VERSION "ZCUD_CANFD3"

NS_ :

BS_:

BU_: ASDM ETC HVFM SRS3 SUM XCM ZCUD ZCUT

BO_ 1418 EtcToSumXcpFr01: 8 ETC

BO_ 1604 HvfmToZcudZCUDCANFD3DiagResFr: 64 HVFM
 SG_ HvfmToZcudZCUCanFD3DiagResNpdu : 7|512@0+ (1,0) [0|0] "" ZCUD

BO_ 769 HvfmZCUDCANFD3Fr01: 64 HVFM
 SG_ HvFanACLockFlt : 7|1@0+ (1,0) [0|1] "Unitless" XCM
 SG_ HvFanACLockFlt_UB : 6|1@0+ (1,0) [0|1] "" XCM
 SG_ HvFanActPwr : 71|10@0+ (20,0) [0|20460] "W" XCM
 SG_ HvFanActPwr_UB : 77|1@0+ (1,0) [0|1] "" XCM
 SG_ HvFanBlockFlt : 41|1@0+ (1,0) [0|1] "Unitless" XCM
 SG_ HvFanBlockFlt_UB : 40|1@0+ (1,0) [0|1] "" XCM
 SG_ HvFanBusOffFlt : 57|1@0+ (1,0) [0|1] "Unitless" XCM
 SG_ HvFanBusOffFlt_UB : 56|1@0+ (1,0) [0|1] "" XCM
 SG_ HvFanCalFlt : 81|1@0+ (1,0) [0|1] "Unitless" XCM
 SG_ HvFanCalFlt_UB : 80|1@0+ (1,0) [0|1] "" XCM
 SG_ HvFanChks : 135|8@0+ (1,0) [0|255] "Unitless" XCM
 SG_ HvFanChks_UB : 0|1@0+ (1,0) [0|1] "" XCM
 SG_ HvFanCntr : 5|4@0+ (1,0) [0|15] "Unitless" XCM
 SG_ HvFanCntr_UB : 1|1@0+ (1,0) [0|1] "" XCM
 SG_ HvFanControllerT : 143|8@0+ (1,-40) [-40|215] "degC" XCM
 SG_ HvFanControllerT_UB : 168|1@0+ (1,0) [0|1] "" XCM
 SG_ HvFanCurrentIctrlFlt : 105|1@0+ (1,0) [0|1] "Unitless" XCM
 SG_ HvFanCurrentIctrlFlt_UB : 104|1@0+ (1,0) [0|1] "" XCM
 SG_ HvFanCurrentIsOCFlt : 121|1@0+ (1,0) [0|1] "Unitless" XCM
 SG_ HvFanCurrentIsOCFlt_UB : 120|1@0+ (1,0) [0|1] "" XCM
 SG_ HvFanCurrentSumFlt : 172|1@0+ (1,0) [0|1] "Unitless" XCM
 SG_ HvFanCurrentSumFlt_UB : 171|1@0+ (1,0) [0|1] "" XCM
 SG_ HvFanDCBusOVFlt : 170|1@0+ (1,0) [0|1] "Unitless" XCM
 SG_ HvFanDCBusOVFlt_UB : 169|1@0+ (1,0) [0|1] "" XCM
 SG_ HvFanDCBusOVWarn : 183|1@0+ (1,0) [0|1] "Unitless" XCM
 SG_ HvFanDCBusOVWarn_UB : 182|1@0+ (1,0) [0|1] "" XCM
 SG_ HvFanDCBusUVFlt : 181|1@0+ (1,0) [0|1] "Unitless" XCM
 SG_ HvFanDCBusUVFlt_UB : 180|1@0+ (1,0) [0|1] "" XCM
 SG_ HvFanDCBusUVWarn : 179|1@0+ (1,0) [0|1] "Unitless" XCM
 SG_ HvFanDCBusUVWarn_UB : 178|1@0+ (1,0) [0|1] "" XCM
 SG_ HvFanDCCrt : 76|10@0+ (0.1,0) [0|102.3] "A" XCM
 SG_ HvFanDCCrt_UB : 82|1@0+ (1,0) [0|1] "" XCM
 SG_ HvFanDCLockFlt : 177|1@0+ (1,0) [0|1] "Unitless" XCM
 SG_ HvFanDCLockFlt_UB : 176|1@0+ (1,0) [0|1] "" XCM
 SG_ HvFanDCVolt : 39|13@0+ (0.2,0) [0|1200] "Volt" XCM
 SG_ HvFanDCVolt_UB : 42|1@0+ (1,0) [0|1] "" XCM
 SG_ HvFanDriveFlt : 191|1@0+ (1,0) [0|1] "Unitless" XCM
 SG_ HvFanDriveFlt_UB : 190|1@0+ (1,0) [0|1] "" XCM
 SG_ HvFanFaultClass : 124|2@0+ (1,0) [0|3] "Unitless" XCM
 SG_ HvFanFaultClass_UB : 122|1@0+ (1,0) [0|1] "" XCM
 SG_ HvFanFltNum : 15|24@0+ (1,0) [0|16777215] "Unitless" XCM
 SG_ HvFanFltNum_UB : 221|1@0+ (1,0) [0|1] "" XCM
 SG_ HvFanHeartBeatFlt : 189|1@0+ (1,0) [0|1] "Unitless" XCM
 SG_ HvFanHeartBeatFlt_UB : 188|1@0+ (1,0) [0|1] "" XCM
 SG_ HvFanHVLKFlt : 187|1@0+ (1,0) [0|1] "" XCM
 SG_ HvFanHVLKFlt_UB : 186|1@0+ (1,0) [0|1] "" XCM
 SG_ HvFanHWProtectFlt : 185|1@0+ (1,0) [0|1] "Unitless" XCM
 SG_ HvFanHWProtectFlt_UB : 184|1@0+ (1,0) [0|1] "" XCM
 SG_ HvFanInverterOTFlt : 199|1@0+ (1,0) [0|1] "Unitless" XCM
 SG_ HvFanInverterOTFlt_UB : 198|1@0+ (1,0) [0|1] "" XCM
 SG_ HvFanInverterOTWarn : 197|1@0+ (1,0) [0|1] "Unitless" XCM
 SG_ HvFanInverterOTWarn_UB : 196|1@0+ (1,0) [0|1] "" XCM
 SG_ HvFanLifebeat : 195|1@0+ (1,0) [0|1] "" XCM
 SG_ HvFanLifebeat_UB : 194|1@0+ (1,0) [0|1] "" XCM
 SG_ HvFanLVSupOVFlt : 193|1@0+ (1,0) [0|1] "Unitless" XCM
 SG_ HvFanLVSupOVFlt_UB : 192|1@0+ (1,0) [0|1] "" XCM
 SG_ HvFanLVSupUVFlt : 207|1@0+ (1,0) [0|1] "Unitless" XCM
 SG_ HvFanLVSupUVFlt_UB : 206|1@0+ (1,0) [0|1] "" XCM
 SG_ HvFanMotCrt : 95|10@0+ (0.1,0) [0|102.3] "A" XCM
 SG_ HvFanMotCrt_UB : 101|1@0+ (1,0) [0|1] "" XCM
 SG_ HvFanMotPwr : 100|10@0+ (20,0) [0|20460] "W" XCM
 SG_ HvFanMotPwr_UB : 106|1@0+ (1,0) [0|1] "" XCM
 SG_ HvFanMotT : 151|8@0+ (1,-40) [-40|215] "degC" XCM
 SG_ HvFanMotT_UB : 220|1@0+ (1,0) [0|1] "" XCM
 SG_ HvFanMotVolt : 55|13@0+ (0.2,0) [0|1200] "Volt" XCM
 SG_ HvFanMotVolt_UB : 58|1@0+ (1,0) [0|1] "" XCM
 SG_ HvFanNoCal : 205|1@0+ (1,0) [0|1] "Unitless" XCM
 SG_ HvFanNoCal_UB : 204|1@0+ (1,0) [0|1] "" XCM
 SG_ HvFanOSFlt : 203|1@0+ (1,0) [0|1] "Unitless" XCM
 SG_ HvFanOSFlt_UB : 202|1@0+ (1,0) [0|1] "" XCM
 SG_ HvFanOSWarn : 201|1@0+ (1,0) [0|1] "Unitless" XCM
 SG_ HvFanOSWarn_UB : 200|1@0+ (1,0) [0|1] "" XCM
 SG_ HvFanOTFlt : 215|1@0+ (1,0) [0|1] "Unitless" XCM
 SG_ HvFanOTFlt_UB : 214|1@0+ (1,0) [0|1] "" XCM
 SG_ HvFanOTWarm : 213|1@0+ (1,0) [0|1] "Unitless" XCM
 SG_ HvFanOTWarm_UB : 212|1@0+ (1,0) [0|1] "" XCM
 SG_ HvFanPhaseOCFlt : 211|1@0+ (1,0) [0|1] "Unitless" XCM
 SG_ HvFanPhaseOCFlt_UB : 210|1@0+ (1,0) [0|1] "" XCM
 SG_ HvFanPwrReq : 119|10@0+ (20,0) [0|20460] "W" XCM
 SG_ HvFanPwrReq_UB : 125|1@0+ (1,0) [0|1] "" XCM
 SG_ HvFanSpdFb : 159|7@0+ (1,0) [0|100] "%" XCM
 SG_ HvFanSpdFb_UB : 152|1@0+ (1,0) [0|1] "" XCM
 SG_ HvFanStartFlt : 209|1@0+ (1,0) [0|1] "Unitless" XCM
 SG_ HvFanStartFlt_UB : 208|1@0+ (1,0) [0|1] "" XCM
 SG_ HvFanSts : 175|2@0+ (1,0) [0|3] "Unitless" XCM
 SG_ HvFanSts_UB : 173|1@0+ (1,0) [0|1] "" XCM
 SG_ HvFanTotFltNum : 167|8@0+ (1,0) [0|255] "Unitless" XCM
 SG_ HvFanTotFltNum_UB : 219|1@0+ (1,0) [0|1] "" XCM
 SG_ HvFanWindOSWarn : 223|1@0+ (1,0) [0|1] "Unitless" XCM
 SG_ HvFanWindOSWarn_UB : 222|1@0+ (1,0) [0|1] "" XCM
 SG_ HVFMMissingSlaveSignal : 218|1@0+ (1,0) [0|1] "" ZCUD
 SG_ HVFMMissingSlaveSignal_UB : 217|1@0+ (1,0) [0|1] "" ZCUD

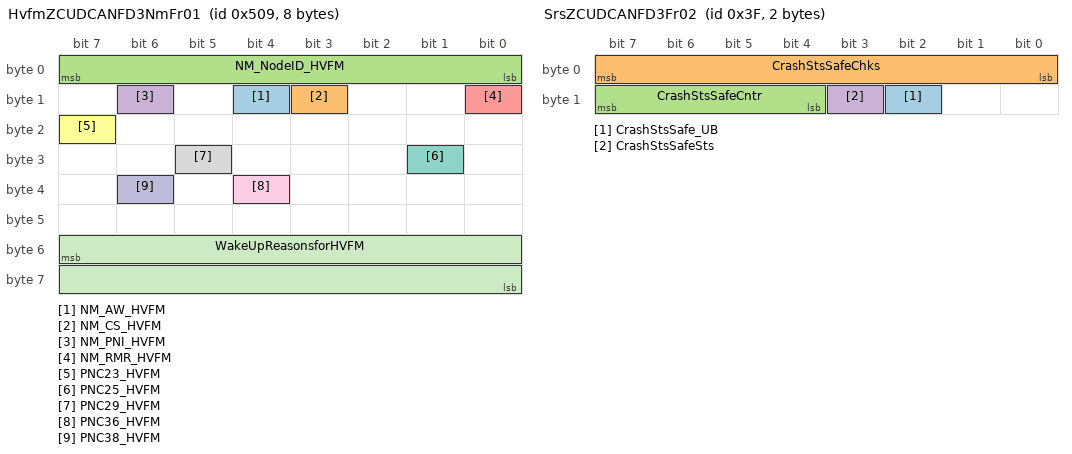
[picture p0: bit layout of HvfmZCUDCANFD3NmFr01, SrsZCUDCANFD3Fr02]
BO_ 1289 HvfmZCUDCANFD3NmFr01: 8 HVFM
 SG_ NM_AW_HVFM : 12|1@0+ (1,0) [0|0] "" ZCUT
 SG_ NM_CS_HVFM : 11|1@0+ (1,0) [0|0] "" ZCUT
 SG_ NM_NodeID_HVFM : 7|8@0+ (1,0) [0|0] "" ZCUT
 SG_ NM_PNI_HVFM : 14|1@0+ (1,0) [0|0] "" ZCUT
 SG_ NM_RMR_HVFM : 8|1@0+ (1,0) [0|0] "" ZCUT
 SG_ PNC23_HVFM : 23|1@0+ (1,0) [0|0] "" ZCUT
 SG_ PNC25_HVFM : 25|1@0+ (1,0) [0|0] "" ZCUT
 SG_ PNC29_HVFM : 29|1@0+ (1,0) [0|0] "" ZCUT
 SG_ PNC36_HVFM : 36|1@0+ (1,0) [0|0] "" ZCUT
 SG_ PNC38_HVFM : 38|1@0+ (1,0) [0|0] "" ZCUT
 SG_ WakeUpReasonsforHVFM : 55|16@0+ (1,0) [0|65535] "" Vector__XXX

BO_ 1353 HvfmZCUDCANFD3VFCVectorFr: 8 HVFM
 SG_ VFCVectorHVFMBlockID : 7|2@0+ (1,0) [0|3] "Unitless" ZCUD
 SG_ VFCVectorHVFMVFCid0 : 5|1@0+ (1,0) [0|1] "" ZCUD
 SG_ VFCVectorHVFMVFCid1 : 4|1@0+ (1,0) [0|1] "" ZCUD
 SG_ VFCVectorHVFMVFCid10 : 11|1@0+ (1,0) [0|1] "" ZCUD
 SG_ VFCVectorHVFMVFCid11 : 10|1@0+ (1,0) [0|1] "" ZCUD
 SG_ VFCVectorHVFMVFCid12 : 9|1@0+ (1,0) [0|1] "" ZCUD
 SG_ VFCVectorHVFMVFCid13 : 8|1@0+ (1,0) [0|1] "" ZCUD
 SG_ VFCVectorHVFMVFCid14 : 23|1@0+ (1,0) [0|1] "" ZCUD
 SG_ VFCVectorHVFMVFCid15 : 22|1@0+ (1,0) [0|1] "" ZCUD
 SG_ VFCVectorHVFMVFCid16 : 21|1@0+ (1,0) [0|1] "" ZCUD
 SG_ VFCVectorHVFMVFCid17 : 20|1@0+ (1,0) [0|1] "" ZCUD
 SG_ VFCVectorHVFMVFCid18 : 19|1@0+ (1,0) [0|1] "" ZCUD
 SG_ VFCVectorHVFMVFCid19 : 18|1@0+ (1,0) [0|1] "" ZCUD
 SG_ VFCVectorHVFMVFCid2 : 3|1@0+ (1,0) [0|1] "" ZCUD
 SG_ VFCVectorHVFMVFCid20 : 17|1@0+ (1,0) [0|1] "" ZCUD
 SG_ VFCVectorHVFMVFCid21 : 16|1@0+ (1,0) [0|1] "" ZCUD
 SG_ VFCVectorHVFMVFCid22 : 31|1@0+ (1,0) [0|1] "" ZCUD
 SG_ VFCVectorHVFMVFCid23 : 30|1@0+ (1,0) [0|1] "" ZCUD
 SG_ VFCVectorHVFMVFCid24 : 29|1@0+ (1,0) [0|1] "" ZCUD
 SG_ VFCVectorHVFMVFCid25 : 28|1@0+ (1,0) [0|1] "" ZCUD
 SG_ VFCVectorHVFMVFCid26 : 27|1@0+ (1,0) [0|1] "" ZCUD
 SG_ VFCVectorHVFMVFCid27 : 26|1@0+ (1,0) [0|1] "" ZCUD
 SG_ VFCVectorHVFMVFCid28 : 25|1@0+ (1,0) [0|1] "" ZCUD
 SG_ VFCVectorHVFMVFCid29 : 24|1@0+ (1,0) [0|1] "" ZCUD
 SG_ VFCVectorHVFMVFCid3 : 2|1@0+ (1,0) [0|1] "" ZCUD
 SG_ VFCVectorHVFMVFCid30 : 39|1@0+ (1,0) [0|1] "" ZCUD
 SG_ VFCVectorHVFMVFCid31 : 38|1@0+ (1,0) [0|1] "" ZCUD
 SG_ VFCVectorHVFMVFCid32 : 37|1@0+ (1,0) [0|1] "" ZCUD
 SG_ VFCVectorHVFMVFCid33 : 36|1@0+ (1,0) [0|1] "" ZCUD
 SG_ VFCVectorHVFMVFCid34 : 35|1@0+ (1,0) [0|1] "" ZCUD
 SG_ VFCVectorHVFMVFCid35 : 34|1@0+ (1,0) [0|1] "" ZCUD
 SG_ VFCVectorHVFMVFCid36 : 33|1@0+ (1,0) [0|1] "" ZCUD
 SG_ VFCVectorHVFMVFCid37 : 32|1@0+ (1,0) [0|1] "" ZCUD
 SG_ VFCVectorHVFMVFCid38 : 47|1@0+ (1,0) [0|1] "" ZCUD
 SG_ VFCVectorHVFMVFCid39 : 46|1@0+ (1,0) [0|1] "" ZCUD
 SG_ VFCVectorHVFMVFCid4 : 1|1@0+ (1,0) [0|1] "" ZCUD
 SG_ VFCVectorHVFMVFCid40 : 45|1@0+ (1,0) [0|1] "" ZCUD
 SG_ VFCVectorHVFMVFCid41 : 44|1@0+ (1,0) [0|1] "" ZCUD
 SG_ VFCVectorHVFMVFCid42 : 43|1@0+ (1,0) [0|1] "" ZCUD
 SG_ VFCVectorHVFMVFCid43 : 42|1@0+ (1,0) [0|1] "" ZCUD
 SG_ VFCVectorHVFMVFCid44 : 41|1@0+ (1,0) [0|1] "" ZCUD
 SG_ VFCVectorHVFMVFCid45 : 40|1@0+ (1,0) [0|1] "" ZCUD
 SG_ VFCVectorHVFMVFCid46 : 55|1@0+ (1,0) [0|1] "" ZCUD
 SG_ VFCVectorHVFMVFCid47 : 54|1@0+ (1,0) [0|1] "" ZCUD
 SG_ VFCVectorHVFMVFCid48 : 53|1@0+ (1,0) [0|1] "" ZCUD
 SG_ VFCVectorHVFMVFCid49 : 52|1@0+ (1,0) [0|1] "" ZCUD
 SG_ VFCVectorHVFMVFCid5 : 0|1@0+ (1,0) [0|1] "" ZCUD
 SG_ VFCVectorHVFMVFCid50 : 51|1@0+ (1,0) [0|1] "" ZCUD
 SG_ VFCVectorHVFMVFCid51 : 50|1@0+ (1,0) [0|1] "" ZCUD
 SG_ VFCVectorHVFMVFCid52 : 49|1@0+ (1,0) [0|1] "" ZCUD
 SG_ VFCVectorHVFMVFCid53 : 48|1@0+ (1,0) [0|1] "" ZCUD
 SG_ VFCVectorHVFMVFCid54 : 63|1@0+ (1,0) [0|1] "" ZCUD
 SG_ VFCVectorHVFMVFCid55 : 62|1@0+ (1,0) [0|1] "" ZCUD
 SG_ VFCVectorHVFMVFCid56 : 61|1@0+ (1,0) [0|1] "" ZCUD
 SG_ VFCVectorHVFMVFCid57 : 60|1@0+ (1,0) [0|1] "" ZCUD
 SG_ VFCVectorHVFMVFCid58 : 59|1@0+ (1,0) [0|1] "" ZCUD
 SG_ VFCVectorHVFMVFCid59 : 58|1@0+ (1,0) [0|1] "" ZCUD
 SG_ VFCVectorHVFMVFCid6 : 15|1@0+ (1,0) [0|1] "" ZCUD
 SG_ VFCVectorHVFMVFCid60 : 57|1@0+ (1,0) [0|1] "" ZCUD
 SG_ VFCVectorHVFMVFCid61 : 56|1@0+ (1,0) [0|1] "" ZCUD
 SG_ VFCVectorHVFMVFCid7 : 14|1@0+ (1,0) [0|1] "" ZCUD
 SG_ VFCVectorHVFMVFCid8 : 13|1@0+ (1,0) [0|1] "" ZCUD
 SG_ VFCVectorHVFMVFCid9 : 12|1@0+ (1,0) [0|1] "" ZCUD

BO_ 81 IemZCUDCANFD3Fr02: 64 XCM
 SG_ TVCBrkTqReq_UB : 203|1@0+ (1,0) [0|1] "" ZCUD
 SG_ TVCBrkTqReqChks : 191|8@0+ (1,0) [0|255] "Unitless" ZCUD
 SG_ TVCBrkTqReqCntr : 199|4@0+ (1,0) [0|15] "Unitless" ZCUD
 SG_ TVCBrkTqReqFrntLe : 143|12@0+ (4,0) [0|16380] "Nm" ZCUD
 SG_ TVCBrkTqReqFrntLeCtrlMod : 195|2@0+ (1,0) [0|3] "" ZCUD
 SG_ TVCBrkTqReqFrntRi : 147|12@0+ (4,0) [0|16380] "Nm" ZCUD
 SG_ TVCBrkTqReqFrntRiCtrlMod : 193|2@0+ (1,0) [0|3] "" ZCUD
 SG_ TVCBrkTqReqReLe : 167|12@0+ (4,0) [0|16380] "Nm" ZCUD
 SG_ TVCBrkTqReqReLeCtrlMod : 207|2@0+ (1,0) [0|3] "" ZCUD
 SG_ TVCBrkTqReqReRi : 171|12@0+ (4,0) [0|16380] "Nm" ZCUD
 SG_ TVCBrkTqReqReRiCtrlMod : 205|2@0+ (1,0) [0|3] "" ZCUD
 SG_ TVCBrkTqReqWhlVAgrMinReqFrntLe : 79|16@0- (0.0078125,0) [-255|255] "rad/s" ZCUD
 SG_ TVCBrkTqReqWhlVAgrMinReqFrntRi : 95|16@0- (0.0078125,0) [-255|255] "rad/s" ZCUD
 SG_ TVCBrkTqReqWhlVAgrMinReqReLe : 111|16@0- (0.0078125,0) [-255|255] "rad/s" ZCUD
 SG_ TVCBrkTqReqWhlVAgrMinReqReRi : 127|16@0- (0.0078125,0) [-255|255] "rad/s" ZCUD
 SG_ TVCPrpsnTqDistActv : 25|1@0+ (1,0) [0|1] "" ZCUD
 SG_ TVCPrpsnTqDistActv_UB : 24|1@0+ (1,0) [0|1] "" ZCUD
 SG_ TVCPrpsnTqDistRatio : 55|8@0+ (1,0) [0|100] "%" ZCUD
 SG_ TVCPrpsnTqDistRatio_UB : 63|1@0+ (1,0) [0|1] "" ZCUD
 SG_ TVCReWhlSteerCtrlStsForTvc_UB : 40|1@0+ (1,0) [0|1] "" ZCUD
 SG_ TVCReWhlSteerCtrlStsForTvcChks : 39|8@0+ (1,0) [0|255] "Unitless" ZCUD
 SG_ TVCReWhlSteerCtrlStsForTvcCntr : 47|4@0+ (1,0) [0|15] "Unitless" ZCUD
 SG_ TVCReWhlSteerCtrlStsForTvcTVCReWhlSteerCtrlStsForTvc : 43|3@0+ (1,0) [0|7] "" ZCUD
 SG_ TVCRwsAngReqForTvc_UB : 28|1@0+ (1,0) [0|1] "" ZCUD
 SG_ TVCRwsAngReqForTvcChks : 8|8@0+ (1,0) [0|255] "Unitless" ZCUD
 SG_ TVCRwsAngReqForTvcCntr : 16|4@0+ (1,0) [0|15] "Unitless" ZCUD
 SG_ TVCRwsAngReqForTvcTVCRwsAngReqForTvc : 7|15@0- (0.001,0) [-16.384|16.383] "Deg" ZCUD
 SG_ TVCTqDistbnFaultForGVMC_UB : 62|1@0+ (1,0) [0|1] "" ZCUD
 SG_ TVCTqDistbnFaultForGVMCChks : 71|8@0+ (1,0) [0|255] "Unitless" ZCUD
 SG_ TVCTqDistbnFaultForGVMCCntr : 61|4@0+ (1,0) [0|15] "Unitless" ZCUD
 SG_ TVCTqDistbnFaultForGVMCTVCTqDistbnFaultForGVMC : 57|2@0+ (1,0) [0|3] "" ZCUD

BO_ 257 IemZCUDCANFD3Fr03: 64 XCM
 SG_ FasPwrAllwd : 207|9@0+ (100,0) [0|51100] "W" ZCUT
 SG_ FasPwrAllwd_UB : 214|1@0+ (1,0) [0|1] "" ZCUT
 SG_ MotDynCtrlStsReLe_UB : 87|1@0+ (1,0) [0|1] "" ZCUD,ZCUT
 SG_ MotDynCtrlStsReLeChks : 143|8@0+ (1,0) [0|255] "Unitless" ZCUD,ZCUT
 SG_ MotDynCtrlStsReLeCntr : 151|4@0+ (1,0) [0|15] "Unitless" ZCUD,ZCUT
 SG_ MotDynCtrlStsReLeDmcActAppTarTq : 111|16@0- (1,0) [-30000|30000] "NewtonMeter" ZCUD,ZCUT
 SG_ MotDynCtrlStsReLeDmcSts : 147|4@0+ (1,0) [0|15] "" ZCUD,ZCUT
 SG_ MotDynCtrlStsReLeDmcSWInfo : 127|16@0+ (1,0) [0|65535] "Unitless" ZCUD,ZCUT
 SG_ MotDynCtrlStsReRi_UB : 86|1@0+ (1,0) [0|1] "" ZCUD,ZCUT
 SG_ MotDynCtrlStsReRiChks : 191|8@0+ (1,0) [0|255] "Unitless" ZCUD,ZCUT
 SG_ MotDynCtrlStsReRiCntr : 199|4@0+ (1,0) [0|15] "Unitless" ZCUD,ZCUT
 SG_ MotDynCtrlStsReRiDmcActAppTarTq : 159|16@0- (1,0) [-30000|30000] "NewtonMeter" ZCUD,ZCUT
 SG_ MotDynCtrlStsReRiDmcSts : 195|4@0+ (1,0) [0|15] "" ZCUD,ZCUT
 SG_ MotDynCtrlStsReRiDmcSWInfo : 175|16@0+ (1,0) [0|65535] "Unitless" ZCUD,ZCUT
 SG_ TVCEradLeMaxAvailWhl : 7|12@0+ (4,-8188) [-8188|8192] "NewtonMeter" ZCUD
 SG_ TVCEradLeMaxAvailWhl_UB : 88|1@0+ (1,0) [0|1] "" ZCUD
 SG_ TVCEradLeMinAvailWhl : 11|12@0+ (4,-8188) [-8188|8192] "NewtonMeter" ZCUD
 SG_ TVCEradLeMinAvailWhl_UB : 89|1@0+ (1,0) [0|1] "" ZCUD
 SG_ TVCEradLeReqWhl : 31|15@0- (0.6103515625,0) [-10000|9999.3896484375] "NewtonMeter" ZCUD
 SG_ TVCEradLeReqWhl_UB : 32|1@0+ (1,0) [0|1] "" ZCUD
 SG_ TVCEradRiMaxAvailWhl : 63|12@0+ (4,-8188) [-8188|8192] "NewtonMeter" ZCUD
 SG_ TVCEradRiMaxAvailWhl_UB : 90|1@0+ (1,0) [0|1] "" ZCUD
 SG_ TVCEradRiMinAvailWhl : 67|12@0+ (4,-8188) [-8188|8192] "NewtonMeter" ZCUD
 SG_ TVCEradRiMinAvailWhl_UB : 91|1@0+ (1,0) [0|1] "" ZCUD
 SG_ TVCEradRiReqWhl : 47|15@0- (0.6103515625,0) [-10000|9999.3896484375] "NewtonMeter" ZCUD
 SG_ TVCEradRiReqWhl_UB : 48|1@0+ (1,0) [0|1] "" ZCUD

BO_ 50 SrsZCUDCANFD3Fr01: 64 SRS3
 SG_ ADataRawSafe_UB : 7|1@0+ (1,0) [0|1] "" ZCUT
 SG_ ADataRawSafeALat : 6|15@0- (0.0085,0) [-138.992|139.0005] "m/s^2" ZCUT
 SG_ ADataRawSafeALat1Qf : 43|2@0+ (1,0) [0|3] "" ZCUT
 SG_ ADataRawSafeALgt : 23|15@0- (0.0085,0) [-138.992|139.0005] "m/s^2" ZCUT
 SG_ ADataRawSafeALgt1Qf : 41|2@0+ (1,0) [0|3] "" ZCUT
 SG_ ADataRawSafeAVert : 55|15@0- (0.0085,0) [-138.992|139.0005] "m/s^2" ZCUT
 SG_ ADataRawSafeAVertQf : 71|2@0+ (1,0) [0|3] "" ZCUT
 SG_ ADataRawSafeChks : 39|8@0+ (1,0) [0|255] "Unitless" ZCUT
 SG_ ADataRawSafeCntr : 47|4@0+ (1,0) [0|15] "Unitless" ZCUT
 SG_ AgDataRawSafe_UB : 69|1@0+ (1,0) [0|1] "" ZCUT
 SG_ AgDataRawSafeChks : 111|8@0+ (1,0) [0|255] "Unitless" ZCUT
 SG_ AgDataRawSafeCntr : 119|4@0+ (1,0) [0|15] "Unitless" ZCUT
 SG_ AgDataRawSafeRollRate : 79|16@0- (2.44140625E-4,0) [-6|6] "rad/s" ZCUT
 SG_ AgDataRawSafeRollRateQf : 115|2@0+ (1,0) [0|3] "" ZCUT
 SG_ AgDataRawSafeYawRate : 95|16@0- (2.44140625E-4,0) [-6|6] "rad/s" ZCUT
 SG_ AgDataRawSafeYawRateQf : 113|2@0+ (1,0) [0|3] "" ZCUT
 SG_ AsyDataWithCmpSafe_UB : 176|1@0+ (1,0) [0|1] "" Vector__XXX
 SG_ AsyDataWithCmpSafeALat1Qf : 182|2@0+ (1,0) [0|3] "" Vector__XXX
 SG_ AsyDataWithCmpSafeALatWithCmp : 143|15@0- (0.0085,0) [-138.992|139.0005] "m/s^2" Vector__XXX
 SG_ AsyDataWithCmpSafeALgt1Qf : 180|2@0+ (1,0) [0|3] "" Vector__XXX
 SG_ AsyDataWithCmpSafeChks : 162|8@0+ (1,0) [0|255] "Unitless" Vector__XXX
 SG_ AsyDataWithCmpSafeCntr : 170|4@0+ (1,0) [0|15] "Unitless" Vector__XXX
 SG_ AsyDataWithCmpSafeGrdtOfALgt : 144|14@0- (0.00390625,0) [-30|30] "m/s^3" Vector__XXX
 SG_ AsyDataWithCmpSafeYawRateQf : 178|2@0+ (1,0) [0|3] "" Vector__XXX
 SG_ AsyDataWithCmpSafeYawRateWithCmp : 127|16@0- (2.44140625E-4,0) [-6|6] "rad/s" Vector__XXX
 SG_ IntgtIMUDataRawSafe_UB : 298|1@0+ (1,0) [0|1] "" XCM,ZCUD,ZCUT
 SG_ IntgtIMUDataRawSafeALat : 239|15@0- (0.0085,0) [-138.992|139.0005] "m/s^2" XCM,ZCUD,ZCUT
 SG_ IntgtIMUDataRawSafeALat1Qf : 294|2@0+ (1,0) [0|3] "" XCM,ZCUD,ZCUT
 SG_ IntgtIMUDataRawSafeALgt : 240|15@0- (0.0085,0) [-138.992|139.0005] "m/s^2" XCM,ZCUD,ZCUT
 SG_ IntgtIMUDataRawSafeALgt1Qf : 292|2@0+ (1,0) [0|3] "" XCM,ZCUD,ZCUT
 SG_ IntgtIMUDataRawSafeAvert : 257|15@0- (0.0085,0) [-138.992|139.0005] "m/s^2" XCM,ZCUD,ZCUT
 SG_ IntgtIMUDataRawSafeAVertQf : 290|2@0+ (1,0) [0|3] "" XCM,ZCUD,ZCUT
 SG_ IntgtIMUDataRawSafeChks : 274|8@0+ (1,0) [0|255] "Unitless" XCM,ZCUD,ZCUT
 SG_ IntgtIMUDataRawSafeCntr : 282|4@0+ (1,0) [0|15] "Unitless" XCM,ZCUD,ZCUT
 SG_ IntgtIMUDataRawSafePitchRate : 191|16@0- (2.44140625E-4,0) [-6|6] "rad/s" XCM,ZCUD,ZCUT
 SG_ IntgtIMUDataRawSafePitchRateQf : 288|2@0+ (1,0) [0|3] "" XCM,ZCUD,ZCUT
 SG_ IntgtIMUDataRawSafeRollRate : 207|16@0- (2.44140625E-4,0) [-6|6] "rad/s" XCM,ZCUD,ZCUT
 SG_ IntgtIMUDataRawSafeRollRateQf : 302|2@0+ (1,0) [0|3] "" XCM,ZCUD,ZCUT
 SG_ IntgtIMUDataRawSafeYawRate : 223|16@0- (2.44140625E-4,0) [-6|6] "rad/s" XCM,ZCUD,ZCUT
 SG_ IntgtIMUDataRawSafeYawRateQf : 300|2@0+ (1,0) [0|3] "" XCM,ZCUD,ZCUT

BO_ 63 SrsZCUDCANFD3Fr02: 2 SRS3
 SG_ CrashStsSafe_UB : 10|1@0+ (1,0) [0|1] "" Vector__XXX
 SG_ CrashStsSafeChks : 7|8@0+ (1,0) [0|255] "Unitless" Vector__XXX
 SG_ CrashStsSafeCntr : 15|4@0+ (1,0) [0|15] "Unitless" Vector__XXX
 SG_ CrashStsSafeSts : 11|1@0+ (1,0) [0|1] "" Vector__XXX

BO_ 553 SrsZCUDCANFD3Fr03: 64 SRS3
 SG_ AgDataCmpQuality_UB : 31|1@0+ (1,0) [0|1] "" Vector__XXX
 SG_ AgDataCmpQualityPitchRateCmpQuality : 7|8@0+ (1,0) [0|255] "Unitless" Vector__XXX
 SG_ AgDataCmpQualityRollRateCmpQuality : 15|8@0+ (1,0) [0|255] "Unitless" Vector__XXX
 SG_ AgDataCmpQualityYawRateCmpQuality : 23|8@0+ (1,0) [0|255] "Unitless" Vector__XXX

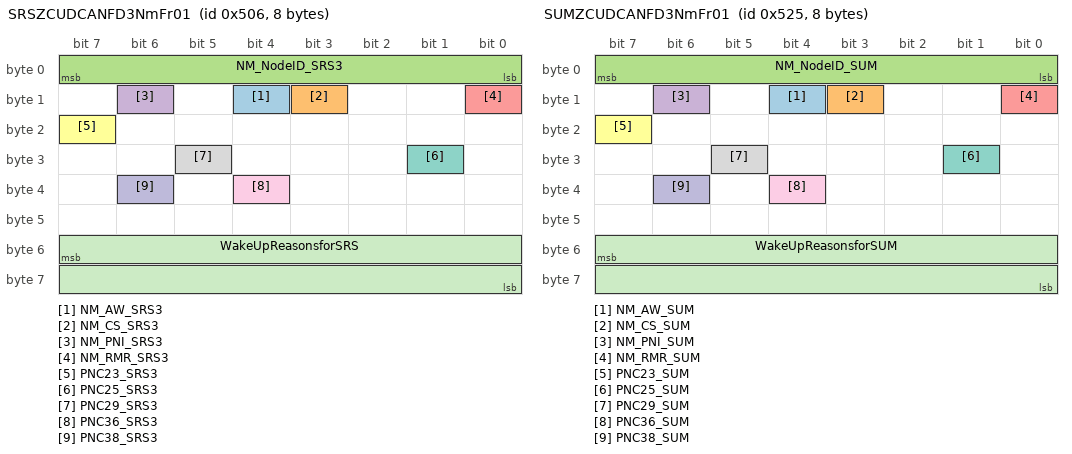
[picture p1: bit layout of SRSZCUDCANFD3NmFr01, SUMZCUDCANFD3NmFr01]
BO_ 1286 SRSZCUDCANFD3NmFr01: 8 SRS3
 SG_ NM_AW_SRS3 : 12|1@0+ (1,0) [0|0] "" Vector__XXX
 SG_ NM_CS_SRS3 : 11|1@0+ (1,0) [0|0] "" Vector__XXX
 SG_ NM_NodeID_SRS3 : 7|8@0+ (1,0) [0|0] "" Vector__XXX
 SG_ NM_PNI_SRS3 : 14|1@0+ (1,0) [0|0] "" Vector__XXX
 SG_ NM_RMR_SRS3 : 8|1@0+ (1,0) [0|0] "" Vector__XXX
 SG_ PNC23_SRS3 : 23|1@0+ (1,0) [0|0] "" Vector__XXX
 SG_ PNC25_SRS3 : 25|1@0+ (1,0) [0|0] "" Vector__XXX
 SG_ PNC29_SRS3 : 29|1@0+ (1,0) [0|0] "" Vector__XXX
 SG_ PNC36_SRS3 : 36|1@0+ (1,0) [0|0] "" Vector__XXX
 SG_ PNC38_SRS3 : 38|1@0+ (1,0) [0|0] "" Vector__XXX
 SG_ WakeUpReasonsforSRS : 55|16@0+ (1,0) [0|65535] "" Vector__XXX

BO_ 1350 SrsZCUDCANFD3VFCVectorFr: 8 SRS3
 SG_ VFCVectorSRSBlockID : 7|2@0+ (1,0) [0|3] "Unitless" Vector__XXX
 SG_ VFCVectorSRSVFCid0 : 5|1@0+ (1,0) [0|1] "" Vector__XXX
 SG_ VFCVectorSRSVFCid1 : 4|1@0+ (1,0) [0|1] "" Vector__XXX
 SG_ VFCVectorSRSVFCid10 : 11|1@0+ (1,0) [0|1] "" Vector__XXX
 SG_ VFCVectorSRSVFCid11 : 10|1@0+ (1,0) [0|1] "" Vector__XXX
 SG_ VFCVectorSRSVFCid12 : 9|1@0+ (1,0) [0|1] "" Vector__XXX
 SG_ VFCVectorSRSVFCid13 : 8|1@0+ (1,0) [0|1] "" Vector__XXX
 SG_ VFCVectorSRSVFCid14 : 23|1@0+ (1,0) [0|1] "" Vector__XXX
 SG_ VFCVectorSRSVFCid15 : 22|1@0+ (1,0) [0|1] "" Vector__XXX
 SG_ VFCVectorSRSVFCid16 : 21|1@0+ (1,0) [0|1] "" Vector__XXX
 SG_ VFCVectorSRSVFCid17 : 20|1@0+ (1,0) [0|1] "" Vector__XXX
 SG_ VFCVectorSRSVFCid18 : 19|1@0+ (1,0) [0|1] "" Vector__XXX
 SG_ VFCVectorSRSVFCid19 : 18|1@0+ (1,0) [0|1] "" Vector__XXX
 SG_ VFCVectorSRSVFCid2 : 3|1@0+ (1,0) [0|1] "" Vector__XXX
 SG_ VFCVectorSRSVFCid20 : 17|1@0+ (1,0) [0|1] "" Vector__XXX
 SG_ VFCVectorSRSVFCid21 : 16|1@0+ (1,0) [0|1] "" Vector__XXX
 SG_ VFCVectorSRSVFCid22 : 31|1@0+ (1,0) [0|1] "" Vector__XXX
 SG_ VFCVectorSRSVFCid23 : 30|1@0+ (1,0) [0|1] "" Vector__XXX
 SG_ VFCVectorSRSVFCid24 : 29|1@0+ (1,0) [0|1] "" Vector__XXX
 SG_ VFCVectorSRSVFCid25 : 28|1@0+ (1,0) [0|1] "" Vector__XXX
 SG_ VFCVectorSRSVFCid26 : 27|1@0+ (1,0) [0|1] "" Vector__XXX
 SG_ VFCVectorSRSVFCid27 : 26|1@0+ (1,0) [0|1] "" Vector__XXX
 SG_ VFCVectorSRSVFCid28 : 25|1@0+ (1,0) [0|1] "" Vector__XXX
 SG_ VFCVectorSRSVFCid29 : 24|1@0+ (1,0) [0|1] "" Vector__XXX
 SG_ VFCVectorSRSVFCid3 : 2|1@0+ (1,0) [0|1] "" Vector__XXX
 SG_ VFCVectorSRSVFCid30 : 39|1@0+ (1,0) [0|1] "" Vector__XXX
 SG_ VFCVectorSRSVFCid31 : 38|1@0+ (1,0) [0|1] "" Vector__XXX
 SG_ VFCVectorSRSVFCid32 : 37|1@0+ (1,0) [0|1] "" Vector__XXX
 SG_ VFCVectorSRSVFCid33 : 36|1@0+ (1,0) [0|1] "" Vector__XXX
 SG_ VFCVectorSRSVFCid34 : 35|1@0+ (1,0) [0|1] "" Vector__XXX
 SG_ VFCVectorSRSVFCid35 : 34|1@0+ (1,0) [0|1] "" Vector__XXX
 SG_ VFCVectorSRSVFCid36 : 33|1@0+ (1,0) [0|1] "" Vector__XXX
 SG_ VFCVectorSRSVFCid37 : 32|1@0+ (1,0) [0|1] "" Vector__XXX
 SG_ VFCVectorSRSVFCid38 : 47|1@0+ (1,0) [0|1] "" Vector__XXX
 SG_ VFCVectorSRSVFCid39 : 46|1@0+ (1,0) [0|1] "" Vector__XXX
 SG_ VFCVectorSRSVFCid4 : 1|1@0+ (1,0) [0|1] "" Vector__XXX
 SG_ VFCVectorSRSVFCid40 : 45|1@0+ (1,0) [0|1] "" Vector__XXX
 SG_ VFCVectorSRSVFCid41 : 44|1@0+ (1,0) [0|1] "" Vector__XXX
 SG_ VFCVectorSRSVFCid42 : 43|1@0+ (1,0) [0|1] "" Vector__XXX
 SG_ VFCVectorSRSVFCid43 : 42|1@0+ (1,0) [0|1] "" Vector__XXX
 SG_ VFCVectorSRSVFCid44 : 41|1@0+ (1,0) [0|1] "" Vector__XXX
 SG_ VFCVectorSRSVFCid45 : 40|1@0+ (1,0) [0|1] "" Vector__XXX
 SG_ VFCVectorSRSVFCid46 : 55|1@0+ (1,0) [0|1] "" Vector__XXX
 SG_ VFCVectorSRSVFCid47 : 54|1@0+ (1,0) [0|1] "" Vector__XXX
 SG_ VFCVectorSRSVFCid48 : 53|1@0+ (1,0) [0|1] "" Vector__XXX
 SG_ VFCVectorSRSVFCid49 : 52|1@0+ (1,0) [0|1] "" Vector__XXX
 SG_ VFCVectorSRSVFCid5 : 0|1@0+ (1,0) [0|1] "" Vector__XXX
 SG_ VFCVectorSRSVFCid50 : 51|1@0+ (1,0) [0|1] "" Vector__XXX
 SG_ VFCVectorSRSVFCid51 : 50|1@0+ (1,0) [0|1] "" Vector__XXX
 SG_ VFCVectorSRSVFCid52 : 49|1@0+ (1,0) [0|1] "" Vector__XXX
 SG_ VFCVectorSRSVFCid53 : 48|1@0+ (1,0) [0|1] "" Vector__XXX
 SG_ VFCVectorSRSVFCid54 : 63|1@0+ (1,0) [0|1] "" Vector__XXX
 SG_ VFCVectorSRSVFCid55 : 62|1@0+ (1,0) [0|1] "" Vector__XXX
 SG_ VFCVectorSRSVFCid56 : 61|1@0+ (1,0) [0|1] "" Vector__XXX
 SG_ VFCVectorSRSVFCid57 : 60|1@0+ (1,0) [0|1] "" Vector__XXX
 SG_ VFCVectorSRSVFCid58 : 59|1@0+ (1,0) [0|1] "" Vector__XXX
 SG_ VFCVectorSRSVFCid59 : 58|1@0+ (1,0) [0|1] "" Vector__XXX
 SG_ VFCVectorSRSVFCid6 : 15|1@0+ (1,0) [0|1] "" Vector__XXX
 SG_ VFCVectorSRSVFCid60 : 57|1@0+ (1,0) [0|1] "" Vector__XXX
 SG_ VFCVectorSRSVFCid61 : 56|1@0+ (1,0) [0|1] "" Vector__XXX
 SG_ VFCVectorSRSVFCid7 : 14|1@0+ (1,0) [0|1] "" Vector__XXX
 SG_ VFCVectorSRSVFCid8 : 13|1@0+ (1,0) [0|1] "" Vector__XXX
 SG_ VFCVectorSRSVFCid9 : 12|1@0+ (1,0) [0|1] "" Vector__XXX

BO_ 1417 SumToEtcXcpFr01: 8 SUM

BO_ 1601 SumToZcudZCUDCANFD3DiagResFr: 64 SUM
 SG_ SumToZcudZCUCanFD3DiagResNpdu : 7|512@0+ (1,0) [0|0] "" ZCUD

BO_ 448 SumZCUDCANFD3Fr04: 64 SUM
 SG_ AirSuspFltSts : 36|3@0+ (1,0) [0|7] "" ZCUD
 SG_ AirSuspFltSts_UB : 33|1@0+ (1,0) [0|1] "" ZCUD
 SG_ ReLvlSwt : 69|9@0+ (1,-100) [-100|411] "degC" ZCUD
 SG_ ReLvlSwt_UB : 76|1@0+ (1,0) [0|1] "" ZCUD
 SG_ SuspCmprSpdFb : 10|9@0+ (1,0) [0|511] "rpm" ZCUD
 SG_ SuspCmprSpdFb_UB : 17|1@0+ (1,0) [0|1] "" ZCUD
 SG_ SuspDistbnVlvCtrlStsFb : 7|12@0+ (1,0) [0|4095] "Unitless" ZCUD
 SG_ SuspDistbnVlvCtrlStsFb_UB : 11|1@0+ (1,0) [0|1] "" ZCUD
 SG_ SuspHumVal : 47|8@0+ (1,0) [0|255] "%" ZCUD
 SG_ SuspHumVal_UB : 16|1@0+ (1,0) [0|1] "" ZCUD
 SG_ SuspPVal : 31|9@0+ (0.1,0) [0|51.1] "bar" ZCUD
 SG_ SuspPVal_UB : 38|1@0+ (1,0) [0|1] "" ZCUD
 SG_ SuspStfnVlvCtrlStsFb_UB : 37|1@0+ (1,0) [0|1] "" ZCUD
 SG_ SuspStfnVlvCtrlStsFbFL : 55|2@0+ (1,0) [0|3] "" ZCUD
 SG_ SuspStfnVlvCtrlStsFbFR : 53|2@0+ (1,0) [0|3] "" ZCUD
 SG_ SuspStfnVlvCtrlStsFbRL : 51|2@0+ (1,0) [0|3] "" ZCUD
 SG_ SuspStfnVlvCtrlStsFbRR : 49|2@0+ (1,0) [0|3] "" ZCUD
 SG_ SuspTVal : 63|9@0+ (1,-100) [-100|411] "degC" ZCUD
 SG_ SuspTVal_UB : 70|1@0+ (1,0) [0|1] "" ZCUD

BO_ 528 SumZCUDCANFD3Fr05: 64 SUM
 SG_ SUMMissingSlaveSignal : 15|1@0+ (1,0) [0|1] "" ZCUD
 SG_ SUMMissingSlaveSignal_UB : 14|1@0+ (1,0) [0|1] "" ZCUD
 SG_ SuspCmprCurr : 7|8@0+ (1,0) [0|255] "A" ZCUD
 SG_ SuspCmprCurr_UB : 13|1@0+ (1,0) [0|1] "" ZCUD

BO_ 1317 SUMZCUDCANFD3NmFr01: 8 SUM
 SG_ NM_AW_SUM : 12|1@0+ (1,0) [0|0] "" SRS3
 SG_ NM_CS_SUM : 11|1@0+ (1,0) [0|0] "" SRS3
 SG_ NM_NodeID_SUM : 7|8@0+ (1,0) [0|0] "" SRS3
 SG_ NM_PNI_SUM : 14|1@0+ (1,0) [0|0] "" SRS3
 SG_ NM_RMR_SUM : 8|1@0+ (1,0) [0|0] "" SRS3
 SG_ PNC23_SUM : 23|1@0+ (1,0) [0|0] "" SRS3
 SG_ PNC25_SUM : 25|1@0+ (1,0) [0|0] "" SRS3
 SG_ PNC29_SUM : 29|1@0+ (1,0) [0|0] "" SRS3
 SG_ PNC36_SUM : 36|1@0+ (1,0) [0|0] "" SRS3
 SG_ PNC38_SUM : 38|1@0+ (1,0) [0|0] "" SRS3
 SG_ WakeUpReasonsforSUM : 55|16@0+ (1,0) [0|65535] "" Vector__XXX

BO_ 1381 SumZCUDCANFD3VFCVectorFr: 8 SUM
 SG_ VFCVectorSUMBlockID : 1|2@0+ (1,0) [0|3] "Unitless" ZCUD
 SG_ VFCVectorSUMVFCid0 : 2|1@0+ (1,0) [0|1] "" ZCUD
 SG_ VFCVectorSUMVFCid1 : 3|1@0+ (1,0) [0|1] "" ZCUD
 SG_ VFCVectorSUMVFCid10 : 12|1@0+ (1,0) [0|1] "" ZCUD
 SG_ VFCVectorSUMVFCid11 : 13|1@0+ (1,0) [0|1] "" ZCUD
 SG_ VFCVectorSUMVFCid12 : 14|1@0+ (1,0) [0|1] "" ZCUD
 SG_ VFCVectorSUMVFCid13 : 15|1@0+ (1,0) [0|1] "" ZCUD
 SG_ VFCVectorSUMVFCid14 : 16|1@0+ (1,0) [0|1] "" ZCUD
 SG_ VFCVectorSUMVFCid15 : 17|1@0+ (1,0) [0|1] "" ZCUD
 SG_ VFCVectorSUMVFCid16 : 18|1@0+ (1,0) [0|1] "" ZCUD
 SG_ VFCVectorSUMVFCid17 : 19|1@0+ (1,0) [0|1] "" ZCUD
 SG_ VFCVectorSUMVFCid18 : 20|1@0+ (1,0) [0|1] "" ZCUD
 SG_ VFCVectorSUMVFCid19 : 21|1@0+ (1,0) [0|1] "" ZCUD
 SG_ VFCVectorSUMVFCid2 : 4|1@0+ (1,0) [0|1] "" ZCUD
 SG_ VFCVectorSUMVFCid20 : 22|1@0+ (1,0) [0|1] "" ZCUD
 SG_ VFCVectorSUMVFCid21 : 23|1@0+ (1,0) [0|1] "" ZCUD
 SG_ VFCVectorSUMVFCid22 : 24|1@0+ (1,0) [0|1] "" ZCUD
 SG_ VFCVectorSUMVFCid23 : 25|1@0+ (1,0) [0|1] "" ZCUD
 SG_ VFCVectorSUMVFCid24 : 26|1@0+ (1,0) [0|1] "" ZCUD
 SG_ VFCVectorSUMVFCid25 : 27|1@0+ (1,0) [0|1] "" ZCUD
 SG_ VFCVectorSUMVFCid26 : 28|1@0+ (1,0) [0|1] "" ZCUD
 SG_ VFCVectorSUMVFCid27 : 29|1@0+ (1,0) [0|1] "" ZCUD
 SG_ VFCVectorSUMVFCid28 : 30|1@0+ (1,0) [0|1] "" ZCUD
 SG_ VFCVectorSUMVFCid29 : 31|1@0+ (1,0) [0|1] "" ZCUD
 SG_ VFCVectorSUMVFCid3 : 5|1@0+ (1,0) [0|1] "" ZCUD
 SG_ VFCVectorSUMVFCid30 : 32|1@0+ (1,0) [0|1] "" ZCUD
 SG_ VFCVectorSUMVFCid31 : 33|1@0+ (1,0) [0|1] "" ZCUD
 SG_ VFCVectorSUMVFCid32 : 34|1@0+ (1,0) [0|1] "" ZCUD
 SG_ VFCVectorSUMVFCid33 : 35|1@0+ (1,0) [0|1] "" ZCUD
 SG_ VFCVectorSUMVFCid34 : 36|1@0+ (1,0) [0|1] "" ZCUD
 SG_ VFCVectorSUMVFCid35 : 37|1@0+ (1,0) [0|1] "" ZCUD
 SG_ VFCVectorSUMVFCid36 : 38|1@0+ (1,0) [0|1] "" ZCUD
 SG_ VFCVectorSUMVFCid37 : 39|1@0+ (1,0) [0|1] "" ZCUD
 SG_ VFCVectorSUMVFCid38 : 40|1@0+ (1,0) [0|1] "" ZCUD
 SG_ VFCVectorSUMVFCid39 : 41|1@0+ (1,0) [0|1] "" ZCUD
 SG_ VFCVectorSUMVFCid4 : 6|1@0+ (1,0) [0|1] "" ZCUD
 SG_ VFCVectorSUMVFCid40 : 42|1@0+ (1,0) [0|1] "" ZCUD
 SG_ VFCVectorSUMVFCid41 : 43|1@0+ (1,0) [0|1] "" ZCUD
 SG_ VFCVectorSUMVFCid42 : 44|1@0+ (1,0) [0|1] "" ZCUD
 SG_ VFCVectorSUMVFCid43 : 45|1@0+ (1,0) [0|1] "" ZCUD
 SG_ VFCVectorSUMVFCid44 : 46|1@0+ (1,0) [0|1] "" ZCUD
 SG_ VFCVectorSUMVFCid45 : 47|1@0+ (1,0) [0|1] "" ZCUD
 SG_ VFCVectorSUMVFCid46 : 48|1@0+ (1,0) [0|1] "" ZCUD
 SG_ VFCVectorSUMVFCid47 : 49|1@0+ (1,0) [0|1] "" ZCUD
 SG_ VFCVectorSUMVFCid48 : 50|1@0+ (1,0) [0|1] "" ZCUD
 SG_ VFCVectorSUMVFCid49 : 51|1@0+ (1,0) [0|1] "" ZCUD
 SG_ VFCVectorSUMVFCid5 : 7|1@0+ (1,0) [0|1] "" ZCUD
 SG_ VFCVectorSUMVFCid50 : 52|1@0+ (1,0) [0|1] "" ZCUD
 SG_ VFCVectorSUMVFCid51 : 53|1@0+ (1,0) [0|1] "" ZCUD
 SG_ VFCVectorSUMVFCid52 : 54|1@0+ (1,0) [0|1] "" ZCUD
 SG_ VFCVectorSUMVFCid53 : 55|1@0+ (1,0) [0|1] "" ZCUD
 SG_ VFCVectorSUMVFCid54 : 56|1@0+ (1,0) [0|1] "" ZCUD
 SG_ VFCVectorSUMVFCid55 : 57|1@0+ (1,0) [0|1] "" ZCUD
 SG_ VFCVectorSUMVFCid56 : 58|1@0+ (1,0) [0|1] "" ZCUD
 SG_ VFCVectorSUMVFCid57 : 59|1@0+ (1,0) [0|1] "" ZCUD
 SG_ VFCVectorSUMVFCid58 : 60|1@0+ (1,0) [0|1] "" ZCUD
 SG_ VFCVectorSUMVFCid59 : 61|1@0+ (1,0) [0|1] "" ZCUD
 SG_ VFCVectorSUMVFCid6 : 8|1@0+ (1,0) [0|1] "" ZCUD
 SG_ VFCVectorSUMVFCid60 : 62|1@0+ (1,0) [0|1] "" ZCUD
 SG_ VFCVectorSUMVFCid61 : 63|1@0+ (1,0) [0|1] "" ZCUD
 SG_ VFCVectorSUMVFCid7 : 9|1@0+ (1,0) [0|1] "" ZCUD
 SG_ VFCVectorSUMVFCid8 : 10|1@0+ (1,0) [0|1] "" ZCUD
 SG_ VFCVectorSUMVFCid9 : 11|1@0+ (1,0) [0|1] "" ZCUD

BO_ 784 XcmZCUDCANFD3Fr02: 64 XCM
 SG_ HvFanEna : 23|1@0+ (1,0) [0|1] "" HVFM
 SG_ HvFanEna_UB : 22|1@0+ (1,0) [0|1] "" HVFM
 SG_ HvFanSpdReq : 7|7@0+ (1,0) [0|100] "%" HVFM
 SG_ HvFanSpdReq_UB : 0|1@0+ (1,0) [0|1] "" HVFM
 SG_ HvFanSpdReqEstimd : 15|7@0+ (1,0) [0|100] "%" HVFM
 SG_ HvFanSpdReqEstimd_UB : 8|1@0+ (1,0) [0|1] "" HVFM

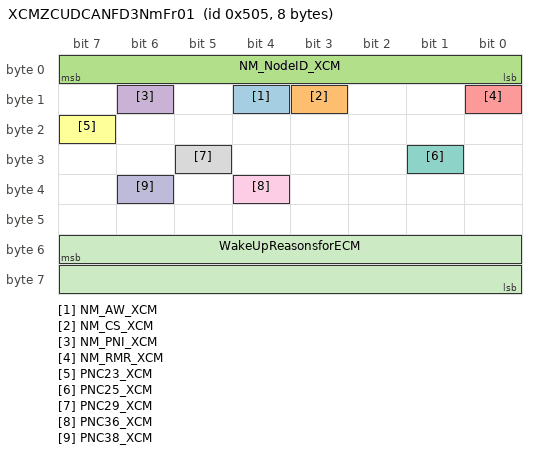
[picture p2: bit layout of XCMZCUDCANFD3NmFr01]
BO_ 1285 XCMZCUDCANFD3NmFr01: 8 XCM
 SG_ NM_AW_XCM : 12|1@0+ (1,0) [0|0] "" SUM
 SG_ NM_CS_XCM : 11|1@0+ (1,0) [0|0] "" SUM
 SG_ NM_NodeID_XCM : 7|8@0+ (1,0) [0|0] "" SUM
 SG_ NM_PNI_XCM : 14|1@0+ (1,0) [0|0] "" SUM
 SG_ NM_RMR_XCM : 8|1@0+ (1,0) [0|0] "" SUM
 SG_ PNC23_XCM : 23|1@0+ (1,0) [0|0] "" SUM
 SG_ PNC25_XCM : 25|1@0+ (1,0) [0|0] "" SUM
 SG_ PNC29_XCM : 29|1@0+ (1,0) [0|0] "" SUM
 SG_ PNC36_XCM : 36|1@0+ (1,0) [0|0] "" SUM
 SG_ PNC38_XCM : 38|1@0+ (1,0) [0|0] "" SUM
 SG_ WakeUpReasonsforECM : 55|16@0+ (1,0) [0|65535] "" Vector__XXX

BO_ 2047 ZcudToAllFuncZCUDCANFD3DiagReqFr: 8 ZCUD
 SG_ ZcudToAllFuncZcudCAN3DiagReqNpdu : 7|64@0+ (1,0) [0|0] "" HVFM,SUM

BO_ 1860 ZcudToHvfmZCUCANFD3DiagReqFr: 64 ZCUD
 SG_ ZcudToHvfmZCUCanFD3DiagResNpdu : 7|512@0+ (1,0) [0|0] "" HVFM

BO_ 1856 ZcudToHwamZCUCANFD3DiagReqFr: 64 ZCUD
 SG_ ZcudToHwamZCUCanFD3DiagResNpdu : 7|512@0+ (1,0) [0|0] "" Vector__XXX

BO_ 1858 ZcudToHwasZCUCANFD3DiagReqFr: 64 ZCUD
 SG_ ZcudToHwasZCUCanFD3DiagResNpdu : 7|512@0+ (1,0) [0|0] "" Vector__XXX

BO_ 1859 ZcudToRwamZCUCANFD3DiagReqFr: 64 ZCUD
 SG_ ZcudToRwamZCUCanFD3DiagResNpdu : 7|512@0+ (1,0) [0|0] "" Vector__XXX

BO_ 1857 ZcudToSumZCUCANFD3DiagReqFr: 64 ZCUD
 SG_ ZcudToSumZCUCanFD3DiagResNpdu : 7|512@0+ (1,0) [0|0] "" SUM

CM_ BU_ ETC "External Tester Connector";
CM_ SG_ 769 HvFanACLockFlt "AC Lock fault";
CM_ SG_ 769 HvFanActPwr "actual power";
CM_ SG_ 769 HvFanBlockFlt "Block Fault";
CM_ SG_ 769 HvFanBusOffFlt "Bus Off Fault";
CM_ SG_ 769 HvFanCalFlt "Self learning fault";
CM_ SG_ 769 HvFanChks "Hign Voltage Fan Checksum";
CM_ SG_ 769 HvFanCntr "RollingCounter";
CM_ SG_ 769 HvFanControllerT "High Voltage Fancontroller temperature";
CM_ SG_ 769 HvFanCurrentIctrlFlt "Current deviation Fault";
CM_ SG_ 769 HvFanCurrentIsOCFlt "Internal feedback overload fault";
CM_ SG_ 769 HvFanCurrentSumFlt "Current Sum fault";
CM_ SG_ 769 HvFanDCBusOVFlt "Bus overvoltage fault";
CM_ SG_ 769 HvFanDCBusOVWarn "Bus overvoltage warning";
CM_ SG_ 769 HvFanDCBusUVFlt "Bus undervoltage fault";
CM_ SG_ 769 HvFanDCBusUVWarn "Bus undervoltage warning";
CM_ SG_ 769 HvFanDCCrt "DC current of High voltage Fan";
CM_ SG_ 769 HvFanDCLockFlt "DC Lock Fault";
CM_ SG_ 769 HvFanDCVolt "High Voltage Fan DC voltage";
CM_ SG_ 769 HvFanDriveFlt "Drive Fault";
CM_ SG_ 769 HvFanFaultClass "High Voltage Fan fault level";
CM_ SG_ 769 HvFanFltNum "High Voltage Fan fault internal number";
CM_ SG_ 769 HvFanHeartBeatFlt "Heart beat fault";
CM_ SG_ 769 HvFanHVLKFlt "Hign Voltage Fan high-pressure interlock failure";
CM_ SG_ 769 HvFanHWProtectFlt "Hardware protection failure";
CM_ SG_ 769 HvFanInverterOTFlt "Controller over temperature limit fault";
CM_ SG_ 769 HvFanInverterOTWarn "Controller overtemperature warn";
CM_ SG_ 769 HvFanLifebeat "Hign Voltage Fan life beat";
CM_ SG_ 769 HvFanLVSupOVFlt "Low-voltage overvoltage fault";
CM_ SG_ 769 HvFanLVSupUVFlt "Low voltage and under-voltage fault";
CM_ SG_ 769 HvFanMotCrt "High Voltage Fan motor current";
CM_ SG_ 769 HvFanMotPwr "High Voltage Fan motor power";
CM_ SG_ 769 HvFanMotT "High Voltage Fan motor temperature";
CM_ SG_ 769 HvFanMotVolt "High Voltage Fan motor voltage";
CM_ SG_ 769 HvFanNoCal "No self learning";
CM_ SG_ 769 HvFanOSFlt "Over speed fault";
CM_ SG_ 769 HvFanOSWarn "over speed warm";
CM_ SG_ 769 HvFanOTFlt "Motor over temperature fault";
CM_ SG_ 769 HvFanOTWarm "Motor over temperature warning";
CM_ SG_ 769 HvFanPhaseOCFlt "Phase current overcurrent fault";
CM_ SG_ 769 HvFanPwrReq "Estimated power of High voltage Fan.";
CM_ SG_ 769 HvFanSpdFb "Feedback of High-Voltage Fan speed";
CM_ SG_ 769 HvFanStartFlt "Start Fault";
CM_ SG_ 769 HvFanSts "High Voltage Fan status";
CM_ SG_ 769 HvFanTotFltNum "High Voltage Fan total faults number";
CM_ SG_ 769 HvFanWindOSWarn "Wind over speed warning";
CM_ SG_ 769 HVFMMissingSlaveSignal "Missing slave signal";
CM_ SG_ 1289 WakeUpReasonsforHVFM "ECUWakeupReasons";
CM_ SG_ 1353 VFCVectorHVFMBlockID "BlockID";
CM_ SG_ 1353 VFCVectorHVFMVFCid0 "SettingsComfort";
CM_ SG_ 1353 VFCVectorHVFMVFCid1 "ParkingDrivingClimatization";
CM_ SG_ 1353 VFCVectorHVFMVFCid10 "ExteriorLighting";
CM_ SG_ 1353 VFCVectorHVFMVFCid11 "VFC11";
CM_ SG_ 1353 VFCVectorHVFMVFCid12 "Alarm";
CM_ SG_ 1353 VFCVectorHVFMVFCid13 "VFC13";
CM_ SG_ 1353 VFCVectorHVFMVFCid14 "InteriorLighting";
CM_ SG_ 1353 VFCVectorHVFMVFCid15 "VFC15";
CM_ SG_ 1353 VFCVectorHVFMVFCid16 "Locking";
CM_ SG_ 1353 VFCVectorHVFMVFCid17 "emoteKeyFunctionality";
CM_ SG_ 1353 VFCVectorHVFMVFCid18 "PropulsionStart";
CM_ SG_ 1353 VFCVectorHVFMVFCid19 "VFC19";
CM_ SG_ 1353 VFCVectorHVFMVFCid2 "PostClimatisation";
CM_ SG_ 1353 VFCVectorHVFMVFCid20 "VFC20";
CM_ SG_ 1353 VFCVectorHVFMVFCid21 "PowerClosures";
CM_ SG_ 1353 VFCVectorHVFMVFCid22 "VehicleDriving";
CM_ SG_ 1353 VFCVectorHVFMVFCid23 "VFC23";
CM_ SG_ 1353 VFCVectorHVFMVFCid24 "SettingsProfile";
CM_ SG_ 1353 VFCVectorHVFMVFCid25 "SeatComfortFunctions";
CM_ SG_ 1353 VFCVectorHVFMVFCid26 "Brake";
CM_ SG_ 1353 VFCVectorHVFMVFCid27 "InfotainmentPoll";
CM_ SG_ 1353 VFCVectorHVFMVFCid28 "HVEnergyStorage";
CM_ SG_ 1353 VFCVectorHVFMVFCid29 "VFC29";
CM_ SG_ 1353 VFCVectorHVFMVFCid3 "PowertrainParkingClimatization";
CM_ SG_ 1353 VFCVectorHVFMVFCid30 "TelematicsConnectivity";
CM_ SG_ 1353 VFCVectorHVFMVFCid31 "VFC31";
CM_ SG_ 1353 VFCVectorHVFMVFCid32 "VFC32";
CM_ SG_ 1353 VFCVectorHVFMVFCid33 "Diagnostics";
CM_ SG_ 1353 VFCVectorHVFMVFCid34 "VehicleModeManagement";
CM_ SG_ 1353 VFCVectorHVFMVFCid35 "TrailerCaravanFunctions";
CM_ SG_ 1353 VFCVectorHVFMVFCid36 "Immobilizer";
CM_ SG_ 1353 VFCVectorHVFMVFCid37 "Windows";
CM_ SG_ 1353 VFCVectorHVFMVFCid38 "Visibility";
CM_ SG_ 1353 VFCVectorHVFMVFCid39 "VFC39";
CM_ SG_ 1353 VFCVectorHVFMVFCid4 "VFC4";
CM_ SG_ 1353 VFCVectorHVFMVFCid40 "VFC40";
CM_ SG_ 1353 VFCVectorHVFMVFCid41 "InfotainmentPush";
CM_ SG_ 1353 VFCVectorHVFMVFCid42 "ChargingHV";
CM_ SG_ 1353 VFCVectorHVFMVFCid43 "BodyPreClimatisation";
CM_ SG_ 1353 VFCVectorHVFMVFCid44 "Crash";
CM_ SG_ 1353 VFCVectorHVFMVFCid45 "GlobalShortDuration";
CM_ SG_ 1353 VFCVectorHVFMVFCid46 "ExteriorLightsHazard";
CM_ SG_ 1353 VFCVectorHVFMVFCid47 "VFC47";
CM_ SG_ 1353 VFCVectorHVFMVFCid48 "DoorOpenWarning";
CM_ SG_ 1353 VFCVectorHVFMVFCid49 "ChargingLVInit";
CM_ SG_ 1353 VFCVectorHVFMVFCid5 "VFC5";
CM_ SG_ 1353 VFCVectorHVFMVFCid50 "VFC50";
CM_ SG_ 1353 VFCVectorHVFMVFCid51 "VFC51";
CM_ SG_ 1353 VFCVectorHVFMVFCid52 "HVBatteryThermalEventWarning";
CM_ SG_ 1353 VFCVectorHVFMVFCid53 "VisualAssist";
CM_ SG_ 1353 VFCVectorHVFMVFCid54 "PassiveSafety";
CM_ SG_ 1353 VFCVectorHVFMVFCid55 "LifeDetection";
CM_ SG_ 1353 VFCVectorHVFMVFCid56 "BackboneFlexray";
CM_ SG_ 1353 VFCVectorHVFMVFCid57 "Functionmarket";
CM_ SG_ 1353 VFCVectorHVFMVFCid58 "VFCid58";
CM_ SG_ 1353 VFCVectorHVFMVFCid59 "VFCid59";
CM_ SG_ 1353 VFCVectorHVFMVFCid6 "SettingsVehicle";
CM_ SG_ 1353 VFCVectorHVFMVFCid60 "VFCid60";
CM_ SG_ 1353 VFCVectorHVFMVFCid61 "VFCid61";
CM_ SG_ 1353 VFCVectorHVFMVFCid7 "VFC7";
CM_ SG_ 1353 VFCVectorHVFMVFCid8 "VFC8";
CM_ SG_ 1353 VFCVectorHVFMVFCid9 "IPWakeup";
CM_ SG_ 81 TVCBrkTqReqChks "Checksum";
CM_ SG_ 81 TVCBrkTqReqCntr "Counter";
CM_ SG_ 81 TVCBrkTqReqFrntLe "FL wheel brake torque request";
CM_ SG_ 81 TVCBrkTqReqFrntLeCtrlMod "whlVagrMinReqFrntLe";
CM_ SG_ 81 TVCBrkTqReqFrntRi "FR wheel brake torque request";
CM_ SG_ 81 TVCBrkTqReqFrntRiCtrlMod "whlVagrMinReqFrntRi";
CM_ SG_ 81 TVCBrkTqReqReLe "RL wheel brake torque request";
CM_ SG_ 81 TVCBrkTqReqReLeCtrlMod "whlVagrMinReqRele";
CM_ SG_ 81 TVCBrkTqReqReRi "RR wheel brake torque request";
CM_ SG_ 81 TVCBrkTqReqReRiCtrlMod "whlVagrMinReqReRi";
CM_ SG_ 81 TVCBrkTqReqWhlVAgrMinReqFrntLe "WhlVAgrMinReqFrntLe";
CM_ SG_ 81 TVCBrkTqReqWhlVAgrMinReqFrntRi "WhlVAgrMinReqFrntRi";
CM_ SG_ 81 TVCBrkTqReqWhlVAgrMinReqReLe "WhlVAgrMinReqReLe";
CM_ SG_ 81 TVCBrkTqReqWhlVAgrMinReqReRi "WhlVAgrMinReqReRi";
CM_ SG_ 81 TVCPrpsnTqDistActv "TVC request torque distribute active";
CM_ SG_ 81 TVCPrpsnTqDistRatio "TVC request torque distribute ratio";
CM_ SG_ 81 TVCReWhlSteerCtrlStsForTvcChks "Checksum";
CM_ SG_ 81 TVCReWhlSteerCtrlStsForTvcCntr "Counter";
CM_ SG_ 81 TVCReWhlSteerCtrlStsForTvcTVCReWhlSteerCtrlStsForTvc "The state of TVC control RWS";
CM_ SG_ 81 TVCRwsAngReqForTvcChks "Checksum";
CM_ SG_ 81 TVCRwsAngReqForTvcCntr "Counter";
CM_ SG_ 81 TVCRwsAngReqForTvcTVCRwsAngReqForTvc "RWS Angle request for TVC";
CM_ SG_ 81 TVCTqDistbnFaultForGVMCChks "Checksum";
CM_ SG_ 81 TVCTqDistbnFaultForGVMCCntr "Counter";
CM_ SG_ 81 TVCTqDistbnFaultForGVMCTVCTqDistbnFaultForGVMC "TVC Torque distribution fault.";
CM_ SG_ 257 FasPwrAllwd "Power Allowed For FAS";
CM_ SG_ 257 MotDynCtrlStsReLeChks "The status of the DMC.";
CM_ SG_ 257 MotDynCtrlStsReLeCntr "The status of the DMC.";
CM_ SG_ 257 MotDynCtrlStsReLeDmcActAppTarTq "The status of the DMC.";
CM_ SG_ 257 MotDynCtrlStsReLeDmcSts "The status of the DMC.";
CM_ SG_ 257 MotDynCtrlStsReLeDmcSWInfo "The status of the DMC.";
CM_ SG_ 257 MotDynCtrlStsReRiChks "The status of the DMC.";
CM_ SG_ 257 MotDynCtrlStsReRiCntr "The status of the DMC.";
CM_ SG_ 257 MotDynCtrlStsReRiDmcActAppTarTq "The status of the DMC.";
CM_ SG_ 257 MotDynCtrlStsReRiDmcSts "The status of the DMC.";
CM_ SG_ 257 MotDynCtrlStsReRiDmcSWInfo "The status of the DMC.";
CM_ SG_ 257 TVCEradLeMaxAvailWhl "Maximum available rear  left wheel torque(Contain motor limit/power limit)";
CM_ SG_ 257 TVCEradLeMinAvailWhl "Minimum available rear left wheel torque(Contain motor limit/power limit)";
CM_ SG_ 257 TVCEradLeReqWhl "Request wheel torque from left Erad path";
CM_ SG_ 257 TVCEradRiMaxAvailWhl "Maximum available rear right wheel torque(Contain motor limit/power limit)";
CM_ SG_ 257 TVCEradRiMinAvailWhl "Minimum available rear right wheel torque(Contain motor limit/power limit)";
CM_ SG_ 257 TVCEradRiReqWhl "Request wheel torque from right Erad path";
CM_ SG_ 50 ADataRawSafeALat "IMU acceleration data Lateral acceleration";
CM_ SG_ 50 ADataRawSafeALat1Qf "IMU acceleration data Quality factor for Lateral acceleration signal";
CM_ SG_ 50 ADataRawSafeALgt "IMU acceleration data Longitudinal acceleration";
CM_ SG_ 50 ADataRawSafeALgt1Qf "IMU acceleration data Quality factor for Longitudinal acceleration";
CM_ SG_ 50 ADataRawSafeAVert "IMU acceleration data Vertical acceleration";
CM_ SG_ 50 ADataRawSafeAVertQf "IMU acceleration data Quality factor for Vertical acceleration";
CM_ SG_ 50 ADataRawSafeChks "IMU acceleration data Check sum";
CM_ SG_ 50 ADataRawSafeCntr "IMU acceleration data Counter";
CM_ SG_ 50 AgDataRawSafeChks "IMU angular rate data. Check summa";
CM_ SG_ 50 AgDataRawSafeCntr "IMU angular rate data. Counter";
CM_ SG_ 50 AgDataRawSafeRollRate "IMU angular rate data. Roll Rate";
CM_ SG_ 50 AgDataRawSafeRollRateQf "IMU angular rate data. Quality factor for Roll Rate";
CM_ SG_ 50 AgDataRawSafeYawRate "IMU angular rate data. Yaw Rate";
CM_ SG_ 50 AgDataRawSafeYawRateQf "IMU angular rate data. Quality Factor for Yaw Rate";
CM_ SG_ 50 AsyDataWithCmpSafeALat1Qf "IMU processed special data. Quality factor for Lateral acceleration signal";
CM_ SG_ 50 AsyDataWithCmpSafeALatWithCmp "IMU processed special data.  Compensated Lateral acceleration";
CM_ SG_ 50 AsyDataWithCmpSafeALgt1Qf "IMU processed special data. Quality factor for Longitudinal acceleration";
CM_ SG_ 50 AsyDataWithCmpSafeChks "IMU processed special data. Check sum";
CM_ SG_ 50 AsyDataWithCmpSafeCntr "IMU processed special data. Counter";
CM_ SG_ 50 AsyDataWithCmpSafeGrdtOfALgt "IMU processed special data. Derivative of Longitudinal acceleration";
CM_ SG_ 50 AsyDataWithCmpSafeYawRateQf "IMU processed special data. Quality Factor for Yaw Rate";
CM_ SG_ 50 AsyDataWithCmpSafeYawRateWithCmp "IMU processed special data. Compensated Yaw rate";
CM_ SG_ 50 IntgtIMUDataRawSafeALat "IMU acceleration data Lateral acceleration";
CM_ SG_ 50 IntgtIMUDataRawSafeALat1Qf "QF for Lateral acceleration";
CM_ SG_ 50 IntgtIMUDataRawSafeALgt "IMU acceleration data Longitudinal acceleration";
CM_ SG_ 50 IntgtIMUDataRawSafeALgt1Qf "QF for Longitudinal acceleration";
CM_ SG_ 50 IntgtIMUDataRawSafeAvert "IMU acceleration data Vertical acceleration";
CM_ SG_ 50 IntgtIMUDataRawSafeAVertQf "QF for Vertical acceleration";
CM_ SG_ 50 IntgtIMUDataRawSafeChks "Check summa";
CM_ SG_ 50 IntgtIMUDataRawSafeCntr "Counter";
CM_ SG_ 50 IntgtIMUDataRawSafePitchRate "IMU angular rate Pitch rate";
CM_ SG_ 50 IntgtIMUDataRawSafePitchRateQf "QF for Pitch rate";
CM_ SG_ 50 IntgtIMUDataRawSafeRollRate "IMU angular rate Roll rate";
CM_ SG_ 50 IntgtIMUDataRawSafeRollRateQf "QF for Roll rate";
CM_ SG_ 50 IntgtIMUDataRawSafeYawRate "IMU angular rate Yaw rate";
CM_ SG_ 50 IntgtIMUDataRawSafeYawRateQf "QF for Yaw rate";
CM_ SG_ 63 CrashStsSafeChks "Checksum for E2E";
CM_ SG_ 63 CrashStsSafeCntr "Counter for E2E";
CM_ SG_ 63 CrashStsSafeSts "Information if a crash has been detected by SRS.";
CM_ SG_ 553 AgDataCmpQualityPitchRateCmpQuality "Quality of offset compensation for pitchrate";
CM_ SG_ 553 AgDataCmpQualityRollRateCmpQuality "Quality of offset compensation for rollrate";
CM_ SG_ 553 AgDataCmpQualityYawRateCmpQuality "Quality of offset compensation for yawrate";
CM_ SG_ 1286 WakeUpReasonsforSRS "WakeUpReasons";
CM_ SG_ 1350 VFCVectorSRSBlockID "BlockID";
CM_ SG_ 1350 VFCVectorSRSVFCid0 "SettingsComfort";
CM_ SG_ 1350 VFCVectorSRSVFCid1 "ParkingDrivingClimatization";
CM_ SG_ 1350 VFCVectorSRSVFCid10 "ExteriorLighting";
CM_ SG_ 1350 VFCVectorSRSVFCid11 "VFC11";
CM_ SG_ 1350 VFCVectorSRSVFCid12 "Alarm";
CM_ SG_ 1350 VFCVectorSRSVFCid13 "VFC13";
CM_ SG_ 1350 VFCVectorSRSVFCid14 "InteriorLighting";
CM_ SG_ 1350 VFCVectorSRSVFCid15 "VFC15";
CM_ SG_ 1350 VFCVectorSRSVFCid16 "Locking";
CM_ SG_ 1350 VFCVectorSRSVFCid17 "RemoteKeyFunctionality";
CM_ SG_ 1350 VFCVectorSRSVFCid18 "PropulsionStart";
CM_ SG_ 1350 VFCVectorSRSVFCid19 "VFC19";
CM_ SG_ 1350 VFCVectorSRSVFCid2 "PostClimatisation";
CM_ SG_ 1350 VFCVectorSRSVFCid20 "VFC20";
CM_ SG_ 1350 VFCVectorSRSVFCid21 "PowerClosures";
CM_ SG_ 1350 VFCVectorSRSVFCid22 "VehicleDriving";
CM_ SG_ 1350 VFCVectorSRSVFCid23 "VFC23";
CM_ SG_ 1350 VFCVectorSRSVFCid24 "SettingsProfile";
CM_ SG_ 1350 VFCVectorSRSVFCid25 "SeatComfortFunctions";
CM_ SG_ 1350 VFCVectorSRSVFCid26 "Brake";
CM_ SG_ 1350 VFCVectorSRSVFCid27 "InfotainmentPoll";
CM_ SG_ 1350 VFCVectorSRSVFCid28 "HVEnergyStorage";
CM_ SG_ 1350 VFCVectorSRSVFCid29 "VFC29";
CM_ SG_ 1350 VFCVectorSRSVFCid3 "PowertrainParkingClimatization";
CM_ SG_ 1350 VFCVectorSRSVFCid30 "TelematicsConnectivity";
CM_ SG_ 1350 VFCVectorSRSVFCid31 "VFC31";
CM_ SG_ 1350 VFCVectorSRSVFCid32 "VFC32";
CM_ SG_ 1350 VFCVectorSRSVFCid33 "Diagnostics";
CM_ SG_ 1350 VFCVectorSRSVFCid34 "VehicleModeManagement";
CM_ SG_ 1350 VFCVectorSRSVFCid35 "TrailerCaravanFunctions";
CM_ SG_ 1350 VFCVectorSRSVFCid36 "Immobilizer";
CM_ SG_ 1350 VFCVectorSRSVFCid37 "Windows";
CM_ SG_ 1350 VFCVectorSRSVFCid38 "Visibility";
CM_ SG_ 1350 VFCVectorSRSVFCid39 "VFC39";
CM_ SG_ 1350 VFCVectorSRSVFCid4 "VFC4";
CM_ SG_ 1350 VFCVectorSRSVFCid40 "VFC40";
CM_ SG_ 1350 VFCVectorSRSVFCid41 "InfotainmentPush";
CM_ SG_ 1350 VFCVectorSRSVFCid42 "ChargingHV";
CM_ SG_ 1350 VFCVectorSRSVFCid43 "BodyPreClimatisation";
CM_ SG_ 1350 VFCVectorSRSVFCid44 "Crash";
CM_ SG_ 1350 VFCVectorSRSVFCid45 "GlobalShortDuration";
CM_ SG_ 1350 VFCVectorSRSVFCid46 "ExteriorLightsHazard";
CM_ SG_ 1350 VFCVectorSRSVFCid47 "VFC47";
CM_ SG_ 1350 VFCVectorSRSVFCid48 "DoorOpenWarning";
CM_ SG_ 1350 VFCVectorSRSVFCid49 "ChargingLVInit";
CM_ SG_ 1350 VFCVectorSRSVFCid5 "VFC5";
CM_ SG_ 1350 VFCVectorSRSVFCid50 "VFC50";
CM_ SG_ 1350 VFCVectorSRSVFCid51 "VFC51";
CM_ SG_ 1350 VFCVectorSRSVFCid52 "HVBatteryThermalEventWarning";
CM_ SG_ 1350 VFCVectorSRSVFCid53 "VisualAssist";
CM_ SG_ 1350 VFCVectorSRSVFCid54 "PassiveSafety";
CM_ SG_ 1350 VFCVectorSRSVFCid55 "LifeDetection";
CM_ SG_ 1350 VFCVectorSRSVFCid56 "BackboneFlexray";
CM_ SG_ 1350 VFCVectorSRSVFCid57 "Functionmarket";
CM_ SG_ 1350 VFCVectorSRSVFCid58 "VFC58";
CM_ SG_ 1350 VFCVectorSRSVFCid59 "VFC59";
CM_ SG_ 1350 VFCVectorSRSVFCid6 "SettingsVehicle";
CM_ SG_ 1350 VFCVectorSRSVFCid60 "VFC60";
CM_ SG_ 1350 VFCVectorSRSVFCid61 "VFC61";
CM_ SG_ 1350 VFCVectorSRSVFCid7 "VFC7";
CM_ SG_ 1350 VFCVectorSRSVFCid8 "VFC8";
CM_ SG_ 1350 VFCVectorSRSVFCid9 "IPWakeup";
CM_ SG_ 448 AirSuspFltSts "error state";
CM_ SG_ 448 ReLvlSwt "rear axle switch";
CM_ SG_ 448 SuspCmprSpdFb "Compressor speed feedback";
CM_ SG_ 448 SuspDistbnVlvCtrlStsFb "the status of the distribution valve";
CM_ SG_ 448 SuspHumVal "humidity value";
CM_ SG_ 448 SuspPVal "pressure value";
CM_ SG_ 448 SuspStfnVlvCtrlStsFbFL "stiffness feedback";
CM_ SG_ 448 SuspStfnVlvCtrlStsFbFR "stiffness feedback";
CM_ SG_ 448 SuspStfnVlvCtrlStsFbRL "stiffness feedback";
CM_ SG_ 448 SuspStfnVlvCtrlStsFbRR "stiffness feedback";
CM_ SG_ 448 SuspTVal "temperature value";
CM_ SG_ 528 SUMMissingSlaveSignal "Missing frame signal";
CM_ SG_ 528 SuspCmprCurr "Compressor current";
CM_ SG_ 1317 WakeUpReasonsforSUM "ECUWakeupReasons";
CM_ SG_ 1381 VFCVectorSUMBlockID "BlockID";
CM_ SG_ 1381 VFCVectorSUMVFCid0 "SettingsComfort";
CM_ SG_ 1381 VFCVectorSUMVFCid1 "ParkingDrivingClimatization";
CM_ SG_ 1381 VFCVectorSUMVFCid10 "ExteriorLighting";
CM_ SG_ 1381 VFCVectorSUMVFCid11 "VFC11";
CM_ SG_ 1381 VFCVectorSUMVFCid12 "Alarm";
CM_ SG_ 1381 VFCVectorSUMVFCid13 "VFC13";
CM_ SG_ 1381 VFCVectorSUMVFCid14 "InteriorLighting";
CM_ SG_ 1381 VFCVectorSUMVFCid15 "VFC15";
CM_ SG_ 1381 VFCVectorSUMVFCid16 "Locking";
CM_ SG_ 1381 VFCVectorSUMVFCid17 "RemoteKeyFunctionality";
CM_ SG_ 1381 VFCVectorSUMVFCid18 "PropulsionStart";
CM_ SG_ 1381 VFCVectorSUMVFCid19 "VFC19";
CM_ SG_ 1381 VFCVectorSUMVFCid2 "PostClimatisation";
CM_ SG_ 1381 VFCVectorSUMVFCid20 "VFC20";
CM_ SG_ 1381 VFCVectorSUMVFCid21 "PowerClosures";
CM_ SG_ 1381 VFCVectorSUMVFCid22 "VehicleDriving";
CM_ SG_ 1381 VFCVectorSUMVFCid23 "VFC23";
CM_ SG_ 1381 VFCVectorSUMVFCid24 "SettingsProfile";
CM_ SG_ 1381 VFCVectorSUMVFCid25 "SeatComfortFunctions";
CM_ SG_ 1381 VFCVectorSUMVFCid26 "Brake";
CM_ SG_ 1381 VFCVectorSUMVFCid27 "InfotainmentPoll";
CM_ SG_ 1381 VFCVectorSUMVFCid28 "HVEnergyStorage";
CM_ SG_ 1381 VFCVectorSUMVFCid29 "VFC29";
CM_ SG_ 1381 VFCVectorSUMVFCid3 "PowertrainParkingClimatization";
CM_ SG_ 1381 VFCVectorSUMVFCid30 "TelematicsConnectivity";
CM_ SG_ 1381 VFCVectorSUMVFCid31 "VFC31";
CM_ SG_ 1381 VFCVectorSUMVFCid32 "VFC32";
CM_ SG_ 1381 VFCVectorSUMVFCid33 "Diagnostics";
CM_ SG_ 1381 VFCVectorSUMVFCid34 "VehicleModeManagement";
CM_ SG_ 1381 VFCVectorSUMVFCid35 "TrailerCaravanFunctions";
CM_ SG_ 1381 VFCVectorSUMVFCid36 "Immobilizer";
CM_ SG_ 1381 VFCVectorSUMVFCid37 "Windows";
CM_ SG_ 1381 VFCVectorSUMVFCid38 "Visibility";
CM_ SG_ 1381 VFCVectorSUMVFCid39 "VFC39";
CM_ SG_ 1381 VFCVectorSUMVFCid4 "VFC4";
CM_ SG_ 1381 VFCVectorSUMVFCid40 "VFC40";
CM_ SG_ 1381 VFCVectorSUMVFCid41 "InfotainmentPush";
CM_ SG_ 1381 VFCVectorSUMVFCid42 "ChargingHV";
CM_ SG_ 1381 VFCVectorSUMVFCid43 "BodyPreClimatisation";
CM_ SG_ 1381 VFCVectorSUMVFCid44 "Crash";
CM_ SG_ 1381 VFCVectorSUMVFCid45 "GlobalShortDuration";
CM_ SG_ 1381 VFCVectorSUMVFCid46 "ExteriorLightsHazard";
CM_ SG_ 1381 VFCVectorSUMVFCid47 "VFC47";
CM_ SG_ 1381 VFCVectorSUMVFCid48 "DoorOpenWarning";
CM_ SG_ 1381 VFCVectorSUMVFCid49 "ChargingLVInit";
CM_ SG_ 1381 VFCVectorSUMVFCid5 "VFC5";
CM_ SG_ 1381 VFCVectorSUMVFCid50 "VFC50";
CM_ SG_ 1381 VFCVectorSUMVFCid51 "VFC51";
CM_ SG_ 1381 VFCVectorSUMVFCid52 "HVBatteryThermalEventWarning";
CM_ SG_ 1381 VFCVectorSUMVFCid53 "VisualAssist";
CM_ SG_ 1381 VFCVectorSUMVFCid54 "PassiveSafety";
CM_ SG_ 1381 VFCVectorSUMVFCid55 "LifeDetection";
CM_ SG_ 1381 VFCVectorSUMVFCid56 "BackboneFlexray";
CM_ SG_ 1381 VFCVectorSUMVFCid57 "Functionmarket";
CM_ SG_ 1381 VFCVectorSUMVFCid58 "VFC58";
CM_ SG_ 1381 VFCVectorSUMVFCid59 "VFC59";
CM_ SG_ 1381 VFCVectorSUMVFCid6 "SettingsVehicle";
CM_ SG_ 1381 VFCVectorSUMVFCid60 "VFC60";
CM_ SG_ 1381 VFCVectorSUMVFCid61 "VFC61";
CM_ SG_ 1381 VFCVectorSUMVFCid7 "VFC7";
CM_ SG_ 1381 VFCVectorSUMVFCid8 "VFC8";
CM_ SG_ 1381 VFCVectorSUMVFCid9 "IPWakeup";
CM_ SG_ 784 HvFanEna "Enable High-Voltage Fan";
CM_ SG_ 784 HvFanSpdReq "Request  for High Voltage Fan speed";
CM_ SG_ 784 HvFanSpdReqEstimd "Request  for High Voltage Fan estimated speed";
CM_ SG_ 1285 WakeUpReasonsforECM "WakeUpReasons";

BA_DEF_ BU_ "NodeLayerModules" STRING ;
BA_DEF_ BU_ "NmAsrNodeIdentifier" INT 0 255;
BA_DEF_ BU_ "NmAsrNode" ENUM "No","Yes";
BA_DEF_ BU_ "ILused" ENUM "No","Yes";
BA_DEF_ "ProtocolType" STRING ;
BA_DEF_ "NmAsrMessageCount" INT 0 255;
BA_DEF_ "NmAsrBaseAddress" HEX 0 536870911;
BA_DEF_ "BusType" STRING ;
BA_DEF_ "BaudRateCANFD" FLOAT 1000 10000000;
BA_DEF_ "Baudrate" INT 1000 1000000;
BA_DEF_ "DBName" STRING ;
BA_DEF_ BO_ "NmAsrMessage" ENUM "No","Yes";
BA_DEF_ BO_ "GenMsgStartDelayTime" INT 0 65536;
BA_DEF_ BO_ "GenMsgSendType" ENUM "cyclic","spontaneous","not-used","not-used","not-used","cyclicAndSpontaneous","not-used","cyclicIfActive","NoMsgSendType";
BA_DEF_ BO_ "GenMsgILSupport" ENUM "No","Yes";
BA_DEF_ BO_ "GenMsgDelayTime" INT 0 65536;
BA_DEF_ BO_ "GenMsgCycleTime" INT 0 65536;
BA_DEF_ BO_ "CANFD_BRS" ENUM "0","1";
BA_DEF_ BO_ "VFrameFormat" ENUM "StandardCAN","ExtendedCAN","reserved","J1939PG","reserved","reserved","reserved","reserved","reserved","reserved","reserved","reserved","reserved","reserved","StandardCAN_FD","ExtendedCAN_FD";
BA_DEF_ SG_ "GenSigStartValue" HEX 0 80000000;
BA_DEF_ SG_ "GenSigSendType" ENUM "Cyclic","OnWrite","OnWriteWithRepetition","OnChange","OnChangeWithRepetition","IfActive","IfActiveWithRepetition","NoSigSendType";
BA_DEF_ SG_ "GenSigFuncType" ENUM "NoFunction","n/a","n/a","n/a","n/a","n/a","n/a","n/a","n/a","n/a","n/a","n/a","n/a","n/a","n/a","CHK","CNTR","n/a","n/a","n/a","CNTR_AR_01","CRC_AR_01_BOTH","CRC_AR_01_ALT","CRC_AR_01_LOW","CRC_AR_01_NIBBLE","CNTR_AR_04","CRC_AR_04A","CNTR_AR_05","CRC_AR_05";
BA_DEF_ SG_ "GenSigDataID" STRING ;
BA_DEF_DEF_ "NodeLayerModules" "CANoeILNLSPA.dll";
BA_DEF_DEF_ "NmAsrNodeIdentifier" 0;
BA_DEF_DEF_ "NmAsrNode" "No";
BA_DEF_DEF_ "ILused" "Yes";
BA_DEF_DEF_ "ProtocolType" "";
BA_DEF_DEF_ "NmAsrMessageCount" 64;
BA_DEF_DEF_ "NmAsrBaseAddress" 1280;
BA_DEF_DEF_ "BusType" "";
BA_DEF_DEF_ "BaudRateCANFD" 2000;
BA_DEF_DEF_ "Baudrate" 500;
BA_DEF_DEF_ "DBName" "";
BA_DEF_DEF_ "NmAsrMessage" "No";
BA_DEF_DEF_ "GenMsgStartDelayTime" 0;
BA_DEF_DEF_ "GenMsgSendType" "NoMsgSendType";
BA_DEF_DEF_ "GenMsgILSupport" "Yes";
BA_DEF_DEF_ "GenMsgDelayTime" 0;
BA_DEF_DEF_ "GenMsgCycleTime" 0;
BA_DEF_DEF_ "CANFD_BRS" "1";
BA_DEF_DEF_ "VFrameFormat" "J1939PG";
BA_DEF_DEF_ "GenSigStartValue" 0;
BA_DEF_DEF_ "GenSigSendType" "NoSigSendType";
BA_DEF_DEF_ "GenSigFuncType" "NoFunction";
BA_DEF_DEF_ "GenSigDataID" "";
BA_ "BusType" "CAN FD";
BA_ "BaudRateCANFD" 2000000;
BA_ "ProtocolType" "CAN";
BA_ "Baudrate" 500000;
BA_ "DBName" "ZCUD_CANFD3";
BA_ "NodeLayerModules" BU_ ASDM "CANoeILNLSPA.dll,AsrNM33.dll";
BA_ "NmAsrNode" BU_ ASDM 1;
BA_ "ILused" BU_ ETC 0;
BA_ "NodeLayerModules" BU_ HVFM "CANoeILNLSPA.dll,AsrNM33.dll";
BA_ "NmAsrNode" BU_ HVFM 1;
BA_ "NmAsrNodeIdentifier" BU_ HVFM 9;
BA_ "NodeLayerModules" BU_ SRS3 "CANoeILNLSPA.dll,AsrNM33.dll";
BA_ "NmAsrNode" BU_ SRS3 1;
BA_ "NmAsrNodeIdentifier" BU_ SRS3 6;
BA_ "NodeLayerModules" BU_ SUM "CANoeILNLSPA.dll,AsrNM33.dll";
BA_ "NmAsrNode" BU_ SUM 1;
BA_ "NmAsrNodeIdentifier" BU_ SUM 37;
BA_ "NodeLayerModules" BU_ XCM "CANoeILNLSPA.dll,AsrNM33.dll";
BA_ "NmAsrNode" BU_ XCM 1;
BA_ "NmAsrNodeIdentifier" BU_ XCM 5;
BA_ "NodeLayerModules" BU_ ZCUD "CANoeILNLSPA.dll,AsrNM33.dll";
BA_ "NmAsrNode" BU_ ZCUD 1;
BA_ "NmAsrNodeIdentifier" BU_ ZCUD 1;
BA_ "NodeLayerModules" BU_ ZCUT "CANoeILNLSPA.dll,AsrNM33.dll";
BA_ "NmAsrNode" BU_ ZCUT 1;
BA_ "NmAsrNodeIdentifier" BU_ ZCUT 2;
BA_ "GenMsgDelayTime" BO_ 1418 100;
BA_ "GenMsgSendType" BO_ 1418 1;
BA_ "VFrameFormat" BO_ 1418 0;
BA_ "GenMsgDelayTime" BO_ 1604 5;
BA_ "GenMsgSendType" BO_ 1604 1;
BA_ "VFrameFormat" BO_ 1604 14;
BA_ "GenMsgCycleTime" BO_ 769 200;
BA_ "GenMsgSendType" BO_ 769 0;
BA_ "VFrameFormat" BO_ 769 14;
BA_ "GenMsgDelayTime" BO_ 1289 20;
BA_ "NmAsrMessage" BO_ 1289 1;
BA_ "GenMsgILSupport" BO_ 1289 0;
BA_ "GenMsgSendType" BO_ 1289 1;
BA_ "VFrameFormat" BO_ 1289 0;
BA_ "GenMsgCycleTime" BO_ 1353 1000;
BA_ "GenMsgSendType" BO_ 1353 0;
BA_ "VFrameFormat" BO_ 1353 0;
BA_ "GenMsgCycleTime" BO_ 81 10;
BA_ "GenMsgSendType" BO_ 81 0;
BA_ "VFrameFormat" BO_ 81 14;
BA_ "GenMsgCycleTime" BO_ 257 20;
BA_ "GenMsgSendType" BO_ 257 0;
BA_ "VFrameFormat" BO_ 257 14;
BA_ "GenMsgCycleTime" BO_ 50 5;
BA_ "GenMsgSendType" BO_ 50 0;
BA_ "VFrameFormat" BO_ 50 14;
BA_ "GenMsgCycleTime" BO_ 63 200;
BA_ "GenMsgDelayTime" BO_ 63 10;
BA_ "GenMsgSendType" BO_ 63 5;
BA_ "VFrameFormat" BO_ 63 14;
BA_ "GenMsgCycleTime" BO_ 553 100;
BA_ "GenMsgSendType" BO_ 553 0;
BA_ "VFrameFormat" BO_ 553 14;
BA_ "GenMsgDelayTime" BO_ 1286 20;
BA_ "NmAsrMessage" BO_ 1286 1;
BA_ "GenMsgILSupport" BO_ 1286 0;
BA_ "GenMsgSendType" BO_ 1286 1;
BA_ "VFrameFormat" BO_ 1286 0;
BA_ "GenMsgCycleTime" BO_ 1350 1000;
BA_ "GenMsgSendType" BO_ 1350 0;
BA_ "VFrameFormat" BO_ 1350 0;
BA_ "GenMsgDelayTime" BO_ 1417 100;
BA_ "GenMsgSendType" BO_ 1417 1;
BA_ "VFrameFormat" BO_ 1417 0;
BA_ "GenMsgDelayTime" BO_ 1601 5;
BA_ "GenMsgSendType" BO_ 1601 1;
BA_ "VFrameFormat" BO_ 1601 14;
BA_ "GenMsgCycleTime" BO_ 448 50;
BA_ "GenMsgSendType" BO_ 448 0;
BA_ "VFrameFormat" BO_ 448 14;
BA_ "GenMsgCycleTime" BO_ 528 80;
BA_ "GenMsgSendType" BO_ 528 0;
BA_ "VFrameFormat" BO_ 528 14;
BA_ "GenMsgDelayTime" BO_ 1317 20;
BA_ "NmAsrMessage" BO_ 1317 1;
BA_ "GenMsgILSupport" BO_ 1317 0;
BA_ "GenMsgSendType" BO_ 1317 1;
BA_ "VFrameFormat" BO_ 1317 0;
BA_ "GenMsgCycleTime" BO_ 1381 1000;
BA_ "GenMsgSendType" BO_ 1381 0;
BA_ "VFrameFormat" BO_ 1381 0;
BA_ "GenMsgCycleTime" BO_ 784 200;
BA_ "GenMsgSendType" BO_ 784 0;
BA_ "VFrameFormat" BO_ 784 14;
BA_ "GenMsgDelayTime" BO_ 1285 20;
BA_ "NmAsrMessage" BO_ 1285 1;
BA_ "GenMsgILSupport" BO_ 1285 0;
BA_ "GenMsgSendType" BO_ 1285 1;
BA_ "VFrameFormat" BO_ 1285 0;
BA_ "GenMsgSendType" BO_ 2047 1;
BA_ "VFrameFormat" BO_ 2047 14;
BA_ "GenMsgSendType" BO_ 1860 1;
BA_ "VFrameFormat" BO_ 1860 14;
BA_ "GenMsgSendType" BO_ 1856 1;
BA_ "VFrameFormat" BO_ 1856 14;
BA_ "GenMsgSendType" BO_ 1858 1;
BA_ "VFrameFormat" BO_ 1858 14;
BA_ "GenMsgSendType" BO_ 1859 1;
BA_ "VFrameFormat" BO_ 1859 14;
BA_ "GenMsgSendType" BO_ 1857 1;
BA_ "VFrameFormat" BO_ 1857 14;
BA_ "GenSigSendType" SG_ 769 HvFanACLockFlt 0;
BA_ "GenSigSendType" SG_ 769 HvFanActPwr 0;
BA_ "GenSigSendType" SG_ 769 HvFanBlockFlt 0;
BA_ "GenSigSendType" SG_ 769 HvFanBusOffFlt 0;
BA_ "GenSigSendType" SG_ 769 HvFanCalFlt 0;
BA_ "GenSigSendType" SG_ 769 HvFanChks 0;
BA_ "GenSigSendType" SG_ 769 HvFanCntr 0;
BA_ "GenSigStartValue" SG_ 769 HvFanControllerT 40;
BA_ "GenSigSendType" SG_ 769 HvFanControllerT 0;
BA_ "GenSigSendType" SG_ 769 HvFanCurrentIctrlFlt 0;
BA_ "GenSigSendType" SG_ 769 HvFanCurrentIsOCFlt 0;
BA_ "GenSigSendType" SG_ 769 HvFanCurrentSumFlt 0;
BA_ "GenSigSendType" SG_ 769 HvFanDCBusOVFlt 0;
BA_ "GenSigSendType" SG_ 769 HvFanDCBusOVWarn 0;
BA_ "GenSigSendType" SG_ 769 HvFanDCBusUVFlt 0;
BA_ "GenSigSendType" SG_ 769 HvFanDCBusUVWarn 0;
BA_ "GenSigSendType" SG_ 769 HvFanDCCrt 0;
BA_ "GenSigSendType" SG_ 769 HvFanDCLockFlt 0;
BA_ "GenSigSendType" SG_ 769 HvFanDCVolt 0;
BA_ "GenSigSendType" SG_ 769 HvFanDriveFlt 0;
BA_ "GenSigSendType" SG_ 769 HvFanFaultClass 0;
BA_ "GenSigSendType" SG_ 769 HvFanFltNum 0;
BA_ "GenSigSendType" SG_ 769 HvFanHeartBeatFlt 0;
BA_ "GenSigSendType" SG_ 769 HvFanHVLKFlt 0;
BA_ "GenSigSendType" SG_ 769 HvFanHWProtectFlt 0;
BA_ "GenSigSendType" SG_ 769 HvFanInverterOTFlt 0;
BA_ "GenSigSendType" SG_ 769 HvFanInverterOTWarn 0;
BA_ "GenSigSendType" SG_ 769 HvFanLifebeat 0;
BA_ "GenSigSendType" SG_ 769 HvFanLVSupOVFlt 0;
BA_ "GenSigSendType" SG_ 769 HvFanLVSupUVFlt 0;
BA_ "GenSigSendType" SG_ 769 HvFanMotCrt 0;
BA_ "GenSigSendType" SG_ 769 HvFanMotPwr 0;
BA_ "GenSigStartValue" SG_ 769 HvFanMotT 40;
BA_ "GenSigSendType" SG_ 769 HvFanMotT 0;
BA_ "GenSigSendType" SG_ 769 HvFanMotVolt 0;
BA_ "GenSigSendType" SG_ 769 HvFanNoCal 0;
BA_ "GenSigSendType" SG_ 769 HvFanOSFlt 0;
BA_ "GenSigSendType" SG_ 769 HvFanOSWarn 0;
BA_ "GenSigSendType" SG_ 769 HvFanOTFlt 0;
BA_ "GenSigSendType" SG_ 769 HvFanOTWarm 0;
BA_ "GenSigSendType" SG_ 769 HvFanPhaseOCFlt 0;
BA_ "GenSigSendType" SG_ 769 HvFanPwrReq 0;
BA_ "GenSigSendType" SG_ 769 HvFanSpdFb 0;
BA_ "GenSigSendType" SG_ 769 HvFanStartFlt 0;
BA_ "GenSigSendType" SG_ 769 HvFanSts 0;
BA_ "GenSigSendType" SG_ 769 HvFanTotFltNum 0;
BA_ "GenSigSendType" SG_ 769 HvFanWindOSWarn 0;
BA_ "GenSigSendType" SG_ 769 HVFMMissingSlaveSignal 0;
BA_ "GenSigSendType" SG_ 1289 WakeUpReasonsforHVFM 0;
BA_ "GenSigSendType" SG_ 1353 VFCVectorHVFMBlockID 0;
BA_ "GenSigSendType" SG_ 1353 VFCVectorHVFMVFCid0 0;
BA_ "GenSigSendType" SG_ 1353 VFCVectorHVFMVFCid1 0;
BA_ "GenSigSendType" SG_ 1353 VFCVectorHVFMVFCid10 0;
BA_ "GenSigSendType" SG_ 1353 VFCVectorHVFMVFCid11 0;
BA_ "GenSigSendType" SG_ 1353 VFCVectorHVFMVFCid12 0;
BA_ "GenSigSendType" SG_ 1353 VFCVectorHVFMVFCid13 0;
BA_ "GenSigSendType" SG_ 1353 VFCVectorHVFMVFCid14 0;
BA_ "GenSigSendType" SG_ 1353 VFCVectorHVFMVFCid15 0;
BA_ "GenSigSendType" SG_ 1353 VFCVectorHVFMVFCid16 0;
BA_ "GenSigSendType" SG_ 1353 VFCVectorHVFMVFCid17 0;
BA_ "GenSigSendType" SG_ 1353 VFCVectorHVFMVFCid18 0;
BA_ "GenSigSendType" SG_ 1353 VFCVectorHVFMVFCid19 0;
BA_ "GenSigSendType" SG_ 1353 VFCVectorHVFMVFCid2 0;
BA_ "GenSigSendType" SG_ 1353 VFCVectorHVFMVFCid20 0;
BA_ "GenSigSendType" SG_ 1353 VFCVectorHVFMVFCid21 0;
BA_ "GenSigSendType" SG_ 1353 VFCVectorHVFMVFCid22 0;
BA_ "GenSigSendType" SG_ 1353 VFCVectorHVFMVFCid23 0;
BA_ "GenSigSendType" SG_ 1353 VFCVectorHVFMVFCid24 0;
BA_ "GenSigSendType" SG_ 1353 VFCVectorHVFMVFCid25 0;
BA_ "GenSigSendType" SG_ 1353 VFCVectorHVFMVFCid26 0;
BA_ "GenSigSendType" SG_ 1353 VFCVectorHVFMVFCid27 0;
BA_ "GenSigSendType" SG_ 1353 VFCVectorHVFMVFCid28 0;
BA_ "GenSigSendType" SG_ 1353 VFCVectorHVFMVFCid29 0;
BA_ "GenSigSendType" SG_ 1353 VFCVectorHVFMVFCid3 0;
BA_ "GenSigSendType" SG_ 1353 VFCVectorHVFMVFCid30 0;
BA_ "GenSigSendType" SG_ 1353 VFCVectorHVFMVFCid31 0;
BA_ "GenSigSendType" SG_ 1353 VFCVectorHVFMVFCid32 0;
BA_ "GenSigSendType" SG_ 1353 VFCVectorHVFMVFCid33 0;
BA_ "GenSigSendType" SG_ 1353 VFCVectorHVFMVFCid34 0;
BA_ "GenSigSendType" SG_ 1353 VFCVectorHVFMVFCid35 0;
BA_ "GenSigSendType" SG_ 1353 VFCVectorHVFMVFCid36 0;
BA_ "GenSigSendType" SG_ 1353 VFCVectorHVFMVFCid37 0;
BA_ "GenSigSendType" SG_ 1353 VFCVectorHVFMVFCid38 0;
BA_ "GenSigSendType" SG_ 1353 VFCVectorHVFMVFCid39 0;
BA_ "GenSigSendType" SG_ 1353 VFCVectorHVFMVFCid4 0;
BA_ "GenSigSendType" SG_ 1353 VFCVectorHVFMVFCid40 0;
BA_ "GenSigSendType" SG_ 1353 VFCVectorHVFMVFCid41 0;
BA_ "GenSigSendType" SG_ 1353 VFCVectorHVFMVFCid42 0;
BA_ "GenSigSendType" SG_ 1353 VFCVectorHVFMVFCid43 0;
BA_ "GenSigSendType" SG_ 1353 VFCVectorHVFMVFCid44 0;
BA_ "GenSigSendType" SG_ 1353 VFCVectorHVFMVFCid45 0;
BA_ "GenSigSendType" SG_ 1353 VFCVectorHVFMVFCid46 0;
BA_ "GenSigSendType" SG_ 1353 VFCVectorHVFMVFCid47 0;
BA_ "GenSigSendType" SG_ 1353 VFCVectorHVFMVFCid48 0;
BA_ "GenSigSendType" SG_ 1353 VFCVectorHVFMVFCid49 0;
BA_ "GenSigSendType" SG_ 1353 VFCVectorHVFMVFCid5 0;
BA_ "GenSigSendType" SG_ 1353 VFCVectorHVFMVFCid50 0;
BA_ "GenSigSendType" SG_ 1353 VFCVectorHVFMVFCid51 0;
BA_ "GenSigSendType" SG_ 1353 VFCVectorHVFMVFCid52 0;
BA_ "GenSigSendType" SG_ 1353 VFCVectorHVFMVFCid53 0;
BA_ "GenSigSendType" SG_ 1353 VFCVectorHVFMVFCid54 0;
BA_ "GenSigSendType" SG_ 1353 VFCVectorHVFMVFCid55 0;
BA_ "GenSigSendType" SG_ 1353 VFCVectorHVFMVFCid56 0;
BA_ "GenSigSendType" SG_ 1353 VFCVectorHVFMVFCid57 0;
BA_ "GenSigSendType" SG_ 1353 VFCVectorHVFMVFCid58 0;
BA_ "GenSigSendType" SG_ 1353 VFCVectorHVFMVFCid59 0;
BA_ "GenSigSendType" SG_ 1353 VFCVectorHVFMVFCid6 0;
BA_ "GenSigSendType" SG_ 1353 VFCVectorHVFMVFCid60 0;
BA_ "GenSigSendType" SG_ 1353 VFCVectorHVFMVFCid61 0;
BA_ "GenSigSendType" SG_ 1353 VFCVectorHVFMVFCid7 0;
BA_ "GenSigSendType" SG_ 1353 VFCVectorHVFMVFCid8 0;
BA_ "GenSigSendType" SG_ 1353 VFCVectorHVFMVFCid9 0;
BA_ "GenSigDataID" SG_ 81 TVCBrkTqReqChks "0x1BCD";
BA_ "GenSigFuncType" SG_ 81 TVCBrkTqReqChks 15;
BA_ "GenSigSendType" SG_ 81 TVCBrkTqReqChks 0;
BA_ "GenSigFuncType" SG_ 81 TVCBrkTqReqCntr 16;
BA_ "GenSigSendType" SG_ 81 TVCBrkTqReqCntr 0;
BA_ "GenSigSendType" SG_ 81 TVCBrkTqReqFrntLe 0;
BA_ "GenSigSendType" SG_ 81 TVCBrkTqReqFrntLeCtrlMod 0;
BA_ "GenSigSendType" SG_ 81 TVCBrkTqReqFrntRi 0;
BA_ "GenSigSendType" SG_ 81 TVCBrkTqReqFrntRiCtrlMod 0;
BA_ "GenSigSendType" SG_ 81 TVCBrkTqReqReLe 0;
BA_ "GenSigSendType" SG_ 81 TVCBrkTqReqReLeCtrlMod 0;
BA_ "GenSigSendType" SG_ 81 TVCBrkTqReqReRi 0;
BA_ "GenSigSendType" SG_ 81 TVCBrkTqReqReRiCtrlMod 0;
BA_ "GenSigSendType" SG_ 81 TVCBrkTqReqWhlVAgrMinReqFrntLe 0;
BA_ "GenSigSendType" SG_ 81 TVCBrkTqReqWhlVAgrMinReqFrntRi 0;
BA_ "GenSigSendType" SG_ 81 TVCBrkTqReqWhlVAgrMinReqReLe 0;
BA_ "GenSigSendType" SG_ 81 TVCBrkTqReqWhlVAgrMinReqReRi 0;
BA_ "GenSigSendType" SG_ 81 TVCPrpsnTqDistActv 0;
BA_ "GenSigSendType" SG_ 81 TVCPrpsnTqDistRatio 0;
BA_ "GenSigDataID" SG_ 81 TVCReWhlSteerCtrlStsForTvcChks "0x1BD5";
BA_ "GenSigFuncType" SG_ 81 TVCReWhlSteerCtrlStsForTvcChks 15;
BA_ "GenSigSendType" SG_ 81 TVCReWhlSteerCtrlStsForTvcChks 0;
BA_ "GenSigFuncType" SG_ 81 TVCReWhlSteerCtrlStsForTvcCntr 16;
BA_ "GenSigSendType" SG_ 81 TVCReWhlSteerCtrlStsForTvcCntr 0;
BA_ "GenSigSendType" SG_ 81 TVCReWhlSteerCtrlStsForTvcTVCReWhlSteerCtrlStsForTvc 0;
BA_ "GenSigDataID" SG_ 81 TVCRwsAngReqForTvcChks "0x1BD6";
BA_ "GenSigFuncType" SG_ 81 TVCRwsAngReqForTvcChks 15;
BA_ "GenSigSendType" SG_ 81 TVCRwsAngReqForTvcChks 0;
BA_ "GenSigFuncType" SG_ 81 TVCRwsAngReqForTvcCntr 16;
BA_ "GenSigSendType" SG_ 81 TVCRwsAngReqForTvcCntr 0;
BA_ "GenSigSendType" SG_ 81 TVCRwsAngReqForTvcTVCRwsAngReqForTvc 0;
BA_ "GenSigDataID" SG_ 81 TVCTqDistbnFaultForGVMCChks "0x1BCC";
BA_ "GenSigFuncType" SG_ 81 TVCTqDistbnFaultForGVMCChks 15;
BA_ "GenSigSendType" SG_ 81 TVCTqDistbnFaultForGVMCChks 0;
BA_ "GenSigFuncType" SG_ 81 TVCTqDistbnFaultForGVMCCntr 16;
BA_ "GenSigSendType" SG_ 81 TVCTqDistbnFaultForGVMCCntr 0;
BA_ "GenSigSendType" SG_ 81 TVCTqDistbnFaultForGVMCTVCTqDistbnFaultForGVMC 0;
BA_ "GenSigSendType" SG_ 257 FasPwrAllwd 0;
BA_ "GenSigDataID" SG_ 257 MotDynCtrlStsReLeChks "0x1A06";
BA_ "GenSigFuncType" SG_ 257 MotDynCtrlStsReLeChks 15;
BA_ "GenSigSendType" SG_ 257 MotDynCtrlStsReLeChks 0;
BA_ "GenSigFuncType" SG_ 257 MotDynCtrlStsReLeCntr 16;
BA_ "GenSigSendType" SG_ 257 MotDynCtrlStsReLeCntr 0;
BA_ "GenSigSendType" SG_ 257 MotDynCtrlStsReLeDmcActAppTarTq 0;
BA_ "GenSigSendType" SG_ 257 MotDynCtrlStsReLeDmcSts 0;
BA_ "GenSigSendType" SG_ 257 MotDynCtrlStsReLeDmcSWInfo 0;
BA_ "GenSigDataID" SG_ 257 MotDynCtrlStsReRiChks "0x1A07";
BA_ "GenSigFuncType" SG_ 257 MotDynCtrlStsReRiChks 15;
BA_ "GenSigSendType" SG_ 257 MotDynCtrlStsReRiChks 0;
BA_ "GenSigFuncType" SG_ 257 MotDynCtrlStsReRiCntr 16;
BA_ "GenSigSendType" SG_ 257 MotDynCtrlStsReRiCntr 0;
BA_ "GenSigSendType" SG_ 257 MotDynCtrlStsReRiDmcActAppTarTq 0;
BA_ "GenSigSendType" SG_ 257 MotDynCtrlStsReRiDmcSts 0;
BA_ "GenSigSendType" SG_ 257 MotDynCtrlStsReRiDmcSWInfo 0;
BA_ "GenSigStartValue" SG_ 257 TVCEradLeMaxAvailWhl 2047;
BA_ "GenSigSendType" SG_ 257 TVCEradLeMaxAvailWhl 0;
BA_ "GenSigStartValue" SG_ 257 TVCEradLeMinAvailWhl 2047;
BA_ "GenSigSendType" SG_ 257 TVCEradLeMinAvailWhl 0;
BA_ "GenSigSendType" SG_ 257 TVCEradLeReqWhl 0;
BA_ "GenSigStartValue" SG_ 257 TVCEradRiMaxAvailWhl 2047;
BA_ "GenSigSendType" SG_ 257 TVCEradRiMaxAvailWhl 0;
BA_ "GenSigStartValue" SG_ 257 TVCEradRiMinAvailWhl 2047;
BA_ "GenSigSendType" SG_ 257 TVCEradRiMinAvailWhl 0;
BA_ "GenSigSendType" SG_ 257 TVCEradRiReqWhl 0;
BA_ "GenSigSendType" SG_ 50 ADataRawSafeALat 0;
BA_ "GenSigStartValue" SG_ 50 ADataRawSafeALat1Qf 1;
BA_ "GenSigSendType" SG_ 50 ADataRawSafeALat1Qf 0;
BA_ "GenSigSendType" SG_ 50 ADataRawSafeALgt 0;
BA_ "GenSigStartValue" SG_ 50 ADataRawSafeALgt1Qf 1;
BA_ "GenSigSendType" SG_ 50 ADataRawSafeALgt1Qf 0;
BA_ "GenSigStartValue" SG_ 50 ADataRawSafeAVert 1155;
BA_ "GenSigSendType" SG_ 50 ADataRawSafeAVert 0;
BA_ "GenSigStartValue" SG_ 50 ADataRawSafeAVertQf 1;
BA_ "GenSigSendType" SG_ 50 ADataRawSafeAVertQf 0;
BA_ "GenSigStartValue" SG_ 50 ADataRawSafeChks 255;
BA_ "GenSigDataID" SG_ 50 ADataRawSafeChks "0x22";
BA_ "GenSigFuncType" SG_ 50 ADataRawSafeChks 15;
BA_ "GenSigSendType" SG_ 50 ADataRawSafeChks 0;
BA_ "GenSigFuncType" SG_ 50 ADataRawSafeCntr 16;
BA_ "GenSigSendType" SG_ 50 ADataRawSafeCntr 0;
BA_ "GenSigStartValue" SG_ 50 AgDataRawSafeChks 255;
BA_ "GenSigDataID" SG_ 50 AgDataRawSafeChks "0x23";
BA_ "GenSigFuncType" SG_ 50 AgDataRawSafeChks 15;
BA_ "GenSigSendType" SG_ 50 AgDataRawSafeChks 0;
BA_ "GenSigFuncType" SG_ 50 AgDataRawSafeCntr 16;
BA_ "GenSigSendType" SG_ 50 AgDataRawSafeCntr 0;
BA_ "GenSigSendType" SG_ 50 AgDataRawSafeRollRate 0;
BA_ "GenSigStartValue" SG_ 50 AgDataRawSafeRollRateQf 1;
BA_ "GenSigSendType" SG_ 50 AgDataRawSafeRollRateQf 0;
BA_ "GenSigSendType" SG_ 50 AgDataRawSafeYawRate 0;
BA_ "GenSigStartValue" SG_ 50 AgDataRawSafeYawRateQf 1;
BA_ "GenSigSendType" SG_ 50 AgDataRawSafeYawRateQf 0;
BA_ "GenSigStartValue" SG_ 50 AsyDataWithCmpSafeALat1Qf 1;
BA_ "GenSigSendType" SG_ 50 AsyDataWithCmpSafeALat1Qf 0;
BA_ "GenSigSendType" SG_ 50 AsyDataWithCmpSafeALatWithCmp 0;
BA_ "GenSigStartValue" SG_ 50 AsyDataWithCmpSafeALgt1Qf 1;
BA_ "GenSigSendType" SG_ 50 AsyDataWithCmpSafeALgt1Qf 0;
BA_ "GenSigStartValue" SG_ 50 AsyDataWithCmpSafeChks 255;
BA_ "GenSigDataID" SG_ 50 AsyDataWithCmpSafeChks "0x24";
BA_ "GenSigFuncType" SG_ 50 AsyDataWithCmpSafeChks 15;
BA_ "GenSigSendType" SG_ 50 AsyDataWithCmpSafeChks 0;
BA_ "GenSigFuncType" SG_ 50 AsyDataWithCmpSafeCntr 16;
BA_ "GenSigSendType" SG_ 50 AsyDataWithCmpSafeCntr 0;
BA_ "GenSigSendType" SG_ 50 AsyDataWithCmpSafeGrdtOfALgt 0;
BA_ "GenSigStartValue" SG_ 50 AsyDataWithCmpSafeYawRateQf 1;
BA_ "GenSigSendType" SG_ 50 AsyDataWithCmpSafeYawRateQf 0;
BA_ "GenSigSendType" SG_ 50 AsyDataWithCmpSafeYawRateWithCmp 0;
BA_ "GenSigSendType" SG_ 50 IntgtIMUDataRawSafeALat 0;
BA_ "GenSigStartValue" SG_ 50 IntgtIMUDataRawSafeALat1Qf 1;
BA_ "GenSigSendType" SG_ 50 IntgtIMUDataRawSafeALat1Qf 0;
BA_ "GenSigSendType" SG_ 50 IntgtIMUDataRawSafeALgt 0;
BA_ "GenSigStartValue" SG_ 50 IntgtIMUDataRawSafeALgt1Qf 1;
BA_ "GenSigSendType" SG_ 50 IntgtIMUDataRawSafeALgt1Qf 0;
BA_ "GenSigStartValue" SG_ 50 IntgtIMUDataRawSafeAvert 1155;
BA_ "GenSigSendType" SG_ 50 IntgtIMUDataRawSafeAvert 0;
BA_ "GenSigStartValue" SG_ 50 IntgtIMUDataRawSafeAVertQf 1;
BA_ "GenSigSendType" SG_ 50 IntgtIMUDataRawSafeAVertQf 0;
BA_ "GenSigStartValue" SG_ 50 IntgtIMUDataRawSafeChks 255;
BA_ "GenSigDataID" SG_ 50 IntgtIMUDataRawSafeChks "0x1B03";
BA_ "GenSigFuncType" SG_ 50 IntgtIMUDataRawSafeChks 15;
BA_ "GenSigSendType" SG_ 50 IntgtIMUDataRawSafeChks 0;
BA_ "GenSigFuncType" SG_ 50 IntgtIMUDataRawSafeCntr 16;
BA_ "GenSigSendType" SG_ 50 IntgtIMUDataRawSafeCntr 0;
BA_ "GenSigSendType" SG_ 50 IntgtIMUDataRawSafePitchRate 0;
BA_ "GenSigStartValue" SG_ 50 IntgtIMUDataRawSafePitchRateQf 1;
BA_ "GenSigSendType" SG_ 50 IntgtIMUDataRawSafePitchRateQf 0;
BA_ "GenSigSendType" SG_ 50 IntgtIMUDataRawSafeRollRate 0;
BA_ "GenSigStartValue" SG_ 50 IntgtIMUDataRawSafeRollRateQf 1;
BA_ "GenSigSendType" SG_ 50 IntgtIMUDataRawSafeRollRateQf 0;
BA_ "GenSigSendType" SG_ 50 IntgtIMUDataRawSafeYawRate 0;
BA_ "GenSigStartValue" SG_ 50 IntgtIMUDataRawSafeYawRateQf 1;
BA_ "GenSigSendType" SG_ 50 IntgtIMUDataRawSafeYawRateQf 0;
BA_ "GenSigStartValue" SG_ 63 CrashStsSafeChks 255;
BA_ "GenSigDataID" SG_ 63 CrashStsSafeChks "0x40B";
BA_ "GenSigFuncType" SG_ 63 CrashStsSafeChks 15;
BA_ "GenSigSendType" SG_ 63 CrashStsSafeChks 1;
BA_ "GenSigFuncType" SG_ 63 CrashStsSafeCntr 16;
BA_ "GenSigSendType" SG_ 63 CrashStsSafeCntr 1;
BA_ "GenSigSendType" SG_ 63 CrashStsSafeSts 1;
BA_ "GenSigSendType" SG_ 553 AgDataCmpQualityPitchRateCmpQuality 0;
BA_ "GenSigSendType" SG_ 553 AgDataCmpQualityRollRateCmpQuality 0;
BA_ "GenSigSendType" SG_ 553 AgDataCmpQualityYawRateCmpQuality 0;
BA_ "GenSigSendType" SG_ 1286 WakeUpReasonsforSRS 0;
BA_ "GenSigSendType" SG_ 1350 VFCVectorSRSBlockID 0;
BA_ "GenSigSendType" SG_ 1350 VFCVectorSRSVFCid0 0;
BA_ "GenSigSendType" SG_ 1350 VFCVectorSRSVFCid1 0;
BA_ "GenSigSendType" SG_ 1350 VFCVectorSRSVFCid10 0;
BA_ "GenSigSendType" SG_ 1350 VFCVectorSRSVFCid11 0;
BA_ "GenSigSendType" SG_ 1350 VFCVectorSRSVFCid12 0;
BA_ "GenSigSendType" SG_ 1350 VFCVectorSRSVFCid13 0;
BA_ "GenSigSendType" SG_ 1350 VFCVectorSRSVFCid14 0;
BA_ "GenSigSendType" SG_ 1350 VFCVectorSRSVFCid15 0;
BA_ "GenSigSendType" SG_ 1350 VFCVectorSRSVFCid16 0;
BA_ "GenSigSendType" SG_ 1350 VFCVectorSRSVFCid17 0;
BA_ "GenSigSendType" SG_ 1350 VFCVectorSRSVFCid18 0;
BA_ "GenSigSendType" SG_ 1350 VFCVectorSRSVFCid19 0;
BA_ "GenSigSendType" SG_ 1350 VFCVectorSRSVFCid2 0;
BA_ "GenSigSendType" SG_ 1350 VFCVectorSRSVFCid20 0;
BA_ "GenSigSendType" SG_ 1350 VFCVectorSRSVFCid21 0;
BA_ "GenSigSendType" SG_ 1350 VFCVectorSRSVFCid22 0;
BA_ "GenSigSendType" SG_ 1350 VFCVectorSRSVFCid23 0;
BA_ "GenSigSendType" SG_ 1350 VFCVectorSRSVFCid24 0;
BA_ "GenSigSendType" SG_ 1350 VFCVectorSRSVFCid25 0;
BA_ "GenSigSendType" SG_ 1350 VFCVectorSRSVFCid26 0;
BA_ "GenSigSendType" SG_ 1350 VFCVectorSRSVFCid27 0;
BA_ "GenSigSendType" SG_ 1350 VFCVectorSRSVFCid28 0;
BA_ "GenSigSendType" SG_ 1350 VFCVectorSRSVFCid29 0;
BA_ "GenSigSendType" SG_ 1350 VFCVectorSRSVFCid3 0;
BA_ "GenSigSendType" SG_ 1350 VFCVectorSRSVFCid30 0;
BA_ "GenSigSendType" SG_ 1350 VFCVectorSRSVFCid31 0;
BA_ "GenSigSendType" SG_ 1350 VFCVectorSRSVFCid32 0;
BA_ "GenSigSendType" SG_ 1350 VFCVectorSRSVFCid33 0;
BA_ "GenSigSendType" SG_ 1350 VFCVectorSRSVFCid34 0;
BA_ "GenSigSendType" SG_ 1350 VFCVectorSRSVFCid35 0;
BA_ "GenSigSendType" SG_ 1350 VFCVectorSRSVFCid36 0;
BA_ "GenSigSendType" SG_ 1350 VFCVectorSRSVFCid37 0;
BA_ "GenSigSendType" SG_ 1350 VFCVectorSRSVFCid38 0;
BA_ "GenSigSendType" SG_ 1350 VFCVectorSRSVFCid39 0;
BA_ "GenSigSendType" SG_ 1350 VFCVectorSRSVFCid4 0;
BA_ "GenSigSendType" SG_ 1350 VFCVectorSRSVFCid40 0;
BA_ "GenSigSendType" SG_ 1350 VFCVectorSRSVFCid41 0;
BA_ "GenSigSendType" SG_ 1350 VFCVectorSRSVFCid42 0;
BA_ "GenSigSendType" SG_ 1350 VFCVectorSRSVFCid43 0;
BA_ "GenSigSendType" SG_ 1350 VFCVectorSRSVFCid44 0;
BA_ "GenSigSendType" SG_ 1350 VFCVectorSRSVFCid45 0;
BA_ "GenSigSendType" SG_ 1350 VFCVectorSRSVFCid46 0;
BA_ "GenSigSendType" SG_ 1350 VFCVectorSRSVFCid47 0;
BA_ "GenSigSendType" SG_ 1350 VFCVectorSRSVFCid48 0;
BA_ "GenSigSendType" SG_ 1350 VFCVectorSRSVFCid49 0;
BA_ "GenSigSendType" SG_ 1350 VFCVectorSRSVFCid5 0;
BA_ "GenSigSendType" SG_ 1350 VFCVectorSRSVFCid50 0;
BA_ "GenSigSendType" SG_ 1350 VFCVectorSRSVFCid51 0;
BA_ "GenSigSendType" SG_ 1350 VFCVectorSRSVFCid52 0;
BA_ "GenSigSendType" SG_ 1350 VFCVectorSRSVFCid53 0;
BA_ "GenSigSendType" SG_ 1350 VFCVectorSRSVFCid54 0;
BA_ "GenSigSendType" SG_ 1350 VFCVectorSRSVFCid55 0;
BA_ "GenSigSendType" SG_ 1350 VFCVectorSRSVFCid56 0;
BA_ "GenSigSendType" SG_ 1350 VFCVectorSRSVFCid57 0;
BA_ "GenSigSendType" SG_ 1350 VFCVectorSRSVFCid58 0;
BA_ "GenSigSendType" SG_ 1350 VFCVectorSRSVFCid59 0;
BA_ "GenSigSendType" SG_ 1350 VFCVectorSRSVFCid6 0;
BA_ "GenSigSendType" SG_ 1350 VFCVectorSRSVFCid60 0;
BA_ "GenSigSendType" SG_ 1350 VFCVectorSRSVFCid61 0;
BA_ "GenSigSendType" SG_ 1350 VFCVectorSRSVFCid7 0;
BA_ "GenSigSendType" SG_ 1350 VFCVectorSRSVFCid8 0;
BA_ "GenSigSendType" SG_ 1350 VFCVectorSRSVFCid9 0;
BA_ "GenSigSendType" SG_ 448 AirSuspFltSts 0;
BA_ "GenSigStartValue" SG_ 448 ReLvlSwt 100;
BA_ "GenSigSendType" SG_ 448 ReLvlSwt 0;
BA_ "GenSigSendType" SG_ 448 SuspCmprSpdFb 0;
BA_ "GenSigSendType" SG_ 448 SuspDistbnVlvCtrlStsFb 0;
BA_ "GenSigStartValue" SG_ 448 SuspHumVal 50;
BA_ "GenSigSendType" SG_ 448 SuspHumVal 0;
BA_ "GenSigSendType" SG_ 448 SuspPVal 0;
BA_ "GenSigSendType" SG_ 448 SuspStfnVlvCtrlStsFbFL 0;
BA_ "GenSigSendType" SG_ 448 SuspStfnVlvCtrlStsFbFR 0;
BA_ "GenSigSendType" SG_ 448 SuspStfnVlvCtrlStsFbRL 0;
BA_ "GenSigSendType" SG_ 448 SuspStfnVlvCtrlStsFbRR 0;
BA_ "GenSigStartValue" SG_ 448 SuspTVal 120;
BA_ "GenSigSendType" SG_ 448 SuspTVal 0;
BA_ "GenSigSendType" SG_ 528 SUMMissingSlaveSignal 0;
BA_ "GenSigSendType" SG_ 528 SuspCmprCurr 0;
BA_ "GenSigSendType" SG_ 1317 WakeUpReasonsforSUM 0;
BA_ "GenSigSendType" SG_ 1381 VFCVectorSUMBlockID 0;
BA_ "GenSigSendType" SG_ 1381 VFCVectorSUMVFCid0 0;
BA_ "GenSigSendType" SG_ 1381 VFCVectorSUMVFCid1 0;
BA_ "GenSigSendType" SG_ 1381 VFCVectorSUMVFCid10 0;
BA_ "GenSigSendType" SG_ 1381 VFCVectorSUMVFCid11 0;
BA_ "GenSigSendType" SG_ 1381 VFCVectorSUMVFCid12 0;
BA_ "GenSigSendType" SG_ 1381 VFCVectorSUMVFCid13 0;
BA_ "GenSigSendType" SG_ 1381 VFCVectorSUMVFCid14 0;
BA_ "GenSigSendType" SG_ 1381 VFCVectorSUMVFCid15 0;
BA_ "GenSigSendType" SG_ 1381 VFCVectorSUMVFCid16 0;
BA_ "GenSigSendType" SG_ 1381 VFCVectorSUMVFCid17 0;
BA_ "GenSigSendType" SG_ 1381 VFCVectorSUMVFCid18 0;
BA_ "GenSigSendType" SG_ 1381 VFCVectorSUMVFCid19 0;
BA_ "GenSigSendType" SG_ 1381 VFCVectorSUMVFCid2 0;
BA_ "GenSigSendType" SG_ 1381 VFCVectorSUMVFCid20 0;
BA_ "GenSigSendType" SG_ 1381 VFCVectorSUMVFCid21 0;
BA_ "GenSigSendType" SG_ 1381 VFCVectorSUMVFCid22 0;
BA_ "GenSigSendType" SG_ 1381 VFCVectorSUMVFCid23 0;
BA_ "GenSigSendType" SG_ 1381 VFCVectorSUMVFCid24 0;
BA_ "GenSigSendType" SG_ 1381 VFCVectorSUMVFCid25 0;
BA_ "GenSigSendType" SG_ 1381 VFCVectorSUMVFCid26 0;
BA_ "GenSigSendType" SG_ 1381 VFCVectorSUMVFCid27 0;
BA_ "GenSigSendType" SG_ 1381 VFCVectorSUMVFCid28 0;
BA_ "GenSigSendType" SG_ 1381 VFCVectorSUMVFCid29 0;
BA_ "GenSigSendType" SG_ 1381 VFCVectorSUMVFCid3 0;
BA_ "GenSigSendType" SG_ 1381 VFCVectorSUMVFCid30 0;
BA_ "GenSigSendType" SG_ 1381 VFCVectorSUMVFCid31 0;
BA_ "GenSigSendType" SG_ 1381 VFCVectorSUMVFCid32 0;
BA_ "GenSigSendType" SG_ 1381 VFCVectorSUMVFCid33 0;
BA_ "GenSigSendType" SG_ 1381 VFCVectorSUMVFCid34 0;
BA_ "GenSigSendType" SG_ 1381 VFCVectorSUMVFCid35 0;
BA_ "GenSigSendType" SG_ 1381 VFCVectorSUMVFCid36 0;
BA_ "GenSigSendType" SG_ 1381 VFCVectorSUMVFCid37 0;
BA_ "GenSigSendType" SG_ 1381 VFCVectorSUMVFCid38 0;
BA_ "GenSigSendType" SG_ 1381 VFCVectorSUMVFCid39 0;
BA_ "GenSigSendType" SG_ 1381 VFCVectorSUMVFCid4 0;
BA_ "GenSigSendType" SG_ 1381 VFCVectorSUMVFCid40 0;
BA_ "GenSigSendType" SG_ 1381 VFCVectorSUMVFCid41 0;
BA_ "GenSigSendType" SG_ 1381 VFCVectorSUMVFCid42 0;
BA_ "GenSigSendType" SG_ 1381 VFCVectorSUMVFCid43 0;
BA_ "GenSigSendType" SG_ 1381 VFCVectorSUMVFCid44 0;
BA_ "GenSigSendType" SG_ 1381 VFCVectorSUMVFCid45 0;
BA_ "GenSigSendType" SG_ 1381 VFCVectorSUMVFCid46 0;
BA_ "GenSigSendType" SG_ 1381 VFCVectorSUMVFCid47 0;
BA_ "GenSigSendType" SG_ 1381 VFCVectorSUMVFCid48 0;
BA_ "GenSigSendType" SG_ 1381 VFCVectorSUMVFCid49 0;
BA_ "GenSigSendType" SG_ 1381 VFCVectorSUMVFCid5 0;
BA_ "GenSigSendType" SG_ 1381 VFCVectorSUMVFCid50 0;
BA_ "GenSigSendType" SG_ 1381 VFCVectorSUMVFCid51 0;
BA_ "GenSigSendType" SG_ 1381 VFCVectorSUMVFCid52 0;
BA_ "GenSigSendType" SG_ 1381 VFCVectorSUMVFCid53 0;
BA_ "GenSigSendType" SG_ 1381 VFCVectorSUMVFCid54 0;
BA_ "GenSigSendType" SG_ 1381 VFCVectorSUMVFCid55 0;
BA_ "GenSigSendType" SG_ 1381 VFCVectorSUMVFCid56 0;
BA_ "GenSigSendType" SG_ 1381 VFCVectorSUMVFCid57 0;
BA_ "GenSigSendType" SG_ 1381 VFCVectorSUMVFCid58 0;
BA_ "GenSigSendType" SG_ 1381 VFCVectorSUMVFCid59 0;
BA_ "GenSigSendType" SG_ 1381 VFCVectorSUMVFCid6 0;
BA_ "GenSigSendType" SG_ 1381 VFCVectorSUMVFCid60 0;
BA_ "GenSigSendType" SG_ 1381 VFCVectorSUMVFCid61 0;
BA_ "GenSigSendType" SG_ 1381 VFCVectorSUMVFCid7 0;
BA_ "GenSigSendType" SG_ 1381 VFCVectorSUMVFCid8 0;
BA_ "GenSigSendType" SG_ 1381 VFCVectorSUMVFCid9 0;
BA_ "GenSigSendType" SG_ 784 HvFanEna 0;
BA_ "GenSigSendType" SG_ 784 HvFanSpdReq 0;
BA_ "GenSigSendType" SG_ 784 HvFanSpdReqEstimd 0;
BA_ "GenSigSendType" SG_ 1285 WakeUpReasonsforECM 0;
VAL_ 769 HvFanHVLKFlt 1 "OnOff1_On" 0 "OnOff1_Off";
VAL_ 769 HvFanLifebeat 1 "OnOff1_On" 0 "OnOff1_Off";
VAL_ 769 HVFMMissingSlaveSignal 1 "Boolean_TRUE" 0 "Boolean_FALSE";
VAL_ 1289 WakeUpReasonsforHVFM 741 "WakeupReasons_871868" 740 "WakeupReasons_871957" 739 "WakeupReasons_871729" 738 "WakeupReasons_700779" 737 "WakeupReasons_839414" 736 "WakeupReasons_675025" 735 "WakeupReasons_671146" 734 "WakeupReasons_1031929" 733 "WakeupReasons_1033548" 732 "WakeupReasons_1033537" 731 "WakeupReasons_1033479" 730 "WakeupReasons_1030765" 729 "WakeupReasons_1028674" 728 "WakeupReasons_1033567" 727 "WakeupReasons_1033543" 726 "WakeupReasons_1033549" 725 "WakeupReasons_1033554" 724 "WakeupReasons_1033563" 723 "WakeupReasons_1033558" 722 "WakeupReasons_1029384" 721 "WakeupReasons_1029383" 720 "WakeupReasons_1029382" 719 "WakeupReasons_1032619" 718 "WakeupReasons_1024928" 717 "WakeupReasons_1033547" 716 "WakeupReasons_1033541" 715 "WakeupReasons_1033562" 714 "WakeupReasons_1033564" 713 "WakeupReasons_986765" 712 "WakeupReasons_1026103" 711 "WakeupReasons_1030764" 710 "WakeupReasons_1030941" 709 "WakeupReasons_1033556" 708 "WakeupReasons_1033539" 707 "WakeupReasons_1033534" 706 "WakeupReasons_1032477" 705 "WakeupReasons_1031280" 704 "WakeupReasons_1033542" 703 "WakeupReasons_1033632" 702 "WakeupReasons_1033533" 701 "WakeupReasons_1029166" 700 "WakeupReasons_1033538" 699 "WakeupReasons_1031789" 698 "WakeupReasons_1033552" 697 "WakeupReasons_1033553" 696 "WakeupReasons_1033559" 695 "WakeupReasons_1033544" 694 "WakeupReasons_1033561" 693 "WakeupReasons_1031029" 692 "WakeupReasons_1030360" 691 "WakeupReasons_1030761" 690 "WakeupReasons_1033550" 689 "WakeupReasons_1032579" 688 "WakeupReasons_1033557" 687 "WakeupReasons_1031936" 686 "WakeupReasons_1033566" 685 "WakeupReasons_1033551" 684 "WakeupReasons_1033540" 683 "WakeupReasons_1030760" 682 "WakeupReasons_1029735" 681 "WakeupReasons_1033565" 680 "WakeupReasons_852370" 679 "WakeupReasons_1033555" 678 "WakeupReasons_1033546" 677 "WakeupReasons_1032743" 676 "WakeupReasons_1032791" 675 "WakeupReasons_1033569" 674 "WakeupReasons_1031030" 673 "WakeupReasons_1028778" 672 "WakeupReasons_1030759" 671 "WakeupReasons_1031907" 670 "WakeupReasons_1033560" 669 "WakeupReasons_1031288" 668 "WakeupReasons_1030302" 667 "WakeupReasons_1031765" 666 "WakeupReasons_1031990" 665 "WakeupReasons_1028729" 664 "WakeupReasons_1030362" 663 "WakeupReasons_1030361" 662 "WakeupReasons_1030297" 661 "WakeupReasons_1030293" 660 "WakeupReasons_527345" 659 "WakeupReasons_988154" 658 "WakeupReasons_533580" 657 "WakeupReasons_533581" 656 "WakeupReasons_533576" 655 "WakeupReasons_1030255" 654 "WakeupReasons_527348" 653 "WakeupReasons_533578" 652 "WakeupReasons_527347" 651 "WakeupReasons_527346" 650 "WakeupReasons_ADCUReserve" 649 "WakeupReasons_885767" 648 "WakeupReasons_909025" 647 "WakeupReasons_909026" 646 "WakeupReasons_858177" 645 "WakeupReasons_858169" 644 "WakeupReasons_858152" 643 "WakeupReasons_973575" 642 "WakeupReason_973574" 641 "WakeupReason_987405" 640 "WakeupReason_858187" 639 "WakeupReason_988826" 638 "WakeupReason_988821" 637 "WakeupReason_987485" 636 "WakeupReason_908128" 635 "WakeupReason_908115" 634 "WakeupReason_856234" 633 "WakeupReason_856224" 632 "WakeupReason_858189" 631 "WakeupReason_858188" 630 "WakeupReason_872056" 629 "WakeupReason_870276" 628 "WakeupReason_858191" 627 "WakeupReason_847054" 626 "WakeupReason_856465" 625 "WakeupReason_872253" 624 "WakeupReason_855003" 623 "WakeupReason_855002" 622 "WakeupReason_854947" 621 "WakeupReason_855134" 620 "WakeupReason_854839" 619 "WakeupReason_854999" 618 "WakeupReason_855029" 617 "WakeupReason_714340" 616 "WakeupReason_852947" 615 "WakeupReason_852944" 614 "WakeupReason_852646" 613 "WakeupReason_852537" 612 "WakeupReason_852388" 611 "WakeupReason_852385" 610 "WakeupReason_852298" 609 "WakeupReason_852273" 608 "WakeupReason_852248" 607 "WakeupReason_852219" 606 "WakeupReason_852218" 605 "WakeupReason_852215" 604 "WakeupReason_852200" 603 "WakeupReason_852195" 602 "WakeupReason_852194" 601 "WakeupReason_852184" 600 "WakeupReason_852180" 599 "WakeupReason_852050" 598 "WakeupReason_852010" 597 "WakeupReason_851743" 596 "WakeupReason_851482" 595 "WakeupReason_702420" 594 "WakeupReason_667533" 593 "WakeupReason_645735" 592 "WakeupReason_362462" 591 "WakeupReason_361474" 590 "WakeupReason_361441" 589 "WakeupReason_846002" 588 "WakeupReason_845930" 587 "WakeupReason_842273" 586 "WakeupReason_846372" 585 "WakeupReason_675489" 584 "WakeupReason_675452" 583 "WakeupReason_298032" 582 "WakeupReason_322113" 581 "WakeupReason_320145" 580 "WakeupReason_841275" 579 "WakeupReason_839787" 578 "WakeupReason_839181" 577 "WakeupReason_714677" 576 "WakeupReason_840035" 566 "WakeupReason_839458" 565 "WakeupReason_837760" 564 "WakeupReason_702903" 563 "WakeupReason_837962" 562 "WakeupReason_703140" 561 "WakeupReason_837833" 560 "WakeupReason_839705" 559 "WakeupReason_839473" 558 "WakeupReason_838116" 557 "WakeupReason_717832" 556 "WakeupReason_714697" 555 "WakeupReason_714799" 554 "WakeupReason_714806" 553 "WakeupReason_709196" 552 "WakeupReason_710893" 551 "WakeupReason_708964" 550 "WakeupReason_715529" 549 "WakeupReason_714265" 548 "WakeupReason_714172" 547 "WakeupReason_713799" 546 "WakeupReason_706194" 545 "WakeupReason_713568" 544 "WakeupReason_710807" 543 "WakeupReason_714679" 542 "WakeupReason_714678" 541 "WakeupReason_715842" 540 "WakeupReason_714030" 539 "WakeupReason_710922" 538 "WakeupReason_716243" 537 "WakeupReason_713786" 536 "WakeupReason_714675" 535 "WakeupReason_702478" 534 "WakeupReason_713752" 533 "WakeupReasons_700530" 532 "WakeupReasons_698631" 531 "WakeupReasons_702452" 530 "WakeupReasons_700565" 529 "WakeupReasons_702402" 528 "WakeupReasons_702439" 527 "WakeupReasons_702448" 526 "WakeupReasons_701872" 525 "WakeupReasons_699114" 524 "WakeupReasons_702240" 523 "WakeupReasons_701270" 522 "WakeupReasons_533751" 521 "WakeupReasons_698581" 520 "WakeupReasons_698130" 519 "WakeupReasons_700130" 518 "WakeupReasons_699921" 517 "WakeupReasons_699919" 516 "WakeupReasons_700486" 515 "WakeupReasons_700782" 514 "WakeupReasons_696971" 513 "WakeupReasons_700692" 512 "WakeupReasons_698385" 511 "WakeupReasons_699922" 510 "WakeupReasons_697967" 509 "WakeupReasons_700684" 508 "WakeupReasons_644379" 507 "WakeupReasons_336435" 506 "WakeupReasons_683263" 505 "WakeupReasons_700554" 504 "WakeupReasons_691992" 503 "WakeupReasons_698129" 502 "WakeupReasons_696850" 501 "WakeupReasons_702088" 500 "WakeupReasons_696612" 499 "WakeupReasons_691994" 498 "WakeupReasons_700483" 497 "WakeupReasons_702204" 496 "WakeupReasons_700603" 495 "WakeupReasons_700215" 494 "WakeupReasons_701509" 493 "WakeupReasons_701508" 492 "WakeupReasons_700484" 491 "WakeupReasons_217907" 490 "WakeupReasons_194966" 489 "WakeupReasons_702174" 488 "WakeupReasons_697145" 487 "WakeupReasons_296931" 486 "WakeupReasons_700687" 485 "WakeupReasons_700686" 484 "WakeupReasons_698409" 483 "WakeupReasons_533750" 482 "WakeupReasons_700467" 481 "WakeupReasons_687404" 480 "WakeupReasons_681813" 479 "WakeupReasons_698288" 478 "WakeupReasons_698660" 477 "WakeupReasons_691993" 476 "WakeupReasons_700485" 475 "WakeupReasons_700425" 474 "WakeupReasons_702197" 473 "WakeupReasons_637992" 472 "WakeupReasons_698488" 471 "WakeupReasons_691991" 470 "WakeupReasons_692547" 469 "WakeupReasons_693914" 468 "WakeupReasons_693024" 467 "WakeupReasons_693005" 466 "WakeupReasons_667949" 465 "WakeupReasons_686281" 464 "WakeupReasons_680764" 463 "WakeupReasons_512384" 462 "WakeupReasons_692019" 461 "WakeupReasons_533850" 460 "WakeupReasons_533849" 459 "WakeupReasons_667188" 458 "WakeupReasons_514652" 457 "WakeupReasons_514651" 456 "WakeupReasons_112024" 455 "WakeupReasons_300690" 454 "WakeupReasons_299532" 453 "WakeupReasons_299531" 452 "WakeupReasons_299120" 451 "WakeupReasons_273516" 450 "WakeupReasons_265694" 449 "WakeupReasons_692439" 448 "WakeupReasons_354831" 447 "WakeupReasons_680765" 446 "WakeupReasons_45895" 445 "WakeupReasons_644275" 444 "WakeupReasons_351189" 443 "WakeupReasons_226570" 442 "WakeupReasons_654489" 441 "WakeupReasons_110181" 440 "WakeupReasons_226569" 439 "WakeupReasons_45896" 438 "WakeupReasons_112031" 437 "WakeupReasons_110173" 436 "WakeupReasons_677781" 435 "WakeupReasons_690939" 434 "WakeupReasons_354809" 433 "WakeupReasons_692022" 432 "WakeupReasons_690593" 431 "WakeupReasons_226571" 430 "WakeupReasons_675594" 429 "WakeupReasons_226565" 428 "WakeupReasons_692020" 427 "WakeupReasons_112035" 426 "WakeupReasons_112027" 425 "WakeupReasons_354672" 424 "WakeupReasons_168967" 423 "WakeupReasons_354674" 422 "WakeupReasons_168968" 421 "WakeupReasons_641483" 420 "WakeupReasons_641482" 419 "WakeupReasons_265698" 418 "WakeupReasons_265699" 417 "WakeupReasons_360491" 416 "WakeupReasons_357498" 415 "WakeupReasons_170290" 414 "WakeupReasons_690385" 413 "WakeupReasons_692021" 412 "WakeupReasons_91254" 411 "WakeupReasons_346654" 410 "WakeupReasons_200637" 409 "WakeupReasons_170285" 408 "WakeupReasons_265678" 407 "WakeupReasons_683934" 406 "WakeupReasons_680763" 405 "WakeupReasons_682074" 404 "WakeupReasons_682154" 403 "WakeupReasons_682152" 402 "WakeupReasons_682155" 401 "WakeupReasons_682153" 400 "WakeupReasons_682078" 399 "WakeupReasons_682076" 398 "WakeupReasons_682077" 397 "WakeupReasons_676285" 396 "WakeupReasons_681023" 395 "WakeupReasons_682023" 394 "WakeupReasons_681789" 393 "WakeupReasons_682688" 392 "WakeupReasons_682037" 391 "WakeupReasons_682032" 390 "WakeupReasons_681915" 389 "WakeupReasons_674839" 388 "WakeupReasons_682034" 387 "WakeupReasons_681711" 386 "WakeupReasons_681031" 385 "WakeupReasons_681134" 384 "WakeupReasons_670462" 383 "WakeupReasons_681028" 382 "WakeupReasons_680975" 381 "WakeupReasons_680974" 380 "WakeupReasons_668523" 379 "WakeupReasons_669822" 378 "WakeupReasons_680712" 377 "WakeupReasons_671005" 376 "WakeupReasons_177214" 375 "WakeupReasons_45655" 374 "WakeupReasons_667872" 373 "WakeupReasons_264964" 372 "WakeupReasons_262871" 371 "WakeupReasons_264691" 370 "WakeupReasons_297056" 369 "WakeupReasons_233755" 368 "WakeupReasons_145161" 367 "WakeupReasons_667842" 366 "WakeupReasons_46020" 365 "WakeupReasons_667874" 364 "WakeupReasons_667981" 363 "WakeupReasons_224211" 362 "WakeupReasons_45902" 361 "WakeupReasons_329457" 360 "WakeupReasons_88458" 359 "WakeupReasons_45900" 358 "WakeupReasons_83199" 357 "WakeupReasons_532933" 356 "WakeupReasons_532932" 355 "WakeupReasons_670942" 354 "WakeupReasons_305818" 353 "WakeupReasons_75103" 352 "WakeupReasons_667987" 351 "WakeupReasons_667983" 350 "WakeupReasons_675745" 349 "WakeupReasons_356598" 348 "WakeupReasons_128671" 347 "WakeupReasons_69216" 346 "WakeupReasons_264697" 345 "WakeupReasons_264943" 344 "WakeupReasons_197644" 343 "WakeupReasons_675564" 342 "WakeupReasons_657120" 341 "WakeupReasons_265745" 340 "WakeupReasons_657121" 339 "WakeupReasons_667982" 338 "WakeupReasons_674223" 337 "WakeupReasons_127926" 336 "WakeupReasons_127924" 335 "WakeupReasons_262872" 334 "WakeupReasons_45848" 333 "WakeupReasons_45847" 332 "WakeupReasons_45846" 331 "WakeupReasons_667869" 330 "WakeupReasons_45890" 329 "WakeupReasons_45888" 328 "WakeupReasons_670962" 327 "WakeupReasons_667973" 326 "WakeupReasons_45877" 325 "WakeupReasons_667980" 324 "WakeupReasons_45876" 323 "WakeupReasons_45871" 322 "WakeupReasons_45875" 321 "WakeupReasons_45872" 320 "WakeupReasons_45870" 319 "WakeupReasons_45869" 318 "WakeupReasons_80608" 317 "WakeupReasons_45898" 316 "WakeupReasons_45897" 315 "WakeupReasons_69679" 314 "WakeupReasons_69678" 313 "WakeupReasons_45887" 312 "WakeupReasons_263473" 311 "WakeupReasons_265131" 310 "WakeupReasons_268983" 309 "WakeupReasons_139075" 308 "WakeupReasons_200090" 307 "WakeupReasons_199714" 306 "WakeupReasons_80609" 305 "WakeupReasons_106669" 304 "WakeupReasons_675742" 303 "WakeupReasons_46017" 302 "WakeupReasons_670354" 301 "WakeupReasons_667985" 300 "WakeupReasons_670966" 299 "WakeupReasons_667871" 298 "WakeupReasons_193474" 297 "WakeupReasons_113348" 296 "WakeupReasons_532556" 295 "WakeupReasons_532555" 294 "WakeupReasons_667988" 293 "WakeupReasons_182918" 292 "WakeupReasons_311279" 291 "WakeupReasons_667848" 290 "WakeupReasons_667850" 289 "WakeupReasons_668393" 288 "WakeupReasons_668395" 287 "WakeupReasons_670753" 286 "WakeupReasons_667922" 285 "WakeupReasons_669447" 284 "WakeupReasons_670928" 283 "WakeupReasons_669465" 282 "WakeupReasons_676265" 281 "WakeupReasons_667947" 280 "WakeupReasons_667879" 279 "WakeupReasons_675837" 278 "WakeupReasons_675494" 277 "WakeupReasons_674958" 276 "WakeupReasons_675064" 275 "WakeupReasons_674953" 274 "WakeupReasons_658188" 273 "WakeupReasons_337991" 272 "WakeupReasons_197653" 271 "WakeupReasons_269140" 270 "WakeupReasons_312881" 269 "WakeupReasons_215560" 268 "WakeupReasons_269034" 267 "WakeupReasons_4471" 266 "WakeupReasons_185490" 265 "WakeupReasons_185457" 264 "WakeupReasons_198452" 263 "WakeupReasons_200683" 262 "WakeupReasons_358832" 261 "WakeupReasons_NMPDUReceived" 260 "WakeupReasons_670345" 259 "WakeupReasons_109467" 258 "WakeupReasons_109466" 257 "WakeupReasons_636801" 256 "WakeupReasons_45849" 255 "WakeupReasons_45850" 254 "WakeupReasons_45851" 253 "WakeupReasons_45852" 252 "WakeupReasons_45854" 251 "WakeupReasons_45853" 250 "WakeupReasons_45856" 249 "WakeupReasons_533872" 248 "WakeupReasons_516327" 247 "WakeupReasons_359559" 246 "WakeupReasons_241902" 245 "WakeupReasons_533372" 244 "WakeupReasons_533371" 243 "WakeupReasons_533370" 242 "WakeupReasons_315981" 241 "WakeupReasons_45858" 240 "WakeupReasons_668529" 239 "WakeupReasons_670087" 238 "WakeupReasons_668531" 237 "WakeupReasons_223920" 236 "WakeupReasons_176748" 235 "WakeupReasons_146470" 234 "WakeupReasons_112799" 233 "WakeupReasons_95949" 232 "WakeupReasons_156440" 231 "WakeupReasons_166267" 230 "WakeupReasons_101727" 229 "WakeupReasons_101728" 228 "WakeupReasons_101725" 227 "WakeupReasons_101706" 226 "WakeupReasons_659350" 225 "WakeupReasons_667820" 224 "WakeupReasons_331194" 223 "WakeupReasons_652546" 222 "WakeupReasons_224553" 221 "WakeupReasons_224552" 220 "WakeupReasons_110885" 219 "WakeupReasons_667953" 218 "WakeupReasons_667962" 217 "WakeupReasons_224550" 216 "WakeupReasons_197665" 215 "WakeupReasons_225961" 214 "WakeupReasons_198433" 213 "WakeupReasons_526438" 212 "WakeupReasons_316796" 211 "WakeupReasons_335068" 210 "WakeupReasons_535214" 209 "WakeupReasons_264726" 208 "WakeupReasons_360542" 207 "WakeupReasons_531743" 206 "WakeupReasons_226967" 205 "WakeupReasons_318382" 204 "WakeupReasons_199159" 203 "WakeupReasons_223715" 202 "WakeupReasons_643973" 201 "WakeupReasons_319401" 200 "WakeupReasons_264712" 199 "WakeupReasons_526426" 198 "WakeupReasons_533050" 197 "WakeupReasons_265937" 196 "WakeupReasons_108834" 195 "WakeupReasons_636556" 194 "WakeupReasons_655340" 193 "WakeupReasons_320895" 192 "WakeupReasons_321077" 191 "WakeupReasons_321323" 190 "WakeupReasons_321319" 189 "WakeupReasons_321057" 188 "WakeupReasons_359187" 187 "WakeupReasons_321317" 186 "WakeupReasons_355214" 185 "WakeupReasons_652361" 184 "WakeupReasons_192030" 183 "WakeupReasons_534145" 182 "WakeupReasons_526445" 181 "WakeupReasons_360299" 180 "WakeupReasons_525705" 179 "WakeupReasons_534077" 178 "WakeupReasons_359211" 177 "WakeupReasons_300681" 176 "WakeupReasons_198484" 175 "WakeupReasons_356549" 174 "WakeupReasons_360543" 173 "WakeupReasons_318342" 172 "WakeupReasons_299547" 171 "WakeupReasons_646109" 170 "WakeupReasons_645753" 169 "WakeupReasons_514502" 168 "WakeupReasons_515804" 167 "WakeupReasons_298808" 166 "WakeupReasons_265330" 165 "WakeupReasons_265328" 164 "WakeupReasons_265305" 163 "WakeupReasons_361279" 162 "WakeupReasons_361272" 161 "WakeupReasons_160596" 160 "WakeupReasons_197648" 159 "WakeupReasons_658603" 158 "WakeupReasons_322857" 157 "WakeupReasons_108810" 156 "WakeupReasons_179103" 155 "WakeupReasons_321845" 154 "WakeupReasons_340667" 153 "WakeupReasons_299117" 152 "WakeupReasons_514503" 151 "WakeupReasons_532007" 150 "WakeupReasons_337565" 149 "WakeupReasons_320631" 148 "WakeupReasons_354791" 147 "WakeupReasons_317616" 146 "WakeupReasons_644550" 145 "WakeupReasons_265232" 144 "WakeupReasons_514545" 143 "WakeupReasons_526429" 142 "WakeupReasons_265569" 141 "WakeupReasons_108841" 140 "WakeupReasons_160602" 139 "WakeupReasons_160597" 138 "WakeupReasons_264958" 137 "WakeupReasons_300682" 136 "WakeupReasons_224634" 135 "WakeupReasons_224617" 134 "WakeupReasons_220322" 133 "WakeupReasons_300427" 132 "WakeupReasons_269156" 131 "WakeupReasons_145462" 130 "WakeupReasons_145454" 129 "WakeupReasons_145419" 128 "WakeupReasons_145288" 127 "WakeupReasons_145373" 126 "WakeupReasons_145385" 125 "WakeupReasons_145362" 124 "WakeupReasons_145399" 123 "WakeupReasons_145388" 122 "WakeupReasons_145330" 121 "WakeupReasons_152774" 120 "WakeupReasons_145319" 119 "WakeupReasons_145311" 118 "WakeupReasons_106774" 117 "WakeupReasons_533044" 116 "WakeupReasons_636692" 115 "WakeupReasons_355409" 114 "WakeupReasons_133749" 113 "WakeupReasons_156412" 112 "WakeupReasons_320287" 111 "WakeupReasons_201348" 110 "WakeupReasons_264962" 109 "WakeupReasons_169884" 108 "WakeupReasons_45867" 107 "WakeupReasons_45866" 106 "WakeupReasons_659549" 105 "WakeupReasons_45864" 104 "WakeupReasons_201815" 103 "WakeupReasons_224831" 102 "WakeupReasons_222553" 101 "WakeupReasons_140678" 100 "WakeupReasons_169945" 99 "WakeupReasons_95444" 98 "WakeupReasons_145688" 97 "WakeupReasons_356190" 96 "WakeupReasons_264934" 95 "WakeupReasons_264932" 94 "WakeupReasons_152786" 93 "WakeupReasons_144970" 92 "WakeupReasons_186489" 91 "WakeupReasons_144897" 90 "WakeupReasons_199172" 89 "WakeupReasons_145707" 88 "WakeupReasons_152237" 87 "WakeupReasons_67182" 86 "WakeupReasons_338820" 85 "WakeupReasons_634710" 84 "WakeupReasons_109387" 83 "WakeupReasons_320126" 82 "WakeupReasons_109367" 81 "WakeupReasons_315364" 80 "WakeupReasons_297868" 79 "WakeupReasons_645810" 78 "WakeupReasons_634696" 77 "WakeupReasons_138997" 76 "WakeupReasons_360006" 75 "WakeupReasons_224061" 74 "WakeupReasons_68481" 73 "WakeupReasons_109364" 72 "WakeupReasons_68644" 71 "WakeupReasons_224065" 70 "WakeupReasons_119273" 69 "WakeupReasons_109382" 68 "WakeupReasons_360008" 67 "WakeupReasons_68676" 66 "WakeupReasons_645094" 65 "WakeupReasons_361509" 64 "WakeupReasons_361505" 63 "WakeupReasons_360904" 62 "WakeupReasons_355601" 61 "WakeupReasons_320277" 60 "WakeupReasons_319422" 59 "WakeupReasons_320282" 58 "WakeupReasons_169894" 57 "WakeupReasons_266860" 56 "WakeupReasons_45656" 55 "WakeupReasons_21997" 54 "WakeupReasons_225696" 53 "WakeupReasons_200156" 52 "WakeupReasons_161066" 51 "WakeupReasons_185670" 50 "WakeupReasons_197826" 49 "WakeupReasons_176921" 48 "WakeupReasons_108776" 47 "WakeupReasons_265333" 46 "WakeupReasons_100281" 45 "WakeupReasons_100278" 44 "WakeupReasons_100300" 43 "WakeupReasons_100275" 42 "WakeupReasons_100298" 41 "WakeupReasons_319139" 40 "WakeupReasons_170807" 39 "WakeupReasons_200937" 38 "WakeupReasons_182033" 37 "WakeupReasons_191050" 36 "WakeupReasons_264876" 35 "WakeupReasons_197642" 34 "WakeupReasons_170865" 33 "WakeupReasons_168966" 32 "WakeupReasons_667948" 31 "WakeupReasons_169655" 30 "WakeupReasons_667945" 29 "WakeupReasons_74188" 28 "WakeupReasons_321583" 27 "WakeupReasons_88125" 26 "WakeupReasons_88123" 25 "WakeupReasons_91253" 24 "WakeupReasons_21973" 23 "WakeupReasons_140084" 22 "WakeupReasons_45657" 21 "WakeupReasons_45659" 20 "WakeupReasons_22100" 19 "WakeupReasons_22013" 18 "WakeupReasons_22005" 17 "WakeupReasons_45794" 16 "WakeupReasons_45793" 15 "WakeupReasons_21901" 14 "WakeupReasons_658500" 13 "WakeupReasons_269739" 12 "WakeupReasons_269735" 11 "WakeupReasons_269740" 10 "WakeupReasons_22060" 9 "WakeupReasons_49446" 8 "WakeupReasons_22058" 7 "WakeupReasons_45654" 6 "WakeupReasons_264933" 5 "WakeupReasons_197643" 4 "WakeupReasons_168965" 3 "WakeupReasons_667951" 2 "WakeupReasons_169654" 1 "WakeupReasons_667950" 0 "WakeupReasons_0";
VAL_ 1353 VFCVectorHVFMVFCid0 1 "VFCOnOff_On" 0 "VFCOnOff_Off";
VAL_ 1353 VFCVectorHVFMVFCid1 1 "VFCOnOff_On" 0 "VFCOnOff_Off";
VAL_ 1353 VFCVectorHVFMVFCid10 1 "VFCOnOff_On" 0 "VFCOnOff_Off";
VAL_ 1353 VFCVectorHVFMVFCid11 1 "VFCOnOff_On" 0 "VFCOnOff_Off";
VAL_ 1353 VFCVectorHVFMVFCid12 1 "VFCOnOff_On" 0 "VFCOnOff_Off";
VAL_ 1353 VFCVectorHVFMVFCid13 1 "VFCOnOff_On" 0 "VFCOnOff_Off";
VAL_ 1353 VFCVectorHVFMVFCid14 1 "VFCOnOff_On" 0 "VFCOnOff_Off";
VAL_ 1353 VFCVectorHVFMVFCid15 1 "VFCOnOff_On" 0 "VFCOnOff_Off";
VAL_ 1353 VFCVectorHVFMVFCid16 1 "VFCOnOff_On" 0 "VFCOnOff_Off";
VAL_ 1353 VFCVectorHVFMVFCid17 1 "VFCOnOff_On" 0 "VFCOnOff_Off";
VAL_ 1353 VFCVectorHVFMVFCid18 1 "VFCOnOff_On" 0 "VFCOnOff_Off";
VAL_ 1353 VFCVectorHVFMVFCid19 1 "VFCOnOff_On" 0 "VFCOnOff_Off";
VAL_ 1353 VFCVectorHVFMVFCid2 1 "VFCOnOff_On" 0 "VFCOnOff_Off";
VAL_ 1353 VFCVectorHVFMVFCid20 1 "VFCOnOff_On" 0 "VFCOnOff_Off";
VAL_ 1353 VFCVectorHVFMVFCid21 1 "VFCOnOff_On" 0 "VFCOnOff_Off";
VAL_ 1353 VFCVectorHVFMVFCid22 1 "VFCOnOff_On" 0 "VFCOnOff_Off";
VAL_ 1353 VFCVectorHVFMVFCid23 1 "VFCOnOff_On" 0 "VFCOnOff_Off";
VAL_ 1353 VFCVectorHVFMVFCid24 1 "VFCOnOff_On" 0 "VFCOnOff_Off";
VAL_ 1353 VFCVectorHVFMVFCid25 1 "VFCOnOff_On" 0 "VFCOnOff_Off";
VAL_ 1353 VFCVectorHVFMVFCid26 1 "VFCOnOff_On" 0 "VFCOnOff_Off";
VAL_ 1353 VFCVectorHVFMVFCid27 1 "VFCOnOff_On" 0 "VFCOnOff_Off";
VAL_ 1353 VFCVectorHVFMVFCid28 1 "VFCOnOff_On" 0 "VFCOnOff_Off";
VAL_ 1353 VFCVectorHVFMVFCid29 1 "VFCOnOff_On" 0 "VFCOnOff_Off";
VAL_ 1353 VFCVectorHVFMVFCid3 1 "VFCOnOff_On" 0 "VFCOnOff_Off";
VAL_ 1353 VFCVectorHVFMVFCid30 1 "VFCOnOff_On" 0 "VFCOnOff_Off";
VAL_ 1353 VFCVectorHVFMVFCid31 1 "VFCOnOff_On" 0 "VFCOnOff_Off";
VAL_ 1353 VFCVectorHVFMVFCid32 1 "VFCOnOff_On" 0 "VFCOnOff_Off";
VAL_ 1353 VFCVectorHVFMVFCid33 1 "VFCOnOff_On" 0 "VFCOnOff_Off";
VAL_ 1353 VFCVectorHVFMVFCid34 1 "VFCOnOff_On" 0 "VFCOnOff_Off";
VAL_ 1353 VFCVectorHVFMVFCid35 1 "VFCOnOff_On" 0 "VFCOnOff_Off";
VAL_ 1353 VFCVectorHVFMVFCid36 1 "VFCOnOff_On" 0 "VFCOnOff_Off";
VAL_ 1353 VFCVectorHVFMVFCid37 1 "VFCOnOff_On" 0 "VFCOnOff_Off";
VAL_ 1353 VFCVectorHVFMVFCid38 1 "VFCOnOff_On" 0 "VFCOnOff_Off";
VAL_ 1353 VFCVectorHVFMVFCid39 1 "VFCOnOff_On" 0 "VFCOnOff_Off";
VAL_ 1353 VFCVectorHVFMVFCid4 1 "VFCOnOff_On" 0 "VFCOnOff_Off";
VAL_ 1353 VFCVectorHVFMVFCid40 1 "VFCOnOff_On" 0 "VFCOnOff_Off";
VAL_ 1353 VFCVectorHVFMVFCid41 1 "VFCOnOff_On" 0 "VFCOnOff_Off";
VAL_ 1353 VFCVectorHVFMVFCid42 1 "VFCOnOff_On" 0 "VFCOnOff_Off";
VAL_ 1353 VFCVectorHVFMVFCid43 1 "VFCOnOff_On" 0 "VFCOnOff_Off";
VAL_ 1353 VFCVectorHVFMVFCid44 1 "VFCOnOff_On" 0 "VFCOnOff_Off";
VAL_ 1353 VFCVectorHVFMVFCid45 1 "VFCOnOff_On" 0 "VFCOnOff_Off";
VAL_ 1353 VFCVectorHVFMVFCid46 1 "VFCOnOff_On" 0 "VFCOnOff_Off";
VAL_ 1353 VFCVectorHVFMVFCid47 1 "VFCOnOff_On" 0 "VFCOnOff_Off";
VAL_ 1353 VFCVectorHVFMVFCid48 1 "VFCOnOff_On" 0 "VFCOnOff_Off";
VAL_ 1353 VFCVectorHVFMVFCid49 1 "VFCOnOff_On" 0 "VFCOnOff_Off";
VAL_ 1353 VFCVectorHVFMVFCid5 1 "VFCOnOff_On" 0 "VFCOnOff_Off";
VAL_ 1353 VFCVectorHVFMVFCid50 1 "VFCOnOff_On" 0 "VFCOnOff_Off";
VAL_ 1353 VFCVectorHVFMVFCid51 1 "VFCOnOff_On" 0 "VFCOnOff_Off";
VAL_ 1353 VFCVectorHVFMVFCid52 1 "VFCOnOff_On" 0 "VFCOnOff_Off";
VAL_ 1353 VFCVectorHVFMVFCid53 1 "VFCOnOff_On" 0 "VFCOnOff_Off";
VAL_ 1353 VFCVectorHVFMVFCid54 1 "VFCOnOff_On" 0 "VFCOnOff_Off";
VAL_ 1353 VFCVectorHVFMVFCid55 1 "VFCOnOff_On" 0 "VFCOnOff_Off";
VAL_ 1353 VFCVectorHVFMVFCid56 1 "VFCOnOff_On" 0 "VFCOnOff_Off";
VAL_ 1353 VFCVectorHVFMVFCid57 1 "VFCOnOff_On" 0 "VFCOnOff_Off";
VAL_ 1353 VFCVectorHVFMVFCid58 1 "VFCOnOff_On" 0 "VFCOnOff_Off";
VAL_ 1353 VFCVectorHVFMVFCid59 1 "VFCOnOff_On" 0 "VFCOnOff_Off";
VAL_ 1353 VFCVectorHVFMVFCid6 1 "VFCOnOff_On" 0 "VFCOnOff_Off";
VAL_ 1353 VFCVectorHVFMVFCid60 1 "VFCOnOff_On" 0 "VFCOnOff_Off";
VAL_ 1353 VFCVectorHVFMVFCid61 1 "VFCOnOff_On" 0 "VFCOnOff_Off";
VAL_ 1353 VFCVectorHVFMVFCid7 1 "VFCOnOff_On" 0 "VFCOnOff_Off";
VAL_ 1353 VFCVectorHVFMVFCid8 1 "VFCOnOff_On" 0 "VFCOnOff_Off";
VAL_ 1353 VFCVectorHVFMVFCid9 1 "VFCOnOff_On" 0 "VFCOnOff_Off";
VAL_ 81 TVCBrkTqReqFrntLeCtrlMod 3 "CtrlMod3_Resd" 2 "CtrlMod3_Min" 1 "CtrlMod3_Max" 0 "CtrlMod3_NotReqd";
VAL_ 81 TVCBrkTqReqFrntRiCtrlMod 3 "CtrlMod3_Resd" 2 "CtrlMod3_Min" 1 "CtrlMod3_Max" 0 "CtrlMod3_NotReqd";
VAL_ 81 TVCBrkTqReqReLeCtrlMod 3 "CtrlMod3_Resd" 2 "CtrlMod3_Min" 1 "CtrlMod3_Max" 0 "CtrlMod3_NotReqd";
VAL_ 81 TVCBrkTqReqReRiCtrlMod 3 "CtrlMod3_Resd" 2 "CtrlMod3_Min" 1 "CtrlMod3_Max" 0 "CtrlMod3_NotReqd";
VAL_ 81 TVCPrpsnTqDistActv 1 "ActvInActv_Inactive" 0 "ActvInActv_Active";
VAL_ 81 TVCReWhlSteerCtrlStsForTvcTVCReWhlSteerCtrlStsForTvc 7 "FrntWhlSteerCtrlSts_RESERVED4" 6 "FrntWhlSteerCtrlSts_RESERVED3" 5 "FrntWhlSteerCtrlSts_RESERVED2" 4 "FrntWhlSteerCtrlSts_RESERVED1" 3 "FrntWhlSteerCtrlSts_Err" 2 "FrntWhlSteerCtrlSts_Req" 1 "FrntWhlSteerCtrlSts_NotReq" 0 "FrntWhlSteerCtrlSts_INIT";
VAL_ 81 TVCTqDistbnFaultForGVMCTVCTqDistbnFaultForGVMC 3 "FaultForGVMC_Reserved" 2 "FaultForGVMC_Faultforotherreason" 1 "FaultForGVMC_FaultforFusa" 0 "FaultForGVMC_NoFault";
VAL_ 257 MotDynCtrlStsReLeDmcSts 6 "DmcSts_Reserve" 5 "DmcSts_YrLim" 4 "DmcSts_OnInc" 3 "DmcSts_Fault" 2 "DmcSts_Off" 1 "DmcSts_OnDec" 0 "DmcSts_Init";
VAL_ 257 MotDynCtrlStsReRiDmcSts 6 "DmcSts_Reserve" 5 "DmcSts_YrLim" 4 "DmcSts_OnInc" 3 "DmcSts_Fault" 2 "DmcSts_Off" 1 "DmcSts_OnDec" 0 "DmcSts_Init";
VAL_ 50 ADataRawSafeALat1Qf 3 "Qf1_DataCalcdWithDevDefd" 2 "Qf1_DevOfDataNotWithinRngAllwd" 1 "Qf1_DataTmpUndefdAndEvlnInProgs" 0 "Qf1_DevOfDataUndefd";
VAL_ 50 ADataRawSafeALgt1Qf 3 "Qf1_DataCalcdWithDevDefd" 2 "Qf1_DevOfDataNotWithinRngAllwd" 1 "Qf1_DataTmpUndefdAndEvlnInProgs" 0 "Qf1_DevOfDataUndefd";
VAL_ 50 ADataRawSafeAVertQf 3 "Qf1_DataCalcdWithDevDefd" 2 "Qf1_DevOfDataNotWithinRngAllwd" 1 "Qf1_DataTmpUndefdAndEvlnInProgs" 0 "Qf1_DevOfDataUndefd";
VAL_ 50 AgDataRawSafeRollRateQf 3 "Qf1_DataCalcdWithDevDefd" 2 "Qf1_DevOfDataNotWithinRngAllwd" 1 "Qf1_DataTmpUndefdAndEvlnInProgs" 0 "Qf1_DevOfDataUndefd";
VAL_ 50 AgDataRawSafeYawRateQf 3 "Qf1_DataCalcdWithDevDefd" 2 "Qf1_DevOfDataNotWithinRngAllwd" 1 "Qf1_DataTmpUndefdAndEvlnInProgs" 0 "Qf1_DevOfDataUndefd";
VAL_ 50 AsyDataWithCmpSafeALat1Qf 3 "Qf1_DataCalcdWithDevDefd" 2 "Qf1_DevOfDataNotWithinRngAllwd" 1 "Qf1_DataTmpUndefdAndEvlnInProgs" 0 "Qf1_DevOfDataUndefd";
VAL_ 50 AsyDataWithCmpSafeALgt1Qf 3 "Qf1_DataCalcdWithDevDefd" 2 "Qf1_DevOfDataNotWithinRngAllwd" 1 "Qf1_DataTmpUndefdAndEvlnInProgs" 0 "Qf1_DevOfDataUndefd";
VAL_ 50 AsyDataWithCmpSafeYawRateQf 3 "Qf1_DataCalcdWithDevDefd" 2 "Qf1_DevOfDataNotWithinRngAllwd" 1 "Qf1_DataTmpUndefdAndEvlnInProgs" 0 "Qf1_DevOfDataUndefd";
VAL_ 50 IntgtIMUDataRawSafeALat1Qf 3 "Qf1_DataCalcdWithDevDefd" 2 "Qf1_DevOfDataNotWithinRngAllwd" 1 "Qf1_DataTmpUndefdAndEvlnInProgs" 0 "Qf1_DevOfDataUndefd";
VAL_ 50 IntgtIMUDataRawSafeALgt1Qf 3 "Qf1_DataCalcdWithDevDefd" 2 "Qf1_DevOfDataNotWithinRngAllwd" 1 "Qf1_DataTmpUndefdAndEvlnInProgs" 0 "Qf1_DevOfDataUndefd";
VAL_ 50 IntgtIMUDataRawSafeAVertQf 3 "Qf1_DataCalcdWithDevDefd" 2 "Qf1_DevOfDataNotWithinRngAllwd" 1 "Qf1_DataTmpUndefdAndEvlnInProgs" 0 "Qf1_DevOfDataUndefd";
VAL_ 50 IntgtIMUDataRawSafePitchRateQf 3 "Qf1_DataCalcdWithDevDefd" 2 "Qf1_DevOfDataNotWithinRngAllwd" 1 "Qf1_DataTmpUndefdAndEvlnInProgs" 0 "Qf1_DevOfDataUndefd";
VAL_ 50 IntgtIMUDataRawSafeRollRateQf 3 "Qf1_DataCalcdWithDevDefd" 2 "Qf1_DevOfDataNotWithinRngAllwd" 1 "Qf1_DataTmpUndefdAndEvlnInProgs" 0 "Qf1_DevOfDataUndefd";
VAL_ 50 IntgtIMUDataRawSafeYawRateQf 3 "Qf1_DataCalcdWithDevDefd" 2 "Qf1_DevOfDataNotWithinRngAllwd" 1 "Qf1_DataTmpUndefdAndEvlnInProgs" 0 "Qf1_DevOfDataUndefd";
VAL_ 63 CrashStsSafeSts 1 "CrashSts2_Crash" 0 "CrashSts2_NoCrash";
VAL_ 1286 WakeUpReasonsforSRS 741 "WakeupReasons_871868" 740 "WakeupReasons_871957" 739 "WakeupReasons_871729" 738 "WakeupReasons_700779" 737 "WakeupReasons_839414" 736 "WakeupReasons_675025" 735 "WakeupReasons_671146" 734 "WakeupReasons_1031929" 733 "WakeupReasons_1033548" 732 "WakeupReasons_1033537" 731 "WakeupReasons_1033479" 730 "WakeupReasons_1030765" 729 "WakeupReasons_1028674" 728 "WakeupReasons_1033567" 727 "WakeupReasons_1033543" 726 "WakeupReasons_1033549" 725 "WakeupReasons_1033554" 724 "WakeupReasons_1033563" 723 "WakeupReasons_1033558" 722 "WakeupReasons_1029384" 721 "WakeupReasons_1029383" 720 "WakeupReasons_1029382" 719 "WakeupReasons_1032619" 718 "WakeupReasons_1024928" 717 "WakeupReasons_1033547" 716 "WakeupReasons_1033541" 715 "WakeupReasons_1033562" 714 "WakeupReasons_1033564" 713 "WakeupReasons_986765" 712 "WakeupReasons_1026103" 711 "WakeupReasons_1030764" 710 "WakeupReasons_1030941" 709 "WakeupReasons_1033556" 708 "WakeupReasons_1033539" 707 "WakeupReasons_1033534" 706 "WakeupReasons_1032477" 705 "WakeupReasons_1031280" 704 "WakeupReasons_1033542" 703 "WakeupReasons_1033632" 702 "WakeupReasons_1033533" 701 "WakeupReasons_1029166" 700 "WakeupReasons_1033538" 699 "WakeupReasons_1031789" 698 "WakeupReasons_1033552" 697 "WakeupReasons_1033553" 696 "WakeupReasons_1033559" 695 "WakeupReasons_1033544" 694 "WakeupReasons_1033561" 693 "WakeupReasons_1031029" 692 "WakeupReasons_1030360" 691 "WakeupReasons_1030761" 690 "WakeupReasons_1033550" 689 "WakeupReasons_1032579" 688 "WakeupReasons_1033557" 687 "WakeupReasons_1031936" 686 "WakeupReasons_1033566" 685 "WakeupReasons_1033551" 684 "WakeupReasons_1033540" 683 "WakeupReasons_1030760" 682 "WakeupReasons_1029735" 681 "WakeupReasons_1033565" 680 "WakeupReasons_852370" 679 "WakeupReasons_1033555" 678 "WakeupReasons_1033546" 677 "WakeupReasons_1032743" 676 "WakeupReasons_1032791" 675 "WakeupReasons_1033569" 674 "WakeupReasons_1031030" 673 "WakeupReasons_1028778" 672 "WakeupReasons_1030759" 671 "WakeupReasons_1031907" 670 "WakeupReasons_1033560" 669 "WakeupReasons_1031288" 668 "WakeupReasons_1030302" 667 "WakeupReasons_1031765" 666 "WakeupReasons_1031990" 665 "WakeupReasons_1028729" 664 "WakeupReasons_1030362" 663 "WakeupReasons_1030361" 662 "WakeupReasons_1030297" 661 "WakeupReasons_1030293" 660 "WakeupReasons_527345" 659 "WakeupReasons_988154" 658 "WakeupReasons_533580" 657 "WakeupReasons_533581" 656 "WakeupReasons_533576" 655 "WakeupReasons_1030255" 654 "WakeupReasons_527348" 653 "WakeupReasons_533578" 652 "WakeupReasons_527347" 651 "WakeupReasons_527346" 650 "WakeupReasons_ADCUReserve" 649 "WakeupReasons_885767" 648 "WakeupReasons_909025" 647 "WakeupReasons_909026" 646 "WakeupReasons_858177" 645 "WakeupReasons_858169" 644 "WakeupReasons_858152" 643 "WakeupReasons_973575" 642 "WakeupReason_973574" 641 "WakeupReason_987405" 640 "WakeupReason_858187" 639 "WakeupReason_988826" 638 "WakeupReason_988821" 637 "WakeupReason_987485" 636 "WakeupReason_908128" 635 "WakeupReason_908115" 634 "WakeupReason_856234" 633 "WakeupReason_856224" 632 "WakeupReason_858189" 631 "WakeupReason_858188" 630 "WakeupReason_872056" 629 "WakeupReason_870276" 628 "WakeupReason_858191" 627 "WakeupReason_847054" 626 "WakeupReason_856465" 625 "WakeupReason_872253" 624 "WakeupReason_855003" 623 "WakeupReason_855002" 622 "WakeupReason_854947" 621 "WakeupReason_855134" 620 "WakeupReason_854839" 619 "WakeupReason_854999" 618 "WakeupReason_855029" 617 "WakeupReason_714340" 616 "WakeupReason_852947" 615 "WakeupReason_852944" 614 "WakeupReason_852646" 613 "WakeupReason_852537" 612 "WakeupReason_852388" 611 "WakeupReason_852385" 610 "WakeupReason_852298" 609 "WakeupReason_852273" 608 "WakeupReason_852248" 607 "WakeupReason_852219" 606 "WakeupReason_852218" 605 "WakeupReason_852215" 604 "WakeupReason_852200" 603 "WakeupReason_852195" 602 "WakeupReason_852194" 601 "WakeupReason_852184" 600 "WakeupReason_852180" 599 "WakeupReason_852050" 598 "WakeupReason_852010" 597 "WakeupReason_851743" 596 "WakeupReason_851482" 595 "WakeupReason_702420" 594 "WakeupReason_667533" 593 "WakeupReason_645735" 592 "WakeupReason_362462" 591 "WakeupReason_361474" 590 "WakeupReason_361441" 589 "WakeupReason_846002" 588 "WakeupReason_845930" 587 "WakeupReason_842273" 586 "WakeupReason_846372" 585 "WakeupReason_675489" 584 "WakeupReason_675452" 583 "WakeupReason_298032" 582 "WakeupReason_322113" 581 "WakeupReason_320145" 580 "WakeupReason_841275" 579 "WakeupReason_839787" 578 "WakeupReason_839181" 577 "WakeupReason_714677" 576 "WakeupReason_840035" 566 "WakeupReason_839458" 565 "WakeupReason_837760" 564 "WakeupReason_702903" 563 "WakeupReason_837962" 562 "WakeupReason_703140" 561 "WakeupReason_837833" 560 "WakeupReason_839705" 559 "WakeupReason_839473" 558 "WakeupReason_838116" 557 "WakeupReason_717832" 556 "WakeupReason_714697" 555 "WakeupReason_714799" 554 "WakeupReason_714806" 553 "WakeupReason_709196" 552 "WakeupReason_710893" 551 "WakeupReason_708964" 550 "WakeupReason_715529" 549 "WakeupReason_714265" 548 "WakeupReason_714172" 547 "WakeupReason_713799" 546 "WakeupReason_706194" 545 "WakeupReason_713568" 544 "WakeupReason_710807" 543 "WakeupReason_714679" 542 "WakeupReason_714678" 541 "WakeupReason_715842" 540 "WakeupReason_714030" 539 "WakeupReason_710922" 538 "WakeupReason_716243" 537 "WakeupReason_713786" 536 "WakeupReason_714675" 535 "WakeupReason_702478" 534 "WakeupReason_713752" 533 "WakeupReasons_700530" 532 "WakeupReasons_698631" 531 "WakeupReasons_702452" 530 "WakeupReasons_700565" 529 "WakeupReasons_702402" 528 "WakeupReasons_702439" 527 "WakeupReasons_702448" 526 "WakeupReasons_701872" 525 "WakeupReasons_699114" 524 "WakeupReasons_702240" 523 "WakeupReasons_701270" 522 "WakeupReasons_533751" 521 "WakeupReasons_698581" 520 "WakeupReasons_698130" 519 "WakeupReasons_700130" 518 "WakeupReasons_699921" 517 "WakeupReasons_699919" 516 "WakeupReasons_700486" 515 "WakeupReasons_700782" 514 "WakeupReasons_696971" 513 "WakeupReasons_700692" 512 "WakeupReasons_698385" 511 "WakeupReasons_699922" 510 "WakeupReasons_697967" 509 "WakeupReasons_700684" 508 "WakeupReasons_644379" 507 "WakeupReasons_336435" 506 "WakeupReasons_683263" 505 "WakeupReasons_700554" 504 "WakeupReasons_691992" 503 "WakeupReasons_698129" 502 "WakeupReasons_696850" 501 "WakeupReasons_702088" 500 "WakeupReasons_696612" 499 "WakeupReasons_691994" 498 "WakeupReasons_700483" 497 "WakeupReasons_702204" 496 "WakeupReasons_700603" 495 "WakeupReasons_700215" 494 "WakeupReasons_701509" 493 "WakeupReasons_701508" 492 "WakeupReasons_700484" 491 "WakeupReasons_217907" 490 "WakeupReasons_194966" 489 "WakeupReasons_702174" 488 "WakeupReasons_697145" 487 "WakeupReasons_296931" 486 "WakeupReasons_700687" 485 "WakeupReasons_700686" 484 "WakeupReasons_698409" 483 "WakeupReasons_533750" 482 "WakeupReasons_700467" 481 "WakeupReasons_687404" 480 "WakeupReasons_681813" 479 "WakeupReasons_698288" 478 "WakeupReasons_698660" 477 "WakeupReasons_691993" 476 "WakeupReasons_700485" 475 "WakeupReasons_700425" 474 "WakeupReasons_702197" 473 "WakeupReasons_637992" 472 "WakeupReasons_698488" 471 "WakeupReasons_691991" 470 "WakeupReasons_692547" 469 "WakeupReasons_693914" 468 "WakeupReasons_693024" 467 "WakeupReasons_693005" 466 "WakeupReasons_667949" 465 "WakeupReasons_686281" 464 "WakeupReasons_680764" 463 "WakeupReasons_512384" 462 "WakeupReasons_692019" 461 "WakeupReasons_533850" 460 "WakeupReasons_533849" 459 "WakeupReasons_667188" 458 "WakeupReasons_514652" 457 "WakeupReasons_514651" 456 "WakeupReasons_112024" 455 "WakeupReasons_300690" 454 "WakeupReasons_299532" 453 "WakeupReasons_299531" 452 "WakeupReasons_299120" 451 "WakeupReasons_273516" 450 "WakeupReasons_265694" 449 "WakeupReasons_692439" 448 "WakeupReasons_354831" 447 "WakeupReasons_680765" 446 "WakeupReasons_45895" 445 "WakeupReasons_644275" 444 "WakeupReasons_351189" 443 "WakeupReasons_226570" 442 "WakeupReasons_654489" 441 "WakeupReasons_110181" 440 "WakeupReasons_226569" 439 "WakeupReasons_45896" 438 "WakeupReasons_112031" 437 "WakeupReasons_110173" 436 "WakeupReasons_677781" 435 "WakeupReasons_690939" 434 "WakeupReasons_354809" 433 "WakeupReasons_692022" 432 "WakeupReasons_690593" 431 "WakeupReasons_226571" 430 "WakeupReasons_675594" 429 "WakeupReasons_226565" 428 "WakeupReasons_692020" 427 "WakeupReasons_112035" 426 "WakeupReasons_112027" 425 "WakeupReasons_354672" 424 "WakeupReasons_168967" 423 "WakeupReasons_354674" 422 "WakeupReasons_168968" 421 "WakeupReasons_641483" 420 "WakeupReasons_641482" 419 "WakeupReasons_265698" 418 "WakeupReasons_265699" 417 "WakeupReasons_360491" 416 "WakeupReasons_357498" 415 "WakeupReasons_170290" 414 "WakeupReasons_690385" 413 "WakeupReasons_692021" 412 "WakeupReasons_91254" 411 "WakeupReasons_346654" 410 "WakeupReasons_200637" 409 "WakeupReasons_170285" 408 "WakeupReasons_265678" 407 "WakeupReasons_683934" 406 "WakeupReasons_680763" 405 "WakeupReasons_682074" 404 "WakeupReasons_682154" 403 "WakeupReasons_682152" 402 "WakeupReasons_682155" 401 "WakeupReasons_682153" 400 "WakeupReasons_682078" 399 "WakeupReasons_682076" 398 "WakeupReasons_682077" 397 "WakeupReasons_676285" 396 "WakeupReasons_681023" 395 "WakeupReasons_682023" 394 "WakeupReasons_681789" 393 "WakeupReasons_682688" 392 "WakeupReasons_682037" 391 "WakeupReasons_682032" 390 "WakeupReasons_681915" 389 "WakeupReasons_674839" 388 "WakeupReasons_682034" 387 "WakeupReasons_681711" 386 "WakeupReasons_681031" 385 "WakeupReasons_681134" 384 "WakeupReasons_670462" 383 "WakeupReasons_681028" 382 "WakeupReasons_680975" 381 "WakeupReasons_680974" 380 "WakeupReasons_668523" 379 "WakeupReasons_669822" 378 "WakeupReasons_680712" 377 "WakeupReasons_671005" 376 "WakeupReasons_177214" 375 "WakeupReasons_45655" 374 "WakeupReasons_667872" 373 "WakeupReasons_264964" 372 "WakeupReasons_262871" 371 "WakeupReasons_264691" 370 "WakeupReasons_297056" 369 "WakeupReasons_233755" 368 "WakeupReasons_145161" 367 "WakeupReasons_667842" 366 "WakeupReasons_46020" 365 "WakeupReasons_667874" 364 "WakeupReasons_667981" 363 "WakeupReasons_224211" 362 "WakeupReasons_45902" 361 "WakeupReasons_329457" 360 "WakeupReasons_88458" 359 "WakeupReasons_45900" 358 "WakeupReasons_83199" 357 "WakeupReasons_532933" 356 "WakeupReasons_532932" 355 "WakeupReasons_670942" 354 "WakeupReasons_305818" 353 "WakeupReasons_75103" 352 "WakeupReasons_667987" 351 "WakeupReasons_667983" 350 "WakeupReasons_675745" 349 "WakeupReasons_356598" 348 "WakeupReasons_128671" 347 "WakeupReasons_69216" 346 "WakeupReasons_264697" 345 "WakeupReasons_264943" 344 "WakeupReasons_197644" 343 "WakeupReasons_675564" 342 "WakeupReasons_657120" 341 "WakeupReasons_265745" 340 "WakeupReasons_657121" 339 "WakeupReasons_667982" 338 "WakeupReasons_674223" 337 "WakeupReasons_127926" 336 "WakeupReasons_127924" 335 "WakeupReasons_262872" 334 "WakeupReasons_45848" 333 "WakeupReasons_45847" 332 "WakeupReasons_45846" 331 "WakeupReasons_667869" 330 "WakeupReasons_45890" 329 "WakeupReasons_45888" 328 "WakeupReasons_670962" 327 "WakeupReasons_667973" 326 "WakeupReasons_45877" 325 "WakeupReasons_667980" 324 "WakeupReasons_45876" 323 "WakeupReasons_45871" 322 "WakeupReasons_45875" 321 "WakeupReasons_45872" 320 "WakeupReasons_45870" 319 "WakeupReasons_45869" 318 "WakeupReasons_80608" 317 "WakeupReasons_45898" 316 "WakeupReasons_45897" 315 "WakeupReasons_69679" 314 "WakeupReasons_69678" 313 "WakeupReasons_45887" 312 "WakeupReasons_263473" 311 "WakeupReasons_265131" 310 "WakeupReasons_268983" 309 "WakeupReasons_139075" 308 "WakeupReasons_200090" 307 "WakeupReasons_199714" 306 "WakeupReasons_80609" 305 "WakeupReasons_106669" 304 "WakeupReasons_675742" 303 "WakeupReasons_46017" 302 "WakeupReasons_670354" 301 "WakeupReasons_667985" 300 "WakeupReasons_670966" 299 "WakeupReasons_667871" 298 "WakeupReasons_193474" 297 "WakeupReasons_113348" 296 "WakeupReasons_532556" 295 "WakeupReasons_532555" 294 "WakeupReasons_667988" 293 "WakeupReasons_182918" 292 "WakeupReasons_311279" 291 "WakeupReasons_667848" 290 "WakeupReasons_667850" 289 "WakeupReasons_668393" 288 "WakeupReasons_668395" 287 "WakeupReasons_670753" 286 "WakeupReasons_667922" 285 "WakeupReasons_669447" 284 "WakeupReasons_670928" 283 "WakeupReasons_669465" 282 "WakeupReasons_676265" 281 "WakeupReasons_667947" 280 "WakeupReasons_667879" 279 "WakeupReasons_675837" 278 "WakeupReasons_675494" 277 "WakeupReasons_674958" 276 "WakeupReasons_675064" 275 "WakeupReasons_674953" 274 "WakeupReasons_658188" 273 "WakeupReasons_337991" 272 "WakeupReasons_197653" 271 "WakeupReasons_269140" 270 "WakeupReasons_312881" 269 "WakeupReasons_215560" 268 "WakeupReasons_269034" 267 "WakeupReasons_4471" 266 "WakeupReasons_185490" 265 "WakeupReasons_185457" 264 "WakeupReasons_198452" 263 "WakeupReasons_200683" 262 "WakeupReasons_358832" 261 "WakeupReasons_NMPDUReceived" 260 "WakeupReasons_670345" 259 "WakeupReasons_109467" 258 "WakeupReasons_109466" 257 "WakeupReasons_636801" 256 "WakeupReasons_45849" 255 "WakeupReasons_45850" 254 "WakeupReasons_45851" 253 "WakeupReasons_45852" 252 "WakeupReasons_45854" 251 "WakeupReasons_45853" 250 "WakeupReasons_45856" 249 "WakeupReasons_533872" 248 "WakeupReasons_516327" 247 "WakeupReasons_359559" 246 "WakeupReasons_241902" 245 "WakeupReasons_533372" 244 "WakeupReasons_533371" 243 "WakeupReasons_533370" 242 "WakeupReasons_315981" 241 "WakeupReasons_45858" 240 "WakeupReasons_668529" 239 "WakeupReasons_670087" 238 "WakeupReasons_668531" 237 "WakeupReasons_223920" 236 "WakeupReasons_176748" 235 "WakeupReasons_146470" 234 "WakeupReasons_112799" 233 "WakeupReasons_95949" 232 "WakeupReasons_156440" 231 "WakeupReasons_166267" 230 "WakeupReasons_101727" 229 "WakeupReasons_101728" 228 "WakeupReasons_101725" 227 "WakeupReasons_101706" 226 "WakeupReasons_659350" 225 "WakeupReasons_667820" 224 "WakeupReasons_331194" 223 "WakeupReasons_652546" 222 "WakeupReasons_224553" 221 "WakeupReasons_224552" 220 "WakeupReasons_110885" 219 "WakeupReasons_667953" 218 "WakeupReasons_667962" 217 "WakeupReasons_224550" 216 "WakeupReasons_197665" 215 "WakeupReasons_225961" 214 "WakeupReasons_198433" 213 "WakeupReasons_526438" 212 "WakeupReasons_316796" 211 "WakeupReasons_335068" 210 "WakeupReasons_535214" 209 "WakeupReasons_264726" 208 "WakeupReasons_360542" 207 "WakeupReasons_531743" 206 "WakeupReasons_226967" 205 "WakeupReasons_318382" 204 "WakeupReasons_199159" 203 "WakeupReasons_223715" 202 "WakeupReasons_643973" 201 "WakeupReasons_319401" 200 "WakeupReasons_264712" 199 "WakeupReasons_526426" 198 "WakeupReasons_533050" 197 "WakeupReasons_265937" 196 "WakeupReasons_108834" 195 "WakeupReasons_636556" 194 "WakeupReasons_655340" 193 "WakeupReasons_320895" 192 "WakeupReasons_321077" 191 "WakeupReasons_321323" 190 "WakeupReasons_321319" 189 "WakeupReasons_321057" 188 "WakeupReasons_359187" 187 "WakeupReasons_321317" 186 "WakeupReasons_355214" 185 "WakeupReasons_652361" 184 "WakeupReasons_192030" 183 "WakeupReasons_534145" 182 "WakeupReasons_526445" 181 "WakeupReasons_360299" 180 "WakeupReasons_525705" 179 "WakeupReasons_534077" 178 "WakeupReasons_359211" 177 "WakeupReasons_300681" 176 "WakeupReasons_198484" 175 "WakeupReasons_356549" 174 "WakeupReasons_360543" 173 "WakeupReasons_318342" 172 "WakeupReasons_299547" 171 "WakeupReasons_646109" 170 "WakeupReasons_645753" 169 "WakeupReasons_514502" 168 "WakeupReasons_515804" 167 "WakeupReasons_298808" 166 "WakeupReasons_265330" 165 "WakeupReasons_265328" 164 "WakeupReasons_265305" 163 "WakeupReasons_361279" 162 "WakeupReasons_361272" 161 "WakeupReasons_160596" 160 "WakeupReasons_197648" 159 "WakeupReasons_658603" 158 "WakeupReasons_322857" 157 "WakeupReasons_108810" 156 "WakeupReasons_179103" 155 "WakeupReasons_321845" 154 "WakeupReasons_340667" 153 "WakeupReasons_299117" 152 "WakeupReasons_514503" 151 "WakeupReasons_532007" 150 "WakeupReasons_337565" 149 "WakeupReasons_320631" 148 "WakeupReasons_354791" 147 "WakeupReasons_317616" 146 "WakeupReasons_644550" 145 "WakeupReasons_265232" 144 "WakeupReasons_514545" 143 "WakeupReasons_526429" 142 "WakeupReasons_265569" 141 "WakeupReasons_108841" 140 "WakeupReasons_160602" 139 "WakeupReasons_160597" 138 "WakeupReasons_264958" 137 "WakeupReasons_300682" 136 "WakeupReasons_224634" 135 "WakeupReasons_224617" 134 "WakeupReasons_220322" 133 "WakeupReasons_300427" 132 "WakeupReasons_269156" 131 "WakeupReasons_145462" 130 "WakeupReasons_145454" 129 "WakeupReasons_145419" 128 "WakeupReasons_145288" 127 "WakeupReasons_145373" 126 "WakeupReasons_145385" 125 "WakeupReasons_145362" 124 "WakeupReasons_145399" 123 "WakeupReasons_145388" 122 "WakeupReasons_145330" 121 "WakeupReasons_152774" 120 "WakeupReasons_145319" 119 "WakeupReasons_145311" 118 "WakeupReasons_106774" 117 "WakeupReasons_533044" 116 "WakeupReasons_636692" 115 "WakeupReasons_355409" 114 "WakeupReasons_133749" 113 "WakeupReasons_156412" 112 "WakeupReasons_320287" 111 "WakeupReasons_201348" 110 "WakeupReasons_264962" 109 "WakeupReasons_169884" 108 "WakeupReasons_45867" 107 "WakeupReasons_45866" 106 "WakeupReasons_659549" 105 "WakeupReasons_45864" 104 "WakeupReasons_201815" 103 "WakeupReasons_224831" 102 "WakeupReasons_222553" 101 "WakeupReasons_140678" 100 "WakeupReasons_169945" 99 "WakeupReasons_95444" 98 "WakeupReasons_145688" 97 "WakeupReasons_356190" 96 "WakeupReasons_264934" 95 "WakeupReasons_264932" 94 "WakeupReasons_152786" 93 "WakeupReasons_144970" 92 "WakeupReasons_186489" 91 "WakeupReasons_144897" 90 "WakeupReasons_199172" 89 "WakeupReasons_145707" 88 "WakeupReasons_152237" 87 "WakeupReasons_67182" 86 "WakeupReasons_338820" 85 "WakeupReasons_634710" 84 "WakeupReasons_109387" 83 "WakeupReasons_320126" 82 "WakeupReasons_109367" 81 "WakeupReasons_315364" 80 "WakeupReasons_297868" 79 "WakeupReasons_645810" 78 "WakeupReasons_634696" 77 "WakeupReasons_138997" 76 "WakeupReasons_360006" 75 "WakeupReasons_224061" 74 "WakeupReasons_68481" 73 "WakeupReasons_109364" 72 "WakeupReasons_68644" 71 "WakeupReasons_224065" 70 "WakeupReasons_119273" 69 "WakeupReasons_109382" 68 "WakeupReasons_360008" 67 "WakeupReasons_68676" 66 "WakeupReasons_645094" 65 "WakeupReasons_361509" 64 "WakeupReasons_361505" 63 "WakeupReasons_360904" 62 "WakeupReasons_355601" 61 "WakeupReasons_320277" 60 "WakeupReasons_319422" 59 "WakeupReasons_320282" 58 "WakeupReasons_169894" 57 "WakeupReasons_266860" 56 "WakeupReasons_45656" 55 "WakeupReasons_21997" 54 "WakeupReasons_225696" 53 "WakeupReasons_200156" 52 "WakeupReasons_161066" 51 "WakeupReasons_185670" 50 "WakeupReasons_197826" 49 "WakeupReasons_176921" 48 "WakeupReasons_108776" 47 "WakeupReasons_265333" 46 "WakeupReasons_100281" 45 "WakeupReasons_100278" 44 "WakeupReasons_100300" 43 "WakeupReasons_100275" 42 "WakeupReasons_100298" 41 "WakeupReasons_319139" 40 "WakeupReasons_170807" 39 "WakeupReasons_200937" 38 "WakeupReasons_182033" 37 "WakeupReasons_191050" 36 "WakeupReasons_264876" 35 "WakeupReasons_197642" 34 "WakeupReasons_170865" 33 "WakeupReasons_168966" 32 "WakeupReasons_667948" 31 "WakeupReasons_169655" 30 "WakeupReasons_667945" 29 "WakeupReasons_74188" 28 "WakeupReasons_321583" 27 "WakeupReasons_88125" 26 "WakeupReasons_88123" 25 "WakeupReasons_91253" 24 "WakeupReasons_21973" 23 "WakeupReasons_140084" 22 "WakeupReasons_45657" 21 "WakeupReasons_45659" 20 "WakeupReasons_22100" 19 "WakeupReasons_22013" 18 "WakeupReasons_22005" 17 "WakeupReasons_45794" 16 "WakeupReasons_45793" 15 "WakeupReasons_21901" 14 "WakeupReasons_658500" 13 "WakeupReasons_269739" 12 "WakeupReasons_269735" 11 "WakeupReasons_269740" 10 "WakeupReasons_22060" 9 "WakeupReasons_49446" 8 "WakeupReasons_22058" 7 "WakeupReasons_45654" 6 "WakeupReasons_264933" 5 "WakeupReasons_197643" 4 "WakeupReasons_168965" 3 "WakeupReasons_667951" 2 "WakeupReasons_169654" 1 "WakeupReasons_667950" 0 "WakeupReasons_0";
VAL_ 1350 VFCVectorSRSVFCid0 1 "VFCOnOff_On" 0 "VFCOnOff_Off";
VAL_ 1350 VFCVectorSRSVFCid1 1 "VFCOnOff_On" 0 "VFCOnOff_Off";
VAL_ 1350 VFCVectorSRSVFCid10 1 "VFCOnOff_On" 0 "VFCOnOff_Off";
VAL_ 1350 VFCVectorSRSVFCid11 1 "VFCOnOff_On" 0 "VFCOnOff_Off";
VAL_ 1350 VFCVectorSRSVFCid12 1 "VFCOnOff_On" 0 "VFCOnOff_Off";
VAL_ 1350 VFCVectorSRSVFCid13 1 "VFCOnOff_On" 0 "VFCOnOff_Off";
VAL_ 1350 VFCVectorSRSVFCid14 1 "VFCOnOff_On" 0 "VFCOnOff_Off";
VAL_ 1350 VFCVectorSRSVFCid15 1 "VFCOnOff_On" 0 "VFCOnOff_Off";
VAL_ 1350 VFCVectorSRSVFCid16 1 "VFCOnOff_On" 0 "VFCOnOff_Off";
VAL_ 1350 VFCVectorSRSVFCid17 1 "VFCOnOff_On" 0 "VFCOnOff_Off";
VAL_ 1350 VFCVectorSRSVFCid18 1 "VFCOnOff_On" 0 "VFCOnOff_Off";
VAL_ 1350 VFCVectorSRSVFCid19 1 "VFCOnOff_On" 0 "VFCOnOff_Off";
VAL_ 1350 VFCVectorSRSVFCid2 1 "VFCOnOff_On" 0 "VFCOnOff_Off";
VAL_ 1350 VFCVectorSRSVFCid20 1 "VFCOnOff_On" 0 "VFCOnOff_Off";
VAL_ 1350 VFCVectorSRSVFCid21 1 "VFCOnOff_On" 0 "VFCOnOff_Off";
VAL_ 1350 VFCVectorSRSVFCid22 1 "VFCOnOff_On" 0 "VFCOnOff_Off";
VAL_ 1350 VFCVectorSRSVFCid23 1 "VFCOnOff_On" 0 "VFCOnOff_Off";
VAL_ 1350 VFCVectorSRSVFCid24 1 "VFCOnOff_On" 0 "VFCOnOff_Off";
VAL_ 1350 VFCVectorSRSVFCid25 1 "VFCOnOff_On" 0 "VFCOnOff_Off";
VAL_ 1350 VFCVectorSRSVFCid26 1 "VFCOnOff_On" 0 "VFCOnOff_Off";
VAL_ 1350 VFCVectorSRSVFCid27 1 "VFCOnOff_On" 0 "VFCOnOff_Off";
VAL_ 1350 VFCVectorSRSVFCid28 1 "VFCOnOff_On" 0 "VFCOnOff_Off";
VAL_ 1350 VFCVectorSRSVFCid29 1 "VFCOnOff_On" 0 "VFCOnOff_Off";
VAL_ 1350 VFCVectorSRSVFCid3 1 "VFCOnOff_On" 0 "VFCOnOff_Off";
VAL_ 1350 VFCVectorSRSVFCid30 1 "VFCOnOff_On" 0 "VFCOnOff_Off";
VAL_ 1350 VFCVectorSRSVFCid31 1 "VFCOnOff_On" 0 "VFCOnOff_Off";
VAL_ 1350 VFCVectorSRSVFCid32 1 "VFCOnOff_On" 0 "VFCOnOff_Off";
VAL_ 1350 VFCVectorSRSVFCid33 1 "VFCOnOff_On" 0 "VFCOnOff_Off";
VAL_ 1350 VFCVectorSRSVFCid34 1 "VFCOnOff_On" 0 "VFCOnOff_Off";
VAL_ 1350 VFCVectorSRSVFCid35 1 "VFCOnOff_On" 0 "VFCOnOff_Off";
VAL_ 1350 VFCVectorSRSVFCid36 1 "VFCOnOff_On" 0 "VFCOnOff_Off";
VAL_ 1350 VFCVectorSRSVFCid37 1 "VFCOnOff_On" 0 "VFCOnOff_Off";
VAL_ 1350 VFCVectorSRSVFCid38 1 "VFCOnOff_On" 0 "VFCOnOff_Off";
VAL_ 1350 VFCVectorSRSVFCid39 1 "VFCOnOff_On" 0 "VFCOnOff_Off";
VAL_ 1350 VFCVectorSRSVFCid4 1 "VFCOnOff_On" 0 "VFCOnOff_Off";
VAL_ 1350 VFCVectorSRSVFCid40 1 "VFCOnOff_On" 0 "VFCOnOff_Off";
VAL_ 1350 VFCVectorSRSVFCid41 1 "VFCOnOff_On" 0 "VFCOnOff_Off";
VAL_ 1350 VFCVectorSRSVFCid42 1 "VFCOnOff_On" 0 "VFCOnOff_Off";
VAL_ 1350 VFCVectorSRSVFCid43 1 "VFCOnOff_On" 0 "VFCOnOff_Off";
VAL_ 1350 VFCVectorSRSVFCid44 1 "VFCOnOff_On" 0 "VFCOnOff_Off";
VAL_ 1350 VFCVectorSRSVFCid45 1 "VFCOnOff_On" 0 "VFCOnOff_Off";
VAL_ 1350 VFCVectorSRSVFCid46 1 "VFCOnOff_On" 0 "VFCOnOff_Off";
VAL_ 1350 VFCVectorSRSVFCid47 1 "VFCOnOff_On" 0 "VFCOnOff_Off";
VAL_ 1350 VFCVectorSRSVFCid48 1 "VFCOnOff_On" 0 "VFCOnOff_Off";
VAL_ 1350 VFCVectorSRSVFCid49 1 "VFCOnOff_On" 0 "VFCOnOff_Off";
VAL_ 1350 VFCVectorSRSVFCid5 1 "VFCOnOff_On" 0 "VFCOnOff_Off";
VAL_ 1350 VFCVectorSRSVFCid50 1 "VFCOnOff_On" 0 "VFCOnOff_Off";
VAL_ 1350 VFCVectorSRSVFCid51 1 "VFCOnOff_On" 0 "VFCOnOff_Off";
VAL_ 1350 VFCVectorSRSVFCid52 1 "VFCOnOff_On" 0 "VFCOnOff_Off";
VAL_ 1350 VFCVectorSRSVFCid53 1 "VFCOnOff_On" 0 "VFCOnOff_Off";
VAL_ 1350 VFCVectorSRSVFCid54 1 "VFCOnOff_On" 0 "VFCOnOff_Off";
VAL_ 1350 VFCVectorSRSVFCid55 1 "VFCOnOff_On" 0 "VFCOnOff_Off";
VAL_ 1350 VFCVectorSRSVFCid56 1 "VFCOnOff_On" 0 "VFCOnOff_Off";
VAL_ 1350 VFCVectorSRSVFCid57 1 "VFCOnOff_On" 0 "VFCOnOff_Off";
VAL_ 1350 VFCVectorSRSVFCid58 1 "VFCOnOff_On" 0 "VFCOnOff_Off";
VAL_ 1350 VFCVectorSRSVFCid59 1 "VFCOnOff_On" 0 "VFCOnOff_Off";
VAL_ 1350 VFCVectorSRSVFCid6 1 "VFCOnOff_On" 0 "VFCOnOff_Off";
VAL_ 1350 VFCVectorSRSVFCid60 1 "VFCOnOff_On" 0 "VFCOnOff_Off";
VAL_ 1350 VFCVectorSRSVFCid61 1 "VFCOnOff_On" 0 "VFCOnOff_Off";
VAL_ 1350 VFCVectorSRSVFCid7 1 "VFCOnOff_On" 0 "VFCOnOff_Off";
VAL_ 1350 VFCVectorSRSVFCid8 1 "VFCOnOff_On" 0 "VFCOnOff_Off";
VAL_ 1350 VFCVectorSRSVFCid9 1 "VFCOnOff_On" 0 "VFCOnOff_Off";
VAL_ 448 AirSuspFltSts 7 "AirSuspFltSts_Reserve2" 6 "AirSuspFltSts_Reserve1" 5 "AirSuspFltSts_Vlv_Failr" 4 "AirSuspFltSts_HumSnsr_Failr" 3 "AirSuspFltSts_TemSnsr_Failr" 2 "AirSuspFltSts_PreSnsr_Failr" 1 "AirSuspFltSts_SysFailr" 0 "AirSuspFltSts_No_Failr";
VAL_ 448 SuspStfnVlvCtrlStsFbFL 3 "VlvCtrlSts_C1AndC2AndC3" 2 "VlvCtrlSts_C1AndC3" 1 "VlvCtrlSts_C1AndC2" 0 "VlvCtrlSts_Chmb1";
VAL_ 448 SuspStfnVlvCtrlStsFbFR 3 "VlvCtrlSts_C1AndC2AndC3" 2 "VlvCtrlSts_C1AndC3" 1 "VlvCtrlSts_C1AndC2" 0 "VlvCtrlSts_Chmb1";
VAL_ 448 SuspStfnVlvCtrlStsFbRL 3 "VlvCtrlSts_C1AndC2AndC3" 2 "VlvCtrlSts_C1AndC3" 1 "VlvCtrlSts_C1AndC2" 0 "VlvCtrlSts_Chmb1";
VAL_ 448 SuspStfnVlvCtrlStsFbRR 3 "VlvCtrlSts_C1AndC2AndC3" 2 "VlvCtrlSts_C1AndC3" 1 "VlvCtrlSts_C1AndC2" 0 "VlvCtrlSts_Chmb1";
VAL_ 528 SUMMissingSlaveSignal 1 "Boolean_TRUE" 0 "Boolean_FALSE";
VAL_ 1317 WakeUpReasonsforSUM 741 "WakeupReasons_871868" 740 "WakeupReasons_871957" 739 "WakeupReasons_871729" 738 "WakeupReasons_700779" 737 "WakeupReasons_839414" 736 "WakeupReasons_675025" 735 "WakeupReasons_671146" 734 "WakeupReasons_1031929" 733 "WakeupReasons_1033548" 732 "WakeupReasons_1033537" 731 "WakeupReasons_1033479" 730 "WakeupReasons_1030765" 729 "WakeupReasons_1028674" 728 "WakeupReasons_1033567" 727 "WakeupReasons_1033543" 726 "WakeupReasons_1033549" 725 "WakeupReasons_1033554" 724 "WakeupReasons_1033563" 723 "WakeupReasons_1033558" 722 "WakeupReasons_1029384" 721 "WakeupReasons_1029383" 720 "WakeupReasons_1029382" 719 "WakeupReasons_1032619" 718 "WakeupReasons_1024928" 717 "WakeupReasons_1033547" 716 "WakeupReasons_1033541" 715 "WakeupReasons_1033562" 714 "WakeupReasons_1033564" 713 "WakeupReasons_986765" 712 "WakeupReasons_1026103" 711 "WakeupReasons_1030764" 710 "WakeupReasons_1030941" 709 "WakeupReasons_1033556" 708 "WakeupReasons_1033539" 707 "WakeupReasons_1033534" 706 "WakeupReasons_1032477" 705 "WakeupReasons_1031280" 704 "WakeupReasons_1033542" 703 "WakeupReasons_1033632" 702 "WakeupReasons_1033533" 701 "WakeupReasons_1029166" 700 "WakeupReasons_1033538" 699 "WakeupReasons_1031789" 698 "WakeupReasons_1033552" 697 "WakeupReasons_1033553" 696 "WakeupReasons_1033559" 695 "WakeupReasons_1033544" 694 "WakeupReasons_1033561" 693 "WakeupReasons_1031029" 692 "WakeupReasons_1030360" 691 "WakeupReasons_1030761" 690 "WakeupReasons_1033550" 689 "WakeupReasons_1032579" 688 "WakeupReasons_1033557" 687 "WakeupReasons_1031936" 686 "WakeupReasons_1033566" 685 "WakeupReasons_1033551" 684 "WakeupReasons_1033540" 683 "WakeupReasons_1030760" 682 "WakeupReasons_1029735" 681 "WakeupReasons_1033565" 680 "WakeupReasons_852370" 679 "WakeupReasons_1033555" 678 "WakeupReasons_1033546" 677 "WakeupReasons_1032743" 676 "WakeupReasons_1032791" 675 "WakeupReasons_1033569" 674 "WakeupReasons_1031030" 673 "WakeupReasons_1028778" 672 "WakeupReasons_1030759" 671 "WakeupReasons_1031907" 670 "WakeupReasons_1033560" 669 "WakeupReasons_1031288" 668 "WakeupReasons_1030302" 667 "WakeupReasons_1031765" 666 "WakeupReasons_1031990" 665 "WakeupReasons_1028729" 664 "WakeupReasons_1030362" 663 "WakeupReasons_1030361" 662 "WakeupReasons_1030297" 661 "WakeupReasons_1030293" 660 "WakeupReasons_527345" 659 "WakeupReasons_988154" 658 "WakeupReasons_533580" 657 "WakeupReasons_533581" 656 "WakeupReasons_533576" 655 "WakeupReasons_1030255" 654 "WakeupReasons_527348" 653 "WakeupReasons_533578" 652 "WakeupReasons_527347" 651 "WakeupReasons_527346" 650 "WakeupReasons_ADCUReserve" 649 "WakeupReasons_885767" 648 "WakeupReasons_909025" 647 "WakeupReasons_909026" 646 "WakeupReasons_858177" 645 "WakeupReasons_858169" 644 "WakeupReasons_858152" 643 "WakeupReasons_973575" 642 "WakeupReason_973574" 641 "WakeupReason_987405" 640 "WakeupReason_858187" 639 "WakeupReason_988826" 638 "WakeupReason_988821" 637 "WakeupReason_987485" 636 "WakeupReason_908128" 635 "WakeupReason_908115" 634 "WakeupReason_856234" 633 "WakeupReason_856224" 632 "WakeupReason_858189" 631 "WakeupReason_858188" 630 "WakeupReason_872056" 629 "WakeupReason_870276" 628 "WakeupReason_858191" 627 "WakeupReason_847054" 626 "WakeupReason_856465" 625 "WakeupReason_872253" 624 "WakeupReason_855003" 623 "WakeupReason_855002" 622 "WakeupReason_854947" 621 "WakeupReason_855134" 620 "WakeupReason_854839" 619 "WakeupReason_854999" 618 "WakeupReason_855029" 617 "WakeupReason_714340" 616 "WakeupReason_852947" 615 "WakeupReason_852944" 614 "WakeupReason_852646" 613 "WakeupReason_852537" 612 "WakeupReason_852388" 611 "WakeupReason_852385" 610 "WakeupReason_852298" 609 "WakeupReason_852273" 608 "WakeupReason_852248" 607 "WakeupReason_852219" 606 "WakeupReason_852218" 605 "WakeupReason_852215" 604 "WakeupReason_852200" 603 "WakeupReason_852195" 602 "WakeupReason_852194" 601 "WakeupReason_852184" 600 "WakeupReason_852180" 599 "WakeupReason_852050" 598 "WakeupReason_852010" 597 "WakeupReason_851743" 596 "WakeupReason_851482" 595 "WakeupReason_702420" 594 "WakeupReason_667533" 593 "WakeupReason_645735" 592 "WakeupReason_362462" 591 "WakeupReason_361474" 590 "WakeupReason_361441" 589 "WakeupReason_846002" 588 "WakeupReason_845930" 587 "WakeupReason_842273" 586 "WakeupReason_846372" 585 "WakeupReason_675489" 584 "WakeupReason_675452" 583 "WakeupReason_298032" 582 "WakeupReason_322113" 581 "WakeupReason_320145" 580 "WakeupReason_841275" 579 "WakeupReason_839787" 578 "WakeupReason_839181" 577 "WakeupReason_714677" 576 "WakeupReason_840035" 566 "WakeupReason_839458" 565 "WakeupReason_837760" 564 "WakeupReason_702903" 563 "WakeupReason_837962" 562 "WakeupReason_703140" 561 "WakeupReason_837833" 560 "WakeupReason_839705" 559 "WakeupReason_839473" 558 "WakeupReason_838116" 557 "WakeupReason_717832" 556 "WakeupReason_714697" 555 "WakeupReason_714799" 554 "WakeupReason_714806" 553 "WakeupReason_709196" 552 "WakeupReason_710893" 551 "WakeupReason_708964" 550 "WakeupReason_715529" 549 "WakeupReason_714265" 548 "WakeupReason_714172" 547 "WakeupReason_713799" 546 "WakeupReason_706194" 545 "WakeupReason_713568" 544 "WakeupReason_710807" 543 "WakeupReason_714679" 542 "WakeupReason_714678" 541 "WakeupReason_715842" 540 "WakeupReason_714030" 539 "WakeupReason_710922" 538 "WakeupReason_716243" 537 "WakeupReason_713786" 536 "WakeupReason_714675" 535 "WakeupReason_702478" 534 "WakeupReason_713752" 533 "WakeupReasons_700530" 532 "WakeupReasons_698631" 531 "WakeupReasons_702452" 530 "WakeupReasons_700565" 529 "WakeupReasons_702402" 528 "WakeupReasons_702439" 527 "WakeupReasons_702448" 526 "WakeupReasons_701872" 525 "WakeupReasons_699114" 524 "WakeupReasons_702240" 523 "WakeupReasons_701270" 522 "WakeupReasons_533751" 521 "WakeupReasons_698581" 520 "WakeupReasons_698130" 519 "WakeupReasons_700130" 518 "WakeupReasons_699921" 517 "WakeupReasons_699919" 516 "WakeupReasons_700486" 515 "WakeupReasons_700782" 514 "WakeupReasons_696971" 513 "WakeupReasons_700692" 512 "WakeupReasons_698385" 511 "WakeupReasons_699922" 510 "WakeupReasons_697967" 509 "WakeupReasons_700684" 508 "WakeupReasons_644379" 507 "WakeupReasons_336435" 506 "WakeupReasons_683263" 505 "WakeupReasons_700554" 504 "WakeupReasons_691992" 503 "WakeupReasons_698129" 502 "WakeupReasons_696850" 501 "WakeupReasons_702088" 500 "WakeupReasons_696612" 499 "WakeupReasons_691994" 498 "WakeupReasons_700483" 497 "WakeupReasons_702204" 496 "WakeupReasons_700603" 495 "WakeupReasons_700215" 494 "WakeupReasons_701509" 493 "WakeupReasons_701508" 492 "WakeupReasons_700484" 491 "WakeupReasons_217907" 490 "WakeupReasons_194966" 489 "WakeupReasons_702174" 488 "WakeupReasons_697145" 487 "WakeupReasons_296931" 486 "WakeupReasons_700687" 485 "WakeupReasons_700686" 484 "WakeupReasons_698409" 483 "WakeupReasons_533750" 482 "WakeupReasons_700467" 481 "WakeupReasons_687404" 480 "WakeupReasons_681813" 479 "WakeupReasons_698288" 478 "WakeupReasons_698660" 477 "WakeupReasons_691993" 476 "WakeupReasons_700485" 475 "WakeupReasons_700425" 474 "WakeupReasons_702197" 473 "WakeupReasons_637992" 472 "WakeupReasons_698488" 471 "WakeupReasons_691991" 470 "WakeupReasons_692547" 469 "WakeupReasons_693914" 468 "WakeupReasons_693024" 467 "WakeupReasons_693005" 466 "WakeupReasons_667949" 465 "WakeupReasons_686281" 464 "WakeupReasons_680764" 463 "WakeupReasons_512384" 462 "WakeupReasons_692019" 461 "WakeupReasons_533850" 460 "WakeupReasons_533849" 459 "WakeupReasons_667188" 458 "WakeupReasons_514652" 457 "WakeupReasons_514651" 456 "WakeupReasons_112024" 455 "WakeupReasons_300690" 454 "WakeupReasons_299532" 453 "WakeupReasons_299531" 452 "WakeupReasons_299120" 451 "WakeupReasons_273516" 450 "WakeupReasons_265694" 449 "WakeupReasons_692439" 448 "WakeupReasons_354831" 447 "WakeupReasons_680765" 446 "WakeupReasons_45895" 445 "WakeupReasons_644275" 444 "WakeupReasons_351189" 443 "WakeupReasons_226570" 442 "WakeupReasons_654489" 441 "WakeupReasons_110181" 440 "WakeupReasons_226569" 439 "WakeupReasons_45896" 438 "WakeupReasons_112031" 437 "WakeupReasons_110173" 436 "WakeupReasons_677781" 435 "WakeupReasons_690939" 434 "WakeupReasons_354809" 433 "WakeupReasons_692022" 432 "WakeupReasons_690593" 431 "WakeupReasons_226571" 430 "WakeupReasons_675594" 429 "WakeupReasons_226565" 428 "WakeupReasons_692020" 427 "WakeupReasons_112035" 426 "WakeupReasons_112027" 425 "WakeupReasons_354672" 424 "WakeupReasons_168967" 423 "WakeupReasons_354674" 422 "WakeupReasons_168968" 421 "WakeupReasons_641483" 420 "WakeupReasons_641482" 419 "WakeupReasons_265698" 418 "WakeupReasons_265699" 417 "WakeupReasons_360491" 416 "WakeupReasons_357498" 415 "WakeupReasons_170290" 414 "WakeupReasons_690385" 413 "WakeupReasons_692021" 412 "WakeupReasons_91254" 411 "WakeupReasons_346654" 410 "WakeupReasons_200637" 409 "WakeupReasons_170285" 408 "WakeupReasons_265678" 407 "WakeupReasons_683934" 406 "WakeupReasons_680763" 405 "WakeupReasons_682074" 404 "WakeupReasons_682154" 403 "WakeupReasons_682152" 402 "WakeupReasons_682155" 401 "WakeupReasons_682153" 400 "WakeupReasons_682078" 399 "WakeupReasons_682076" 398 "WakeupReasons_682077" 397 "WakeupReasons_676285" 396 "WakeupReasons_681023" 395 "WakeupReasons_682023" 394 "WakeupReasons_681789" 393 "WakeupReasons_682688" 392 "WakeupReasons_682037" 391 "WakeupReasons_682032" 390 "WakeupReasons_681915" 389 "WakeupReasons_674839" 388 "WakeupReasons_682034" 387 "WakeupReasons_681711" 386 "WakeupReasons_681031" 385 "WakeupReasons_681134" 384 "WakeupReasons_670462" 383 "WakeupReasons_681028" 382 "WakeupReasons_680975" 381 "WakeupReasons_680974" 380 "WakeupReasons_668523" 379 "WakeupReasons_669822" 378 "WakeupReasons_680712" 377 "WakeupReasons_671005" 376 "WakeupReasons_177214" 375 "WakeupReasons_45655" 374 "WakeupReasons_667872" 373 "WakeupReasons_264964" 372 "WakeupReasons_262871" 371 "WakeupReasons_264691" 370 "WakeupReasons_297056" 369 "WakeupReasons_233755" 368 "WakeupReasons_145161" 367 "WakeupReasons_667842" 366 "WakeupReasons_46020" 365 "WakeupReasons_667874" 364 "WakeupReasons_667981" 363 "WakeupReasons_224211" 362 "WakeupReasons_45902" 361 "WakeupReasons_329457" 360 "WakeupReasons_88458" 359 "WakeupReasons_45900" 358 "WakeupReasons_83199" 357 "WakeupReasons_532933" 356 "WakeupReasons_532932" 355 "WakeupReasons_670942" 354 "WakeupReasons_305818" 353 "WakeupReasons_75103" 352 "WakeupReasons_667987" 351 "WakeupReasons_667983" 350 "WakeupReasons_675745" 349 "WakeupReasons_356598" 348 "WakeupReasons_128671" 347 "WakeupReasons_69216" 346 "WakeupReasons_264697" 345 "WakeupReasons_264943" 344 "WakeupReasons_197644" 343 "WakeupReasons_675564" 342 "WakeupReasons_657120" 341 "WakeupReasons_265745" 340 "WakeupReasons_657121" 339 "WakeupReasons_667982" 338 "WakeupReasons_674223" 337 "WakeupReasons_127926" 336 "WakeupReasons_127924" 335 "WakeupReasons_262872" 334 "WakeupReasons_45848" 333 "WakeupReasons_45847" 332 "WakeupReasons_45846" 331 "WakeupReasons_667869" 330 "WakeupReasons_45890" 329 "WakeupReasons_45888" 328 "WakeupReasons_670962" 327 "WakeupReasons_667973" 326 "WakeupReasons_45877" 325 "WakeupReasons_667980" 324 "WakeupReasons_45876" 323 "WakeupReasons_45871" 322 "WakeupReasons_45875" 321 "WakeupReasons_45872" 320 "WakeupReasons_45870" 319 "WakeupReasons_45869" 318 "WakeupReasons_80608" 317 "WakeupReasons_45898" 316 "WakeupReasons_45897" 315 "WakeupReasons_69679" 314 "WakeupReasons_69678" 313 "WakeupReasons_45887" 312 "WakeupReasons_263473" 311 "WakeupReasons_265131" 310 "WakeupReasons_268983" 309 "WakeupReasons_139075" 308 "WakeupReasons_200090" 307 "WakeupReasons_199714" 306 "WakeupReasons_80609" 305 "WakeupReasons_106669" 304 "WakeupReasons_675742" 303 "WakeupReasons_46017" 302 "WakeupReasons_670354" 301 "WakeupReasons_667985" 300 "WakeupReasons_670966" 299 "WakeupReasons_667871" 298 "WakeupReasons_193474" 297 "WakeupReasons_113348" 296 "WakeupReasons_532556" 295 "WakeupReasons_532555" 294 "WakeupReasons_667988" 293 "WakeupReasons_182918" 292 "WakeupReasons_311279" 291 "WakeupReasons_667848" 290 "WakeupReasons_667850" 289 "WakeupReasons_668393" 288 "WakeupReasons_668395" 287 "WakeupReasons_670753" 286 "WakeupReasons_667922" 285 "WakeupReasons_669447" 284 "WakeupReasons_670928" 283 "WakeupReasons_669465" 282 "WakeupReasons_676265" 281 "WakeupReasons_667947" 280 "WakeupReasons_667879" 279 "WakeupReasons_675837" 278 "WakeupReasons_675494" 277 "WakeupReasons_674958" 276 "WakeupReasons_675064" 275 "WakeupReasons_674953" 274 "WakeupReasons_658188" 273 "WakeupReasons_337991" 272 "WakeupReasons_197653" 271 "WakeupReasons_269140" 270 "WakeupReasons_312881" 269 "WakeupReasons_215560" 268 "WakeupReasons_269034" 267 "WakeupReasons_4471" 266 "WakeupReasons_185490" 265 "WakeupReasons_185457" 264 "WakeupReasons_198452" 263 "WakeupReasons_200683" 262 "WakeupReasons_358832" 261 "WakeupReasons_NMPDUReceived" 260 "WakeupReasons_670345" 259 "WakeupReasons_109467" 258 "WakeupReasons_109466" 257 "WakeupReasons_636801" 256 "WakeupReasons_45849" 255 "WakeupReasons_45850" 254 "WakeupReasons_45851" 253 "WakeupReasons_45852" 252 "WakeupReasons_45854" 251 "WakeupReasons_45853" 250 "WakeupReasons_45856" 249 "WakeupReasons_533872" 248 "WakeupReasons_516327" 247 "WakeupReasons_359559" 246 "WakeupReasons_241902" 245 "WakeupReasons_533372" 244 "WakeupReasons_533371" 243 "WakeupReasons_533370" 242 "WakeupReasons_315981" 241 "WakeupReasons_45858" 240 "WakeupReasons_668529" 239 "WakeupReasons_670087" 238 "WakeupReasons_668531" 237 "WakeupReasons_223920" 236 "WakeupReasons_176748" 235 "WakeupReasons_146470" 234 "WakeupReasons_112799" 233 "WakeupReasons_95949" 232 "WakeupReasons_156440" 231 "WakeupReasons_166267" 230 "WakeupReasons_101727" 229 "WakeupReasons_101728" 228 "WakeupReasons_101725" 227 "WakeupReasons_101706" 226 "WakeupReasons_659350" 225 "WakeupReasons_667820" 224 "WakeupReasons_331194" 223 "WakeupReasons_652546" 222 "WakeupReasons_224553" 221 "WakeupReasons_224552" 220 "WakeupReasons_110885" 219 "WakeupReasons_667953" 218 "WakeupReasons_667962" 217 "WakeupReasons_224550" 216 "WakeupReasons_197665" 215 "WakeupReasons_225961" 214 "WakeupReasons_198433" 213 "WakeupReasons_526438" 212 "WakeupReasons_316796" 211 "WakeupReasons_335068" 210 "WakeupReasons_535214" 209 "WakeupReasons_264726" 208 "WakeupReasons_360542" 207 "WakeupReasons_531743" 206 "WakeupReasons_226967" 205 "WakeupReasons_318382" 204 "WakeupReasons_199159" 203 "WakeupReasons_223715" 202 "WakeupReasons_643973" 201 "WakeupReasons_319401" 200 "WakeupReasons_264712" 199 "WakeupReasons_526426" 198 "WakeupReasons_533050" 197 "WakeupReasons_265937" 196 "WakeupReasons_108834" 195 "WakeupReasons_636556" 194 "WakeupReasons_655340" 193 "WakeupReasons_320895" 192 "WakeupReasons_321077" 191 "WakeupReasons_321323" 190 "WakeupReasons_321319" 189 "WakeupReasons_321057" 188 "WakeupReasons_359187" 187 "WakeupReasons_321317" 186 "WakeupReasons_355214" 185 "WakeupReasons_652361" 184 "WakeupReasons_192030" 183 "WakeupReasons_534145" 182 "WakeupReasons_526445" 181 "WakeupReasons_360299" 180 "WakeupReasons_525705" 179 "WakeupReasons_534077" 178 "WakeupReasons_359211" 177 "WakeupReasons_300681" 176 "WakeupReasons_198484" 175 "WakeupReasons_356549" 174 "WakeupReasons_360543" 173 "WakeupReasons_318342" 172 "WakeupReasons_299547" 171 "WakeupReasons_646109" 170 "WakeupReasons_645753" 169 "WakeupReasons_514502" 168 "WakeupReasons_515804" 167 "WakeupReasons_298808" 166 "WakeupReasons_265330" 165 "WakeupReasons_265328" 164 "WakeupReasons_265305" 163 "WakeupReasons_361279" 162 "WakeupReasons_361272" 161 "WakeupReasons_160596" 160 "WakeupReasons_197648" 159 "WakeupReasons_658603" 158 "WakeupReasons_322857" 157 "WakeupReasons_108810" 156 "WakeupReasons_179103" 155 "WakeupReasons_321845" 154 "WakeupReasons_340667" 153 "WakeupReasons_299117" 152 "WakeupReasons_514503" 151 "WakeupReasons_532007" 150 "WakeupReasons_337565" 149 "WakeupReasons_320631" 148 "WakeupReasons_354791" 147 "WakeupReasons_317616" 146 "WakeupReasons_644550" 145 "WakeupReasons_265232" 144 "WakeupReasons_514545" 143 "WakeupReasons_526429" 142 "WakeupReasons_265569" 141 "WakeupReasons_108841" 140 "WakeupReasons_160602" 139 "WakeupReasons_160597" 138 "WakeupReasons_264958" 137 "WakeupReasons_300682" 136 "WakeupReasons_224634" 135 "WakeupReasons_224617" 134 "WakeupReasons_220322" 133 "WakeupReasons_300427" 132 "WakeupReasons_269156" 131 "WakeupReasons_145462" 130 "WakeupReasons_145454" 129 "WakeupReasons_145419" 128 "WakeupReasons_145288" 127 "WakeupReasons_145373" 126 "WakeupReasons_145385" 125 "WakeupReasons_145362" 124 "WakeupReasons_145399" 123 "WakeupReasons_145388" 122 "WakeupReasons_145330" 121 "WakeupReasons_152774" 120 "WakeupReasons_145319" 119 "WakeupReasons_145311" 118 "WakeupReasons_106774" 117 "WakeupReasons_533044" 116 "WakeupReasons_636692" 115 "WakeupReasons_355409" 114 "WakeupReasons_133749" 113 "WakeupReasons_156412" 112 "WakeupReasons_320287" 111 "WakeupReasons_201348" 110 "WakeupReasons_264962" 109 "WakeupReasons_169884" 108 "WakeupReasons_45867" 107 "WakeupReasons_45866" 106 "WakeupReasons_659549" 105 "WakeupReasons_45864" 104 "WakeupReasons_201815" 103 "WakeupReasons_224831" 102 "WakeupReasons_222553" 101 "WakeupReasons_140678" 100 "WakeupReasons_169945" 99 "WakeupReasons_95444" 98 "WakeupReasons_145688" 97 "WakeupReasons_356190" 96 "WakeupReasons_264934" 95 "WakeupReasons_264932" 94 "WakeupReasons_152786" 93 "WakeupReasons_144970" 92 "WakeupReasons_186489" 91 "WakeupReasons_144897" 90 "WakeupReasons_199172" 89 "WakeupReasons_145707" 88 "WakeupReasons_152237" 87 "WakeupReasons_67182" 86 "WakeupReasons_338820" 85 "WakeupReasons_634710" 84 "WakeupReasons_109387" 83 "WakeupReasons_320126" 82 "WakeupReasons_109367" 81 "WakeupReasons_315364" 80 "WakeupReasons_297868" 79 "WakeupReasons_645810" 78 "WakeupReasons_634696" 77 "WakeupReasons_138997" 76 "WakeupReasons_360006" 75 "WakeupReasons_224061" 74 "WakeupReasons_68481" 73 "WakeupReasons_109364" 72 "WakeupReasons_68644" 71 "WakeupReasons_224065" 70 "WakeupReasons_119273" 69 "WakeupReasons_109382" 68 "WakeupReasons_360008" 67 "WakeupReasons_68676" 66 "WakeupReasons_645094" 65 "WakeupReasons_361509" 64 "WakeupReasons_361505" 63 "WakeupReasons_360904" 62 "WakeupReasons_355601" 61 "WakeupReasons_320277" 60 "WakeupReasons_319422" 59 "WakeupReasons_320282" 58 "WakeupReasons_169894" 57 "WakeupReasons_266860" 56 "WakeupReasons_45656" 55 "WakeupReasons_21997" 54 "WakeupReasons_225696" 53 "WakeupReasons_200156" 52 "WakeupReasons_161066" 51 "WakeupReasons_185670" 50 "WakeupReasons_197826" 49 "WakeupReasons_176921" 48 "WakeupReasons_108776" 47 "WakeupReasons_265333" 46 "WakeupReasons_100281" 45 "WakeupReasons_100278" 44 "WakeupReasons_100300" 43 "WakeupReasons_100275" 42 "WakeupReasons_100298" 41 "WakeupReasons_319139" 40 "WakeupReasons_170807" 39 "WakeupReasons_200937" 38 "WakeupReasons_182033" 37 "WakeupReasons_191050" 36 "WakeupReasons_264876" 35 "WakeupReasons_197642" 34 "WakeupReasons_170865" 33 "WakeupReasons_168966" 32 "WakeupReasons_667948" 31 "WakeupReasons_169655" 30 "WakeupReasons_667945" 29 "WakeupReasons_74188" 28 "WakeupReasons_321583" 27 "WakeupReasons_88125" 26 "WakeupReasons_88123" 25 "WakeupReasons_91253" 24 "WakeupReasons_21973" 23 "WakeupReasons_140084" 22 "WakeupReasons_45657" 21 "WakeupReasons_45659" 20 "WakeupReasons_22100" 19 "WakeupReasons_22013" 18 "WakeupReasons_22005" 17 "WakeupReasons_45794" 16 "WakeupReasons_45793" 15 "WakeupReasons_21901" 14 "WakeupReasons_658500" 13 "WakeupReasons_269739" 12 "WakeupReasons_269735" 11 "WakeupReasons_269740" 10 "WakeupReasons_22060" 9 "WakeupReasons_49446" 8 "WakeupReasons_22058" 7 "WakeupReasons_45654" 6 "WakeupReasons_264933" 5 "WakeupReasons_197643" 4 "WakeupReasons_168965" 3 "WakeupReasons_667951" 2 "WakeupReasons_169654" 1 "WakeupReasons_667950" 0 "WakeupReasons_0";
VAL_ 1381 VFCVectorSUMVFCid0 1 "VFCOnOff_On" 0 "VFCOnOff_Off";
VAL_ 1381 VFCVectorSUMVFCid1 1 "VFCOnOff_On" 0 "VFCOnOff_Off";
VAL_ 1381 VFCVectorSUMVFCid10 1 "VFCOnOff_On" 0 "VFCOnOff_Off";
VAL_ 1381 VFCVectorSUMVFCid11 1 "VFCOnOff_On" 0 "VFCOnOff_Off";
VAL_ 1381 VFCVectorSUMVFCid12 1 "VFCOnOff_On" 0 "VFCOnOff_Off";
VAL_ 1381 VFCVectorSUMVFCid13 1 "VFCOnOff_On" 0 "VFCOnOff_Off";
VAL_ 1381 VFCVectorSUMVFCid14 1 "VFCOnOff_On" 0 "VFCOnOff_Off";
VAL_ 1381 VFCVectorSUMVFCid15 1 "VFCOnOff_On" 0 "VFCOnOff_Off";
VAL_ 1381 VFCVectorSUMVFCid16 1 "VFCOnOff_On" 0 "VFCOnOff_Off";
VAL_ 1381 VFCVectorSUMVFCid17 1 "VFCOnOff_On" 0 "VFCOnOff_Off";
VAL_ 1381 VFCVectorSUMVFCid18 1 "VFCOnOff_On" 0 "VFCOnOff_Off";
VAL_ 1381 VFCVectorSUMVFCid19 1 "VFCOnOff_On" 0 "VFCOnOff_Off";
VAL_ 1381 VFCVectorSUMVFCid2 1 "VFCOnOff_On" 0 "VFCOnOff_Off";
VAL_ 1381 VFCVectorSUMVFCid20 1 "VFCOnOff_On" 0 "VFCOnOff_Off";
VAL_ 1381 VFCVectorSUMVFCid21 1 "VFCOnOff_On" 0 "VFCOnOff_Off";
VAL_ 1381 VFCVectorSUMVFCid22 1 "VFCOnOff_On" 0 "VFCOnOff_Off";
VAL_ 1381 VFCVectorSUMVFCid23 1 "VFCOnOff_On" 0 "VFCOnOff_Off";
VAL_ 1381 VFCVectorSUMVFCid24 1 "VFCOnOff_On" 0 "VFCOnOff_Off";
VAL_ 1381 VFCVectorSUMVFCid25 1 "VFCOnOff_On" 0 "VFCOnOff_Off";
VAL_ 1381 VFCVectorSUMVFCid26 1 "VFCOnOff_On" 0 "VFCOnOff_Off";
VAL_ 1381 VFCVectorSUMVFCid27 1 "VFCOnOff_On" 0 "VFCOnOff_Off";
VAL_ 1381 VFCVectorSUMVFCid28 1 "VFCOnOff_On" 0 "VFCOnOff_Off";
VAL_ 1381 VFCVectorSUMVFCid29 1 "VFCOnOff_On" 0 "VFCOnOff_Off";
VAL_ 1381 VFCVectorSUMVFCid3 1 "VFCOnOff_On" 0 "VFCOnOff_Off";
VAL_ 1381 VFCVectorSUMVFCid30 1 "VFCOnOff_On" 0 "VFCOnOff_Off";
VAL_ 1381 VFCVectorSUMVFCid31 1 "VFCOnOff_On" 0 "VFCOnOff_Off";
VAL_ 1381 VFCVectorSUMVFCid32 1 "VFCOnOff_On" 0 "VFCOnOff_Off";
VAL_ 1381 VFCVectorSUMVFCid33 1 "VFCOnOff_On" 0 "VFCOnOff_Off";
VAL_ 1381 VFCVectorSUMVFCid34 1 "VFCOnOff_On" 0 "VFCOnOff_Off";
VAL_ 1381 VFCVectorSUMVFCid35 1 "VFCOnOff_On" 0 "VFCOnOff_Off";
VAL_ 1381 VFCVectorSUMVFCid36 1 "VFCOnOff_On" 0 "VFCOnOff_Off";
VAL_ 1381 VFCVectorSUMVFCid37 1 "VFCOnOff_On" 0 "VFCOnOff_Off";
VAL_ 1381 VFCVectorSUMVFCid38 1 "VFCOnOff_On" 0 "VFCOnOff_Off";
VAL_ 1381 VFCVectorSUMVFCid39 1 "VFCOnOff_On" 0 "VFCOnOff_Off";
VAL_ 1381 VFCVectorSUMVFCid4 1 "VFCOnOff_On" 0 "VFCOnOff_Off";
VAL_ 1381 VFCVectorSUMVFCid40 1 "VFCOnOff_On" 0 "VFCOnOff_Off";
VAL_ 1381 VFCVectorSUMVFCid41 1 "VFCOnOff_On" 0 "VFCOnOff_Off";
VAL_ 1381 VFCVectorSUMVFCid42 1 "VFCOnOff_On" 0 "VFCOnOff_Off";
VAL_ 1381 VFCVectorSUMVFCid43 1 "VFCOnOff_On" 0 "VFCOnOff_Off";
VAL_ 1381 VFCVectorSUMVFCid44 1 "VFCOnOff_On" 0 "VFCOnOff_Off";
VAL_ 1381 VFCVectorSUMVFCid45 1 "VFCOnOff_On" 0 "VFCOnOff_Off";
VAL_ 1381 VFCVectorSUMVFCid46 1 "VFCOnOff_On" 0 "VFCOnOff_Off";
VAL_ 1381 VFCVectorSUMVFCid47 1 "VFCOnOff_On" 0 "VFCOnOff_Off";
VAL_ 1381 VFCVectorSUMVFCid48 1 "VFCOnOff_On" 0 "VFCOnOff_Off";
VAL_ 1381 VFCVectorSUMVFCid49 1 "VFCOnOff_On" 0 "VFCOnOff_Off";
VAL_ 1381 VFCVectorSUMVFCid5 1 "VFCOnOff_On" 0 "VFCOnOff_Off";
VAL_ 1381 VFCVectorSUMVFCid50 1 "VFCOnOff_On" 0 "VFCOnOff_Off";
VAL_ 1381 VFCVectorSUMVFCid51 1 "VFCOnOff_On" 0 "VFCOnOff_Off";
VAL_ 1381 VFCVectorSUMVFCid52 1 "VFCOnOff_On" 0 "VFCOnOff_Off";
VAL_ 1381 VFCVectorSUMVFCid53 1 "VFCOnOff_On" 0 "VFCOnOff_Off";
VAL_ 1381 VFCVectorSUMVFCid54 1 "VFCOnOff_On" 0 "VFCOnOff_Off";
VAL_ 1381 VFCVectorSUMVFCid55 1 "VFCOnOff_On" 0 "VFCOnOff_Off";
VAL_ 1381 VFCVectorSUMVFCid56 1 "VFCOnOff_On" 0 "VFCOnOff_Off";
VAL_ 1381 VFCVectorSUMVFCid57 1 "VFCOnOff_On" 0 "VFCOnOff_Off";
VAL_ 1381 VFCVectorSUMVFCid58 1 "VFCOnOff_On" 0 "VFCOnOff_Off";
VAL_ 1381 VFCVectorSUMVFCid59 1 "VFCOnOff_On" 0 "VFCOnOff_Off";
VAL_ 1381 VFCVectorSUMVFCid6 1 "VFCOnOff_On" 0 "VFCOnOff_Off";
VAL_ 1381 VFCVectorSUMVFCid60 1 "VFCOnOff_On" 0 "VFCOnOff_Off";
VAL_ 1381 VFCVectorSUMVFCid61 1 "VFCOnOff_On" 0 "VFCOnOff_Off";
VAL_ 1381 VFCVectorSUMVFCid7 1 "VFCOnOff_On" 0 "VFCOnOff_Off";
VAL_ 1381 VFCVectorSUMVFCid8 1 "VFCOnOff_On" 0 "VFCOnOff_Off";
VAL_ 1381 VFCVectorSUMVFCid9 1 "VFCOnOff_On" 0 "VFCOnOff_Off";
VAL_ 784 HvFanEna 1 "OnOff1_On" 0 "OnOff1_Off";
VAL_ 1285 WakeUpReasonsforECM 741 "WakeupReasons_871868" 740 "WakeupReasons_871957" 739 "WakeupReasons_871729" 738 "WakeupReasons_700779" 737 "WakeupReasons_839414" 736 "WakeupReasons_675025" 735 "WakeupReasons_671146" 734 "WakeupReasons_1031929" 733 "WakeupReasons_1033548" 732 "WakeupReasons_1033537" 731 "WakeupReasons_1033479" 730 "WakeupReasons_1030765" 729 "WakeupReasons_1028674" 728 "WakeupReasons_1033567" 727 "WakeupReasons_1033543" 726 "WakeupReasons_1033549" 725 "WakeupReasons_1033554" 724 "WakeupReasons_1033563" 723 "WakeupReasons_1033558" 722 "WakeupReasons_1029384" 721 "WakeupReasons_1029383" 720 "WakeupReasons_1029382" 719 "WakeupReasons_1032619" 718 "WakeupReasons_1024928" 717 "WakeupReasons_1033547" 716 "WakeupReasons_1033541" 715 "WakeupReasons_1033562" 714 "WakeupReasons_1033564" 713 "WakeupReasons_986765" 712 "WakeupReasons_1026103" 711 "WakeupReasons_1030764" 710 "WakeupReasons_1030941" 709 "WakeupReasons_1033556" 708 "WakeupReasons_1033539" 707 "WakeupReasons_1033534" 706 "WakeupReasons_1032477" 705 "WakeupReasons_1031280" 704 "WakeupReasons_1033542" 703 "WakeupReasons_1033632" 702 "WakeupReasons_1033533" 701 "WakeupReasons_1029166" 700 "WakeupReasons_1033538" 699 "WakeupReasons_1031789" 698 "WakeupReasons_1033552" 697 "WakeupReasons_1033553" 696 "WakeupReasons_1033559" 695 "WakeupReasons_1033544" 694 "WakeupReasons_1033561" 693 "WakeupReasons_1031029" 692 "WakeupReasons_1030360" 691 "WakeupReasons_1030761" 690 "WakeupReasons_1033550" 689 "WakeupReasons_1032579" 688 "WakeupReasons_1033557" 687 "WakeupReasons_1031936" 686 "WakeupReasons_1033566" 685 "WakeupReasons_1033551" 684 "WakeupReasons_1033540" 683 "WakeupReasons_1030760" 682 "WakeupReasons_1029735" 681 "WakeupReasons_1033565" 680 "WakeupReasons_852370" 679 "WakeupReasons_1033555" 678 "WakeupReasons_1033546" 677 "WakeupReasons_1032743" 676 "WakeupReasons_1032791" 675 "WakeupReasons_1033569" 674 "WakeupReasons_1031030" 673 "WakeupReasons_1028778" 672 "WakeupReasons_1030759" 671 "WakeupReasons_1031907" 670 "WakeupReasons_1033560" 669 "WakeupReasons_1031288" 668 "WakeupReasons_1030302" 667 "WakeupReasons_1031765" 666 "WakeupReasons_1031990" 665 "WakeupReasons_1028729" 664 "WakeupReasons_1030362" 663 "WakeupReasons_1030361" 662 "WakeupReasons_1030297" 661 "WakeupReasons_1030293" 660 "WakeupReasons_527345" 659 "WakeupReasons_988154" 658 "WakeupReasons_533580" 657 "WakeupReasons_533581" 656 "WakeupReasons_533576" 655 "WakeupReasons_1030255" 654 "WakeupReasons_527348" 653 "WakeupReasons_533578" 652 "WakeupReasons_527347" 651 "WakeupReasons_527346" 650 "WakeupReasons_ADCUReserve" 649 "WakeupReasons_885767" 648 "WakeupReasons_909025" 647 "WakeupReasons_909026" 646 "WakeupReasons_858177" 645 "WakeupReasons_858169" 644 "WakeupReasons_858152" 643 "WakeupReasons_973575" 642 "WakeupReason_973574" 641 "WakeupReason_987405" 640 "WakeupReason_858187" 639 "WakeupReason_988826" 638 "WakeupReason_988821" 637 "WakeupReason_987485" 636 "WakeupReason_908128" 635 "WakeupReason_908115" 634 "WakeupReason_856234" 633 "WakeupReason_856224" 632 "WakeupReason_858189" 631 "WakeupReason_858188" 630 "WakeupReason_872056" 629 "WakeupReason_870276" 628 "WakeupReason_858191" 627 "WakeupReason_847054" 626 "WakeupReason_856465" 625 "WakeupReason_872253" 624 "WakeupReason_855003" 623 "WakeupReason_855002" 622 "WakeupReason_854947" 621 "WakeupReason_855134" 620 "WakeupReason_854839" 619 "WakeupReason_854999" 618 "WakeupReason_855029" 617 "WakeupReason_714340" 616 "WakeupReason_852947" 615 "WakeupReason_852944" 614 "WakeupReason_852646" 613 "WakeupReason_852537" 612 "WakeupReason_852388" 611 "WakeupReason_852385" 610 "WakeupReason_852298" 609 "WakeupReason_852273" 608 "WakeupReason_852248" 607 "WakeupReason_852219" 606 "WakeupReason_852218" 605 "WakeupReason_852215" 604 "WakeupReason_852200" 603 "WakeupReason_852195" 602 "WakeupReason_852194" 601 "WakeupReason_852184" 600 "WakeupReason_852180" 599 "WakeupReason_852050" 598 "WakeupReason_852010" 597 "WakeupReason_851743" 596 "WakeupReason_851482" 595 "WakeupReason_702420" 594 "WakeupReason_667533" 593 "WakeupReason_645735" 592 "WakeupReason_362462" 591 "WakeupReason_361474" 590 "WakeupReason_361441" 589 "WakeupReason_846002" 588 "WakeupReason_845930" 587 "WakeupReason_842273" 586 "WakeupReason_846372" 585 "WakeupReason_675489" 584 "WakeupReason_675452" 583 "WakeupReason_298032" 582 "WakeupReason_322113" 581 "WakeupReason_320145" 580 "WakeupReason_841275" 579 "WakeupReason_839787" 578 "WakeupReason_839181" 577 "WakeupReason_714677" 576 "WakeupReason_840035" 566 "WakeupReason_839458" 565 "WakeupReason_837760" 564 "WakeupReason_702903" 563 "WakeupReason_837962" 562 "WakeupReason_703140" 561 "WakeupReason_837833" 560 "WakeupReason_839705" 559 "WakeupReason_839473" 558 "WakeupReason_838116" 557 "WakeupReason_717832" 556 "WakeupReason_714697" 555 "WakeupReason_714799" 554 "WakeupReason_714806" 553 "WakeupReason_709196" 552 "WakeupReason_710893" 551 "WakeupReason_708964" 550 "WakeupReason_715529" 549 "WakeupReason_714265" 548 "WakeupReason_714172" 547 "WakeupReason_713799" 546 "WakeupReason_706194" 545 "WakeupReason_713568" 544 "WakeupReason_710807" 543 "WakeupReason_714679" 542 "WakeupReason_714678" 541 "WakeupReason_715842" 540 "WakeupReason_714030" 539 "WakeupReason_710922" 538 "WakeupReason_716243" 537 "WakeupReason_713786" 536 "WakeupReason_714675" 535 "WakeupReason_702478" 534 "WakeupReason_713752" 533 "WakeupReasons_700530" 532 "WakeupReasons_698631" 531 "WakeupReasons_702452" 530 "WakeupReasons_700565" 529 "WakeupReasons_702402" 528 "WakeupReasons_702439" 527 "WakeupReasons_702448" 526 "WakeupReasons_701872" 525 "WakeupReasons_699114" 524 "WakeupReasons_702240" 523 "WakeupReasons_701270" 522 "WakeupReasons_533751" 521 "WakeupReasons_698581" 520 "WakeupReasons_698130" 519 "WakeupReasons_700130" 518 "WakeupReasons_699921" 517 "WakeupReasons_699919" 516 "WakeupReasons_700486" 515 "WakeupReasons_700782" 514 "WakeupReasons_696971" 513 "WakeupReasons_700692" 512 "WakeupReasons_698385" 511 "WakeupReasons_699922" 510 "WakeupReasons_697967" 509 "WakeupReasons_700684" 508 "WakeupReasons_644379" 507 "WakeupReasons_336435" 506 "WakeupReasons_683263" 505 "WakeupReasons_700554" 504 "WakeupReasons_691992" 503 "WakeupReasons_698129" 502 "WakeupReasons_696850" 501 "WakeupReasons_702088" 500 "WakeupReasons_696612" 499 "WakeupReasons_691994" 498 "WakeupReasons_700483" 497 "WakeupReasons_702204" 496 "WakeupReasons_700603" 495 "WakeupReasons_700215" 494 "WakeupReasons_701509" 493 "WakeupReasons_701508" 492 "WakeupReasons_700484" 491 "WakeupReasons_217907" 490 "WakeupReasons_194966" 489 "WakeupReasons_702174" 488 "WakeupReasons_697145" 487 "WakeupReasons_296931" 486 "WakeupReasons_700687" 485 "WakeupReasons_700686" 484 "WakeupReasons_698409" 483 "WakeupReasons_533750" 482 "WakeupReasons_700467" 481 "WakeupReasons_687404" 480 "WakeupReasons_681813" 479 "WakeupReasons_698288" 478 "WakeupReasons_698660" 477 "WakeupReasons_691993" 476 "WakeupReasons_700485" 475 "WakeupReasons_700425" 474 "WakeupReasons_702197" 473 "WakeupReasons_637992" 472 "WakeupReasons_698488" 471 "WakeupReasons_691991" 470 "WakeupReasons_692547" 469 "WakeupReasons_693914" 468 "WakeupReasons_693024" 467 "WakeupReasons_693005" 466 "WakeupReasons_667949" 465 "WakeupReasons_686281" 464 "WakeupReasons_680764" 463 "WakeupReasons_512384" 462 "WakeupReasons_692019" 461 "WakeupReasons_533850" 460 "WakeupReasons_533849" 459 "WakeupReasons_667188" 458 "WakeupReasons_514652" 457 "WakeupReasons_514651" 456 "WakeupReasons_112024" 455 "WakeupReasons_300690" 454 "WakeupReasons_299532" 453 "WakeupReasons_299531" 452 "WakeupReasons_299120" 451 "WakeupReasons_273516" 450 "WakeupReasons_265694" 449 "WakeupReasons_692439" 448 "WakeupReasons_354831" 447 "WakeupReasons_680765" 446 "WakeupReasons_45895" 445 "WakeupReasons_644275" 444 "WakeupReasons_351189" 443 "WakeupReasons_226570" 442 "WakeupReasons_654489" 441 "WakeupReasons_110181" 440 "WakeupReasons_226569" 439 "WakeupReasons_45896" 438 "WakeupReasons_112031" 437 "WakeupReasons_110173" 436 "WakeupReasons_677781" 435 "WakeupReasons_690939" 434 "WakeupReasons_354809" 433 "WakeupReasons_692022" 432 "WakeupReasons_690593" 431 "WakeupReasons_226571" 430 "WakeupReasons_675594" 429 "WakeupReasons_226565" 428 "WakeupReasons_692020" 427 "WakeupReasons_112035" 426 "WakeupReasons_112027" 425 "WakeupReasons_354672" 424 "WakeupReasons_168967" 423 "WakeupReasons_354674" 422 "WakeupReasons_168968" 421 "WakeupReasons_641483" 420 "WakeupReasons_641482" 419 "WakeupReasons_265698" 418 "WakeupReasons_265699" 417 "WakeupReasons_360491" 416 "WakeupReasons_357498" 415 "WakeupReasons_170290" 414 "WakeupReasons_690385" 413 "WakeupReasons_692021" 412 "WakeupReasons_91254" 411 "WakeupReasons_346654" 410 "WakeupReasons_200637" 409 "WakeupReasons_170285" 408 "WakeupReasons_265678" 407 "WakeupReasons_683934" 406 "WakeupReasons_680763" 405 "WakeupReasons_682074" 404 "WakeupReasons_682154" 403 "WakeupReasons_682152" 402 "WakeupReasons_682155" 401 "WakeupReasons_682153" 400 "WakeupReasons_682078" 399 "WakeupReasons_682076" 398 "WakeupReasons_682077" 397 "WakeupReasons_676285" 396 "WakeupReasons_681023" 395 "WakeupReasons_682023" 394 "WakeupReasons_681789" 393 "WakeupReasons_682688" 392 "WakeupReasons_682037" 391 "WakeupReasons_682032" 390 "WakeupReasons_681915" 389 "WakeupReasons_674839" 388 "WakeupReasons_682034" 387 "WakeupReasons_681711" 386 "WakeupReasons_681031" 385 "WakeupReasons_681134" 384 "WakeupReasons_670462" 383 "WakeupReasons_681028" 382 "WakeupReasons_680975" 381 "WakeupReasons_680974" 380 "WakeupReasons_668523" 379 "WakeupReasons_669822" 378 "WakeupReasons_680712" 377 "WakeupReasons_671005" 376 "WakeupReasons_177214" 375 "WakeupReasons_45655" 374 "WakeupReasons_667872" 373 "WakeupReasons_264964" 372 "WakeupReasons_262871" 371 "WakeupReasons_264691" 370 "WakeupReasons_297056" 369 "WakeupReasons_233755" 368 "WakeupReasons_145161" 367 "WakeupReasons_667842" 366 "WakeupReasons_46020" 365 "WakeupReasons_667874" 364 "WakeupReasons_667981" 363 "WakeupReasons_224211" 362 "WakeupReasons_45902" 361 "WakeupReasons_329457" 360 "WakeupReasons_88458" 359 "WakeupReasons_45900" 358 "WakeupReasons_83199" 357 "WakeupReasons_532933" 356 "WakeupReasons_532932" 355 "WakeupReasons_670942" 354 "WakeupReasons_305818" 353 "WakeupReasons_75103" 352 "WakeupReasons_667987" 351 "WakeupReasons_667983" 350 "WakeupReasons_675745" 349 "WakeupReasons_356598" 348 "WakeupReasons_128671" 347 "WakeupReasons_69216" 346 "WakeupReasons_264697" 345 "WakeupReasons_264943" 344 "WakeupReasons_197644" 343 "WakeupReasons_675564" 342 "WakeupReasons_657120" 341 "WakeupReasons_265745" 340 "WakeupReasons_657121" 339 "WakeupReasons_667982" 338 "WakeupReasons_674223" 337 "WakeupReasons_127926" 336 "WakeupReasons_127924" 335 "WakeupReasons_262872" 334 "WakeupReasons_45848" 333 "WakeupReasons_45847" 332 "WakeupReasons_45846" 331 "WakeupReasons_667869" 330 "WakeupReasons_45890" 329 "WakeupReasons_45888" 328 "WakeupReasons_670962" 327 "WakeupReasons_667973" 326 "WakeupReasons_45877" 325 "WakeupReasons_667980" 324 "WakeupReasons_45876" 323 "WakeupReasons_45871" 322 "WakeupReasons_45875" 321 "WakeupReasons_45872" 320 "WakeupReasons_45870" 319 "WakeupReasons_45869" 318 "WakeupReasons_80608" 317 "WakeupReasons_45898" 316 "WakeupReasons_45897" 315 "WakeupReasons_69679" 314 "WakeupReasons_69678" 313 "WakeupReasons_45887" 312 "WakeupReasons_263473" 311 "WakeupReasons_265131" 310 "WakeupReasons_268983" 309 "WakeupReasons_139075" 308 "WakeupReasons_200090" 307 "WakeupReasons_199714" 306 "WakeupReasons_80609" 305 "WakeupReasons_106669" 304 "WakeupReasons_675742" 303 "WakeupReasons_46017" 302 "WakeupReasons_670354" 301 "WakeupReasons_667985" 300 "WakeupReasons_670966" 299 "WakeupReasons_667871" 298 "WakeupReasons_193474" 297 "WakeupReasons_113348" 296 "WakeupReasons_532556" 295 "WakeupReasons_532555" 294 "WakeupReasons_667988" 293 "WakeupReasons_182918" 292 "WakeupReasons_311279" 291 "WakeupReasons_667848" 290 "WakeupReasons_667850" 289 "WakeupReasons_668393" 288 "WakeupReasons_668395" 287 "WakeupReasons_670753" 286 "WakeupReasons_667922" 285 "WakeupReasons_669447" 284 "WakeupReasons_670928" 283 "WakeupReasons_669465" 282 "WakeupReasons_676265" 281 "WakeupReasons_667947" 280 "WakeupReasons_667879" 279 "WakeupReasons_675837" 278 "WakeupReasons_675494" 277 "WakeupReasons_674958" 276 "WakeupReasons_675064" 275 "WakeupReasons_674953" 274 "WakeupReasons_658188" 273 "WakeupReasons_337991" 272 "WakeupReasons_197653" 271 "WakeupReasons_269140" 270 "WakeupReasons_312881" 269 "WakeupReasons_215560" 268 "WakeupReasons_269034" 267 "WakeupReasons_4471" 266 "WakeupReasons_185490" 265 "WakeupReasons_185457" 264 "WakeupReasons_198452" 263 "WakeupReasons_200683" 262 "WakeupReasons_358832" 261 "WakeupReasons_NMPDUReceived" 260 "WakeupReasons_670345" 259 "WakeupReasons_109467" 258 "WakeupReasons_109466" 257 "WakeupReasons_636801" 256 "WakeupReasons_45849" 255 "WakeupReasons_45850" 254 "WakeupReasons_45851" 253 "WakeupReasons_45852" 252 "WakeupReasons_45854" 251 "WakeupReasons_45853" 250 "WakeupReasons_45856" 249 "WakeupReasons_533872" 248 "WakeupReasons_516327" 247 "WakeupReasons_359559" 246 "WakeupReasons_241902" 245 "WakeupReasons_533372" 244 "WakeupReasons_533371" 243 "WakeupReasons_533370" 242 "WakeupReasons_315981" 241 "WakeupReasons_45858" 240 "WakeupReasons_668529" 239 "WakeupReasons_670087" 238 "WakeupReasons_668531" 237 "WakeupReasons_223920" 236 "WakeupReasons_176748" 235 "WakeupReasons_146470" 234 "WakeupReasons_112799" 233 "WakeupReasons_95949" 232 "WakeupReasons_156440" 231 "WakeupReasons_166267" 230 "WakeupReasons_101727" 229 "WakeupReasons_101728" 228 "WakeupReasons_101725" 227 "WakeupReasons_101706" 226 "WakeupReasons_659350" 225 "WakeupReasons_667820" 224 "WakeupReasons_331194" 223 "WakeupReasons_652546" 222 "WakeupReasons_224553" 221 "WakeupReasons_224552" 220 "WakeupReasons_110885" 219 "WakeupReasons_667953" 218 "WakeupReasons_667962" 217 "WakeupReasons_224550" 216 "WakeupReasons_197665" 215 "WakeupReasons_225961" 214 "WakeupReasons_198433" 213 "WakeupReasons_526438" 212 "WakeupReasons_316796" 211 "WakeupReasons_335068" 210 "WakeupReasons_535214" 209 "WakeupReasons_264726" 208 "WakeupReasons_360542" 207 "WakeupReasons_531743" 206 "WakeupReasons_226967" 205 "WakeupReasons_318382" 204 "WakeupReasons_199159" 203 "WakeupReasons_223715" 202 "WakeupReasons_643973" 201 "WakeupReasons_319401" 200 "WakeupReasons_264712" 199 "WakeupReasons_526426" 198 "WakeupReasons_533050" 197 "WakeupReasons_265937" 196 "WakeupReasons_108834" 195 "WakeupReasons_636556" 194 "WakeupReasons_655340" 193 "WakeupReasons_320895" 192 "WakeupReasons_321077" 191 "WakeupReasons_321323" 190 "WakeupReasons_321319" 189 "WakeupReasons_321057" 188 "WakeupReasons_359187" 187 "WakeupReasons_321317" 186 "WakeupReasons_355214" 185 "WakeupReasons_652361" 184 "WakeupReasons_192030" 183 "WakeupReasons_534145" 182 "WakeupReasons_526445" 181 "WakeupReasons_360299" 180 "WakeupReasons_525705" 179 "WakeupReasons_534077" 178 "WakeupReasons_359211" 177 "WakeupReasons_300681" 176 "WakeupReasons_198484" 175 "WakeupReasons_356549" 174 "WakeupReasons_360543" 173 "WakeupReasons_318342" 172 "WakeupReasons_299547" 171 "WakeupReasons_646109" 170 "WakeupReasons_645753" 169 "WakeupReasons_514502" 168 "WakeupReasons_515804" 167 "WakeupReasons_298808" 166 "WakeupReasons_265330" 165 "WakeupReasons_265328" 164 "WakeupReasons_265305" 163 "WakeupReasons_361279" 162 "WakeupReasons_361272" 161 "WakeupReasons_160596" 160 "WakeupReasons_197648" 159 "WakeupReasons_658603" 158 "WakeupReasons_322857" 157 "WakeupReasons_108810" 156 "WakeupReasons_179103" 155 "WakeupReasons_321845" 154 "WakeupReasons_340667" 153 "WakeupReasons_299117" 152 "WakeupReasons_514503" 151 "WakeupReasons_532007" 150 "WakeupReasons_337565" 149 "WakeupReasons_320631" 148 "WakeupReasons_354791" 147 "WakeupReasons_317616" 146 "WakeupReasons_644550" 145 "WakeupReasons_265232" 144 "WakeupReasons_514545" 143 "WakeupReasons_526429" 142 "WakeupReasons_265569" 141 "WakeupReasons_108841" 140 "WakeupReasons_160602" 139 "WakeupReasons_160597" 138 "WakeupReasons_264958" 137 "WakeupReasons_300682" 136 "WakeupReasons_224634" 135 "WakeupReasons_224617" 134 "WakeupReasons_220322" 133 "WakeupReasons_300427" 132 "WakeupReasons_269156" 131 "WakeupReasons_145462" 130 "WakeupReasons_145454" 129 "WakeupReasons_145419" 128 "WakeupReasons_145288" 127 "WakeupReasons_145373" 126 "WakeupReasons_145385" 125 "WakeupReasons_145362" 124 "WakeupReasons_145399" 123 "WakeupReasons_145388" 122 "WakeupReasons_145330" 121 "WakeupReasons_152774" 120 "WakeupReasons_145319" 119 "WakeupReasons_145311" 118 "WakeupReasons_106774" 117 "WakeupReasons_533044" 116 "WakeupReasons_636692" 115 "WakeupReasons_355409" 114 "WakeupReasons_133749" 113 "WakeupReasons_156412" 112 "WakeupReasons_320287" 111 "WakeupReasons_201348" 110 "WakeupReasons_264962" 109 "WakeupReasons_169884" 108 "WakeupReasons_45867" 107 "WakeupReasons_45866" 106 "WakeupReasons_659549" 105 "WakeupReasons_45864" 104 "WakeupReasons_201815" 103 "WakeupReasons_224831" 102 "WakeupReasons_222553" 101 "WakeupReasons_140678" 100 "WakeupReasons_169945" 99 "WakeupReasons_95444" 98 "WakeupReasons_145688" 97 "WakeupReasons_356190" 96 "WakeupReasons_264934" 95 "WakeupReasons_264932" 94 "WakeupReasons_152786" 93 "WakeupReasons_144970" 92 "WakeupReasons_186489" 91 "WakeupReasons_144897" 90 "WakeupReasons_199172" 89 "WakeupReasons_145707" 88 "WakeupReasons_152237" 87 "WakeupReasons_67182" 86 "WakeupReasons_338820" 85 "WakeupReasons_634710" 84 "WakeupReasons_109387" 83 "WakeupReasons_320126" 82 "WakeupReasons_109367" 81 "WakeupReasons_315364" 80 "WakeupReasons_297868" 79 "WakeupReasons_645810" 78 "WakeupReasons_634696" 77 "WakeupReasons_138997" 76 "WakeupReasons_360006" 75 "WakeupReasons_224061" 74 "WakeupReasons_68481" 73 "WakeupReasons_109364" 72 "WakeupReasons_68644" 71 "WakeupReasons_224065" 70 "WakeupReasons_119273" 69 "WakeupReasons_109382" 68 "WakeupReasons_360008" 67 "WakeupReasons_68676" 66 "WakeupReasons_645094" 65 "WakeupReasons_361509" 64 "WakeupReasons_361505" 63 "WakeupReasons_360904" 62 "WakeupReasons_355601" 61 "WakeupReasons_320277" 60 "WakeupReasons_319422" 59 "WakeupReasons_320282" 58 "WakeupReasons_169894" 57 "WakeupReasons_266860" 56 "WakeupReasons_45656" 55 "WakeupReasons_21997" 54 "WakeupReasons_225696" 53 "WakeupReasons_200156" 52 "WakeupReasons_161066" 51 "WakeupReasons_185670" 50 "WakeupReasons_197826" 49 "WakeupReasons_176921" 48 "WakeupReasons_108776" 47 "WakeupReasons_265333" 46 "WakeupReasons_100281" 45 "WakeupReasons_100278" 44 "WakeupReasons_100300" 43 "WakeupReasons_100275" 42 "WakeupReasons_100298" 41 "WakeupReasons_319139" 40 "WakeupReasons_170807" 39 "WakeupReasons_200937" 38 "WakeupReasons_182033" 37 "WakeupReasons_191050" 36 "WakeupReasons_264876" 35 "WakeupReasons_197642" 34 "WakeupReasons_170865" 33 "WakeupReasons_168966" 32 "WakeupReasons_667948" 31 "WakeupReasons_169655" 30 "WakeupReasons_667945" 29 "WakeupReasons_74188" 28 "WakeupReasons_321583" 27 "WakeupReasons_88125" 26 "WakeupReasons_88123" 25 "WakeupReasons_91253" 24 "WakeupReasons_21973" 23 "WakeupReasons_140084" 22 "WakeupReasons_45657" 21 "WakeupReasons_45659" 20 "WakeupReasons_22100" 19 "WakeupReasons_22013" 18 "WakeupReasons_22005" 17 "WakeupReasons_45794" 16 "WakeupReasons_45793" 15 "WakeupReasons_21901" 14 "WakeupReasons_658500" 13 "WakeupReasons_269739" 12 "WakeupReasons_269735" 11 "WakeupReasons_269740" 10 "WakeupReasons_22060" 9 "WakeupReasons_49446" 8 "WakeupReasons_22058" 7 "WakeupReasons_45654" 6 "WakeupReasons_264933" 5 "WakeupReasons_197643" 4 "WakeupReasons_168965" 3 "WakeupReasons_667951" 2 "WakeupReasons_169654" 1 "WakeupReasons_667950" 0 "WakeupReasons_0";
SIG_GROUP_ 1353 VFCVectorHVFM 1 : VFCVectorHVFMVFCid8 VFCVectorHVFMVFCid48 VFCVectorHVFMVFCid45 VFCVectorHVFMVFCid35 VFCVectorHVFMVFCid28 VFCVectorHVFMVFCid22 VFCVectorHVFMVFCid49 VFCVectorHVFMVFCid47 VFCVectorHVFMVFCid0 VFCVectorHVFMVFCid61 VFCVectorHVFMVFCid60 VFCVectorHVFMVFCid34 VFCVectorHVFMVFCid27 VFCVectorHVFMVFCid29 VFCVectorHVFMVFCid58 VFCVectorHVFMVFCid46 VFCVectorHVFMVFCid10 VFCVectorHVFMVFCid37 VFCVectorHVFMVFCid6 VFCVectorHVFMVFCid42 VFCVectorHVFMVFCid59 VFCVectorHVFMVFCid39 VFCVectorHVFMVFCid11 VFCVectorHVFMVFCid43 VFCVectorHVFMVFCid4 VFCVectorHVFMVFCid54 VFCVectorHVFMVFCid44 VFCVectorHVFMVFCid9 VFCVectorHVFMVFCid3 VFCVectorHVFMVFCid13 VFCVectorHVFMVFCid12 VFCVectorHVFMVFCid20 VFCVectorHVFMBlockID VFCVectorHVFMVFCid41 VFCVectorHVFMVFCid21 VFCVectorHVFMVFCid7 VFCVectorHVFMVFCid30 VFCVectorHVFMVFCid18 VFCVectorHVFMVFCid51 VFCVectorHVFMVFCid24 VFCVectorHVFMVFCid33 VFCVectorHVFMVFCid38 VFCVectorHVFMVFCid17 VFCVectorHVFMVFCid15 VFCVectorHVFMVFCid56 VFCVectorHVFMVFCid23 VFCVectorHVFMVFCid19 VFCVectorHVFMVFCid5 VFCVectorHVFMVFCid36 VFCVectorHVFMVFCid1 VFCVectorHVFMVFCid57 VFCVectorHVFMVFCid32 VFCVectorHVFMVFCid31 VFCVectorHVFMVFCid53 VFCVectorHVFMVFCid2 VFCVectorHVFMVFCid40 VFCVectorHVFMVFCid16 VFCVectorHVFMVFCid50 VFCVectorHVFMVFCid52 VFCVectorHVFMVFCid14 VFCVectorHVFMVFCid26 VFCVectorHVFMVFCid25 VFCVectorHVFMVFCid55;
SIG_GROUP_ 81 TVCBrkTqReq 1 : TVCBrkTqReqReLeCtrlMod TVCBrkTqReqWhlVAgrMinReqFrntRi TVCBrkTqReqWhlVAgrMinReqReLe TVCBrkTqReqWhlVAgrMinReqFrntLe TVCBrkTqReqFrntRi TVCBrkTqReqReLe TVCBrkTqReqCntr TVCBrkTqReqChks TVCBrkTqReqFrntLe TVCBrkTqReqReRi TVCBrkTqReqFrntRiCtrlMod TVCBrkTqReqWhlVAgrMinReqReRi TVCBrkTqReqReRiCtrlMod TVCBrkTqReqFrntLeCtrlMod;
SIG_GROUP_ 81 TVCRwsAngReqForTvc 1 : TVCRwsAngReqForTvcCntr TVCRwsAngReqForTvcTVCRwsAngReqForTvc TVCRwsAngReqForTvcChks;
SIG_GROUP_ 81 TVCReWhlSteerCtrlStsForTvc 1 : TVCReWhlSteerCtrlStsForTvcChks TVCReWhlSteerCtrlStsForTvcTVCReWhlSteerCtrlStsForTvc TVCReWhlSteerCtrlStsForTvcCntr;
SIG_GROUP_ 81 TVCTqDistbnFaultForGVMC 1 : TVCTqDistbnFaultForGVMCCntr TVCTqDistbnFaultForGVMCChks TVCTqDistbnFaultForGVMCTVCTqDistbnFaultForGVMC;
SIG_GROUP_ 257 MotDynCtrlStsReLe 1 : MotDynCtrlStsReLeDmcActAppTarTq MotDynCtrlStsReLeDmcSWInfo MotDynCtrlStsReLeChks MotDynCtrlStsReLeDmcSts MotDynCtrlStsReLeCntr;
SIG_GROUP_ 257 MotDynCtrlStsReRi 1 : MotDynCtrlStsReRiDmcSts MotDynCtrlStsReRiCntr MotDynCtrlStsReRiDmcSWInfo MotDynCtrlStsReRiChks MotDynCtrlStsReRiDmcActAppTarTq;
SIG_GROUP_ 50 IntgtIMUDataRawSafe 1 : IntgtIMUDataRawSafeYawRateQf IntgtIMUDataRawSafeRollRateQf IntgtIMUDataRawSafeAvert IntgtIMUDataRawSafeYawRate IntgtIMUDataRawSafeCntr IntgtIMUDataRawSafeRollRate IntgtIMUDataRawSafeALat IntgtIMUDataRawSafeChks IntgtIMUDataRawSafePitchRateQf IntgtIMUDataRawSafeALgt1Qf IntgtIMUDataRawSafePitchRate IntgtIMUDataRawSafeALat1Qf IntgtIMUDataRawSafeALgt IntgtIMUDataRawSafeAVertQf;
SIG_GROUP_ 50 ADataRawSafe 1 : ADataRawSafeAVertQf ADataRawSafeALat ADataRawSafeAVert ADataRawSafeChks ADataRawSafeCntr ADataRawSafeALgt ADataRawSafeALgt1Qf ADataRawSafeALat1Qf;
SIG_GROUP_ 50 AgDataRawSafe 1 : AgDataRawSafeRollRateQf AgDataRawSafeYawRateQf AgDataRawSafeChks AgDataRawSafeCntr AgDataRawSafeRollRate AgDataRawSafeYawRate;
SIG_GROUP_ 50 AsyDataWithCmpSafe 1 : AsyDataWithCmpSafeGrdtOfALgt AsyDataWithCmpSafeALgt1Qf AsyDataWithCmpSafeALatWithCmp AsyDataWithCmpSafeALat1Qf AsyDataWithCmpSafeYawRateQf AsyDataWithCmpSafeCntr AsyDataWithCmpSafeYawRateWithCmp AsyDataWithCmpSafeChks;
SIG_GROUP_ 63 CrashStsSafe 1 : CrashStsSafeCntr CrashStsSafeSts CrashStsSafeChks;
SIG_GROUP_ 553 AgDataCmpQuality 1 : AgDataCmpQualityPitchRateCmpQuality AgDataCmpQualityRollRateCmpQuality AgDataCmpQualityYawRateCmpQuality;
SIG_GROUP_ 1350 VFCVectorSRS 1 : VFCVectorSRSVFCid9 VFCVectorSRSVFCid58 VFCVectorSRSVFCid56 VFCVectorSRSVFCid41 VFCVectorSRSVFCid34 VFCVectorSRSVFCid2 VFCVectorSRSVFCid50 VFCVectorSRSVFCid39 VFCVectorSRSVFCid53 VFCVectorSRSVFCid11 VFCVectorSRSVFCid45 VFCVectorSRSVFCid3 VFCVectorSRSVFCid10 VFCVectorSRSVFCid25 VFCVectorSRSVFCid5 VFCVectorSRSVFCid21 VFCVectorSRSVFCid12 VFCVectorSRSVFCid54 VFCVectorSRSVFCid47 VFCVectorSRSVFCid38 VFCVectorSRSVFCid42 VFCVectorSRSVFCid52 VFCVectorSRSVFCid24 VFCVectorSRSVFCid60 VFCVectorSRSVFCid57 VFCVectorSRSVFCid49 VFCVectorSRSVFCid19 VFCVectorSRSVFCid4 VFCVectorSRSVFCid20 VFCVectorSRSVFCid8 VFCVectorSRSVFCid27 VFCVectorSRSVFCid29 VFCVectorSRSVFCid18 VFCVectorSRSVFCid17 VFCVectorSRSVFCid43 VFCVectorSRSVFCid48 VFCVectorSRSVFCid33 VFCVectorSRSVFCid1 VFCVectorSRSVFCid32 VFCVectorSRSBlockID VFCVectorSRSVFCid51 VFCVectorSRSVFCid36 VFCVectorSRSVFCid7 VFCVectorSRSVFCid28 VFCVectorSRSVFCid0 VFCVectorSRSVFCid46 VFCVectorSRSVFCid14 VFCVectorSRSVFCid15 VFCVectorSRSVFCid26 VFCVectorSRSVFCid37 VFCVectorSRSVFCid13 VFCVectorSRSVFCid30 VFCVectorSRSVFCid55 VFCVectorSRSVFCid6 VFCVectorSRSVFCid35 VFCVectorSRSVFCid22 VFCVectorSRSVFCid40 VFCVectorSRSVFCid59 VFCVectorSRSVFCid44 VFCVectorSRSVFCid31 VFCVectorSRSVFCid16 VFCVectorSRSVFCid61 VFCVectorSRSVFCid23;
SIG_GROUP_ 448 SuspStfnVlvCtrlStsFb 1 : SuspStfnVlvCtrlStsFbFL SuspStfnVlvCtrlStsFbRL SuspStfnVlvCtrlStsFbRR SuspStfnVlvCtrlStsFbFR;
SIG_GROUP_ 1381 VFCVectorSUM 1 : VFCVectorSUMVFCid10 VFCVectorSUMVFCid5 VFCVectorSUMVFCid18 VFCVectorSUMVFCid26 VFCVectorSUMVFCid22 VFCVectorSUMVFCid24 VFCVectorSUMVFCid57 VFCVectorSUMVFCid49 VFCVectorSUMVFCid47 VFCVectorSUMVFCid40 VFCVectorSUMVFCid53 VFCVectorSUMVFCid1 VFCVectorSUMVFCid50 VFCVectorSUMVFCid4 VFCVectorSUMVFCid3 VFCVectorSUMVFCid56 VFCVectorSUMVFCid9 VFCVectorSUMVFCid23 VFCVectorSUMVFCid52 VFCVectorSUMVFCid54 VFCVectorSUMVFCid41 VFCVectorSUMVFCid58 VFCVectorSUMVFCid34 VFCVectorSUMVFCid31 VFCVectorSUMVFCid13 VFCVectorSUMVFCid59 VFCVectorSUMVFCid17 VFCVectorSUMVFCid39 VFCVectorSUMVFCid28 VFCVectorSUMVFCid43 VFCVectorSUMVFCid51 VFCVectorSUMVFCid2 VFCVectorSUMVFCid11 VFCVectorSUMVFCid25 VFCVectorSUMVFCid61 VFCVectorSUMVFCid44 VFCVectorSUMVFCid32 VFCVectorSUMVFCid27 VFCVectorSUMVFCid37 VFCVectorSUMVFCid46 VFCVectorSUMVFCid35 VFCVectorSUMVFCid38 VFCVectorSUMVFCid7 VFCVectorSUMVFCid6 VFCVectorSUMVFCid12 VFCVectorSUMVFCid16 VFCVectorSUMVFCid20 VFCVectorSUMVFCid14 VFCVectorSUMVFCid55 VFCVectorSUMVFCid42 VFCVectorSUMVFCid19 VFCVectorSUMVFCid29 VFCVectorSUMVFCid36 VFCVectorSUMVFCid45 VFCVectorSUMBlockID VFCVectorSUMVFCid48 VFCVectorSUMVFCid0 VFCVectorSUMVFCid8 VFCVectorSUMVFCid60 VFCVectorSUMVFCid33 VFCVectorSUMVFCid15 VFCVectorSUMVFCid30 VFCVectorSUMVFCid21;
